VERSION ""

NS_ :

BS_:

BU_: FUSION ZONE_FR ZONE_DR D21_DKC ZONE_FR_24

BO_ 796 ZONE_FR1: 64 ZONE_FR
 SG_ BMSReqRlngCtrHSC6 : 7|4@0+ (1,0) [0|15] ""  FUSION
 SG_ BMSReqTapPosHSC6 : 3|4@0+ (1,0) [0|15] ""  FUSION
 SG_ BMSReqPwrHSC6 : 15|16@0+ (1,0) [0|65535] ""  FUSION
 SG_ BMSReqPWMHSC6 : 31|7@0+ (1,0) [0|100] ""  FUSION
 SG_ BMSInptClntTemHSC6 : 24|9@0+ (0.5,-40) [-40|200] ""  FUSION
 SG_ BMSChksmHSC6 : 47|8@0+ (1,0) [0|255] ""  FUSION
 SG_ BMSReqMdHSC6 : 71|2@0+ (1,0) [0|3] ""  FUSION
 SG_ BMSEnbPTCHSC6 : 69|1@0+ (1,0) [0|1] ""  FUSION
 SG_ FRTurnLampC : 151|8@0+ (10,0) [0|2550] "mA"  FUSION
 SG_ FLTurnLampC : 159|8@0+ (10,0) [0|2550] "mA"  FUSION
 SG_ ChargeInletLockSta : 55|1@0+ (1,0) [0|1] ""  FUSION
 SG_ FWiperAS : 175|1@0+ (1,0) [0|1] ""  FUSION
 SG_ FWiperProtection : 174|1@0+ (1,0) [0|1] ""  FUSION
 SG_ BDC_1_ReqMovePos : 143|8@0+ (0.392,0) [0|99.96] ""  FUSION
 SG_ BDC_1_MoveEnable : 173|1@0+ (1,0) [0|1] ""  FUSION
 SG_ CCV4_MoveEnable : 168|1@0+ (1,0) [0|1] ""  FUSION
 SG_ CCV4_ReqMovePos : 169|1@0+ (1,0) [0|1] ""  FUSION
 SG_ CCM_SpdCmd : 54|15@0+ (0.5,0) [0|8300] "RPM"  FUSION
 SG_ BMSPackVol_h6HSC6 : 67|12@0+ (0.25,0) [0|1023.75] "V"  FUSION
 SG_ CompProEN : 68|1@0+ (1,0) [0|1] ""  FUSION
 SG_ EXV_Cmd_Set_Rq : 87|16@0+ (1,0) [0|65535] ""  FUSION
 SG_ EXV2_Cmd_Set_Rq : 103|16@0+ (1,0) [0|65535] ""  FUSION
 SG_ EWP3_RPM_Target_EWP_Rq : 135|8@0+ (1,0) [0|254] ""  FUSION
 SG_ EWP2_RPM_Target_EWP_Rq : 127|8@0+ (1,0) [0|254] ""  FUSION
 SG_ EWP1_RPM_Target_EWP_Rq : 119|8@0+ (1,0) [0|254] ""  FUSION
 SG_ EXV2_Cmd_Init_Rq : 162|3@0+ (1,0) [0|7] ""  FUSION
 SG_ EXV_Cmd_Init_Rq : 165|3@0+ (1,0) [0|7] ""  FUSION
 SG_ EWP1_Default_Operation_EWP_Rq : 170|1@0+ (1,0) [0|1] ""  FUSION
 SG_ EWP2_Default_Operation_EWP_Rq : 171|1@0+ (1,0) [0|1] ""  FUSION
 SG_ EWP3_Default_Operation_EWP_Rq : 172|1@0+ (1,0) [0|1] ""  FUSION
 SG_ EXV2_Cmd_Move_Enbl : 167|1@0+ (1,0) [0|1] ""  FUSION
 SG_ EXV_Cmd_Move_Enbl : 166|1@0+ (1,0) [0|1] ""  FUSION
 SG_ TrailerModeSta : 189|2@0+ (1,0) [0|3] ""  FUSION
 SG_ TrailerCheck : 190|1@0+ (1,0) [0|1] ""  FUSION
 SG_ ZFR_BCM_ChargerDoorSW_Sta : 187|1@0+ (1,0) [0|1] ""  FUSION
 SG_ FLTurnLPErr : 198|1@0+ (1,0) [0|1] ""  FUSION
 SG_ FLTurn_Light_Warning : 203|1@0+ (1,0) [0|1] ""  FUSION
 SG_ FRPosLPErr : 213|1@0+ (1,0) [0|1] ""  FUSION
 SG_ FRTurnLPErr : 214|1@0+ (1,0) [0|1] ""  FUSION
 SG_ FRTurn_Light_Warning : 219|1@0+ (1,0) [0|1] ""  FUSION
 SG_ LADBErr : 194|1@0+ (1,0) [0|1] ""  FUSION
 SG_ LADB_Hibeam_Indication : 192|1@0+ (1,0) [0|1] ""  FUSION
 SG_ LADB_Operation_Status : 207|1@0+ (1,0) [0|1] ""  FUSION
 SG_ LADB_Warning : 206|1@0+ (1,0) [0|1] ""  FUSION
 SG_ LAHB_Warning : 204|1@0+ (1,0) [0|1] ""  FUSION
 SG_ LDRLErr : 193|1@0+ (1,0) [0|1] ""  FUSION
 SG_ LDRL_Warning : 202|1@0+ (1,0) [0|1] ""  FUSION
 SG_ LH_BeamErr : 195|1@0+ (1,0) [0|1] ""  FUSION
 SG_ LLB_Warning : 205|1@0+ (1,0) [0|1] ""  FUSION
 SG_ LL_BeamErr : 196|1@0+ (1,0) [0|1] ""  FUSION
 SG_ Lposition_Lamp_Warning : 199|1@0+ (1,0) [0|1] ""  FUSION
 SG_ RADBErr : 210|1@0+ (1,0) [0|1] ""  FUSION
 SG_ RADB_Hibeam_Indication : 208|1@0+ (1,0) [0|1] ""  FUSION
 SG_ RADB_Operation_Status : 223|1@0+ (1,0) [0|1] ""  FUSION
 SG_ RADB_Warning : 222|1@0+ (1,0) [0|1] ""  FUSION
 SG_ RAHB_Warning : 220|1@0+ (1,0) [0|1] ""  FUSION
 SG_ RDRLErr : 209|1@0+ (1,0) [0|1] ""  FUSION
 SG_ RDRL_Warning : 218|1@0+ (1,0) [0|1] ""  FUSION
 SG_ RH_BeamErr : 211|1@0+ (1,0) [0|1] ""  FUSION
 SG_ RLB_Warning : 221|1@0+ (1,0) [0|1] ""  FUSION
 SG_ RL_BeamErr : 212|1@0+ (1,0) [0|1] ""  FUSION
 SG_ Rposition_Lamp_Warning : 215|1@0+ (1,0) [0|1] ""  FUSION
 SG_ FLPosLPErr : 197|1@0+ (1,0) [0|1] ""  FUSION
 SG_ ZFR_THCM_CLEVentActZ_Sta : 270|7@0+ (1,0) [0|127] "%"  FUSION
 SG_ ZFR_THCM_CREVentActY_Sta : 278|7@0+ (1,0) [0|127] "%"  FUSION
 SG_ ZFR_THCM_CREVentActZ_Sta : 286|7@0+ (1,0) [0|127] "%"  FUSION
 SG_ ZFR_THCM_DrEVentActY_Sta : 230|7@0+ (1,0) [0|127] "%"  FUSION
 SG_ ZFR_THCM_DrEVentActZ_Sta : 238|7@0+ (1,0) [0|127] "%"  FUSION
 SG_ ZFR_THCM_PsEVentActY_Sta : 246|7@0+ (1,0) [0|127] "%"  FUSION
 SG_ ZFR_THCM_PsEVentActZ_Sta : 254|7@0+ (1,0) [0|127] "%"  FUSION
 SG_ ZFR_THCM_CLEVentActY_Sta : 262|7@0+ (1,0) [0|127] "%"  FUSION
 SG_ ZFR_EChrg_Active_Sta : 186|3@0+ (1,0) [0|7] ""  FUSION
 SG_ ZFR_EChrg_Sys_Sta : 201|2@0+ (1,0) [0|3] ""  FUSION

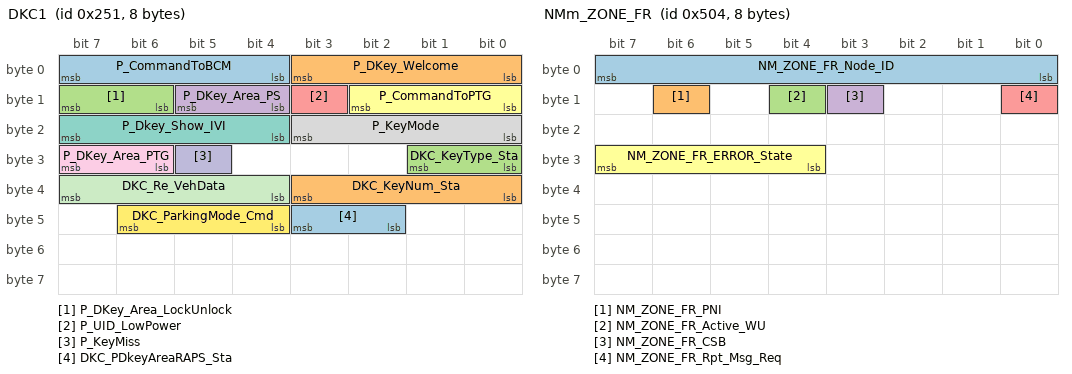
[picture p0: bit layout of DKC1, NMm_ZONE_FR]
BO_ 593 DKC1: 8 D21_DKC
 SG_ P_CommandToBCM : 7|4@0+ (1,0) [0|15] ""  FUSION
 SG_ P_DKey_Welcome : 3|4@0+ (1,0) [0|15] ""  FUSION
 SG_ P_DKey_Area_LockUnlock : 15|2@0+ (1,0) [0|3] ""  FUSION
 SG_ P_DKey_Area_PS : 13|2@0+ (1,0) [0|3] ""  FUSION
 SG_ P_UID_LowPower : 11|1@0+ (1,0) [0|1] ""  FUSION
 SG_ P_CommandToPTG : 10|3@0+ (1,0) [0|5] ""  FUSION
 SG_ P_Dkey_Show_IVI : 23|4@0+ (1,0) [0|15] ""  FUSION
 SG_ P_KeyMode : 19|4@0+ (1,0) [0|15] ""  FUSION
 SG_ P_DKey_Area_PTG : 31|2@0+ (1,0) [0|3] ""  FUSION
 SG_ P_KeyMiss : 29|1@0+ (1,0) [0|1] ""  FUSION
 SG_ DKC_Re_VehData : 39|4@0+ (1,0) [0|15] ""  FUSION
 SG_ DKC_ParkingMode_Cmd : 46|3@0+ (1,0) [0|4] ""  FUSION
 SG_ DKC_PDkeyAreaRAPS_Sta : 43|2@0+ (1,0) [0|3] ""  FUSION
 SG_ DKC_KeyNum_Sta : 35|4@0+ (1,0) [0|15] ""  FUSION
 SG_ DKC_KeyType_Sta : 25|2@0+ (1,0) [0|3] ""  FUSION

BO_ 594 DKC2: 24 D21_DKC
 SG_ Random_Number_X : 7|64@0+ (1,0) [0|1.84467440737096E+019] ""  FUSION
 SG_ EncryptionDATA_64_127 : 71|64@0+ (1,0) [0|1.84467440737096E+019] ""  FUSION
 SG_ EncryptionDATA_0_63 : 135|64@0+ (1,0) [0|1.84467440737096E+019] ""  FUSION

BO_ 596 zGW_LINFr2: 32 ZONE_FR
 SG_ EXV_Rsp_Pos : 7|16@0+ (1,0) [0|576] ""  FUSION
 SG_ EXV_Rsp_Fault_Stat : 23|4@0+ (1,0) [0|1] ""  FUSION
 SG_ EXV_Rsp_CurInit_Stat : 19|2@0+ (1,0) [0|1] ""  FUSION
 SG_ EXV_Rsp_OvrTemp_Warn : 17|2@0+ (1,0) [0|1] ""  FUSION
 SG_ EXV_Rsp_Volt_Stat : 31|2@0+ (1,0) [0|1] ""  FUSION
 SG_ EXV_RsErr_EXV : 29|1@0+ (1,0) [0|1] ""  FUSION
 SG_ EXV_Rsp_Run_Stat : 28|1@0+ (1,0) [0|1] ""  FUSION
 SG_ EWP1_RsErr_EWP : 26|1@0+ (1,0) [0|1] ""  FUSION
 SG_ EWP1_SupVolt_Error : 25|2@0+ (1,0) [0|2] ""  FUSION
 SG_ EWP1_RPM_Target_Stat : 39|8@0+ (1,0) [0|255] ""  FUSION
 SG_ EWP1_RPM_ActlVal_Stat : 47|8@0+ (1,0) [0|255] ""  FUSION
 SG_ EWP1_Curr_Stat : 55|8@0+ (0.1,0) [0|25.5] "A"  FUSION
 SG_ EWP1_Block_Error : 63|2@0+ (1,0) [0|3] ""  FUSION
 SG_ EWP1_DryRun_Error : 61|2@0+ (1,0) [0|3] ""  FUSION
 SG_ EWP1_OverCurr_Error : 59|2@0+ (1,0) [0|3] ""  FUSION
 SG_ EWP1_OverTemp_Error : 57|2@0+ (1,0) [0|2] ""  FUSION
 SG_ EWP1_Temp_Stat : 71|8@0+ (1,-50) [-50|205] "Deg"  FUSION
 SG_ EWP1_Volt_Stat : 79|8@0+ (0.1,0) [0|25.5] "V"  FUSION
 SG_ EWP2_Volt_Stat : 87|8@0+ (0.1,0) [0|25.5] "V"  FUSION
 SG_ EWP2_Temp_Stat : 95|8@0+ (1,-50) [-50|205] "Deg"  FUSION
 SG_ EWP2_RPM_Target_Stat : 103|8@0+ (1,0) [0|255] ""  FUSION
 SG_ EWP2_RPM_ActlVal_Stat : 111|8@0+ (1,0) [0|255] ""  FUSION
 SG_ EWP2_Curr_Stat : 119|8@0+ (0.1,0) [0|25.5] "A"  FUSION
 SG_ EWP2_Block_Error : 127|2@0+ (1,0) [0|3] ""  FUSION
 SG_ EWP2_DryRun_Error : 125|2@0+ (1,0) [0|3] ""  FUSION
 SG_ EWP2_OverCurr_Error : 123|2@0+ (1,0) [0|3] ""  FUSION
 SG_ EWP2_OverTemp_Error : 121|2@0+ (1,0) [0|2] ""  FUSION
 SG_ EWP2_SupVolt_Error : 135|2@0+ (1,0) [0|2] ""  FUSION
 SG_ EWP2_RsErr_EWP : 133|1@0+ (1,0) [0|1] ""  FUSION
 SG_ EWP3_Block_Error : 131|2@0+ (1,0) [0|3] ""  FUSION
 SG_ EWP3_DryRun_Error : 129|2@0+ (1,0) [0|3] ""  FUSION
 SG_ EWP3_RPM_Target_Stat : 143|8@0+ (1,0) [0|255] ""  FUSION
 SG_ EWP3_RPM_ActlVal_Stat : 151|8@0+ (1,0) [0|255] ""  FUSION
 SG_ EWP3_Curr_Stat : 159|8@0+ (0.1,0) [0|25.5] "A"  FUSION
 SG_ EWP3_OverCurr_Error : 167|2@0+ (1,0) [0|3] ""  FUSION
 SG_ EWP3_OverTemp_Error : 165|2@0+ (1,0) [0|2] ""  FUSION
 SG_ EWP3_SupVolt_Error : 163|2@0+ (1,0) [0|2] ""  FUSION
 SG_ EWP3_RsErr_EWP : 161|1@0+ (1,0) [0|1] ""  FUSION
 SG_ EWP3_Temp_Stat : 175|8@0+ (1,-50) [-50|205] "Deg"  FUSION
 SG_ EWP3_Volt_Stat : 183|8@0+ (0.1,0) [0|25.5] "V"  FUSION
 SG_ EXV2_Rsp_Pos : 191|16@0+ (1,0) [0|576] ""  FUSION
 SG_ EXV2_Rsp_Fault_Stat : 207|4@0+ (1,0) [0|1] ""  FUSION
 SG_ EXV2_Rsp_CurInit_Stat : 203|2@0+ (1,0) [0|1] ""  FUSION
 SG_ EXV2_Rsp_OvrTemp_Warn : 201|2@0+ (1,0) [0|1] ""  FUSION
 SG_ EXV2_Rsp_Volt_Stat : 215|2@0+ (1,0) [0|1] ""  FUSION
 SG_ EXV2_RsErr_EXV : 213|1@0+ (1,0) [0|1] ""  FUSION
 SG_ EXV2_Rsp_Run_Stat : 212|1@0+ (1,0) [0|1] ""  FUSION
 SG_ CCV4_Fault_Signal : 211|4@0+ (1,0) [0|1] ""  FUSION
 SG_ BDC_1_Rsp_Comm_Err : 223|1@0+ (1,0) [0|1] ""  FUSION
 SG_ CCV4_TempWarn : 222|1@0+ (1,0) [0|1] ""  FUSION
 SG_ CCV4_Rsp_Comm_Err : 221|1@0+ (1,0) [0|1] ""  FUSION
 SG_ CCV4_MotorStatus : 220|1@0+ (1,0) [0|1] ""  FUSION
 SG_ CCV4_RespPos : 219|2@0+ (1,0) [0|1] ""  FUSION
 SG_ CCV4_voltageErr : 217|2@0+ (1,0) [0|1] ""  FUSION
 SG_ BDC_1_Fault_Signal : 231|4@0+ (1,0) [0|1] ""  FUSION
 SG_ BDC_1_voltageErr : 227|2@0+ (1,0) [0|1] ""  FUSION
 SG_ BDC_1_TempWarn : 225|1@0+ (1,0) [0|1] ""  FUSION
 SG_ BDC_1_MotorStatus : 224|1@0+ (1,0) [0|1] ""  FUSION
 SG_ BDC_1_RespPos : 239|8@0+ (0.392,0) [0|99.96] ""  FUSION

BO_ 778 zGW_CANFr1: 32 ZONE_FR
 SG_ PTCActuPWMDutyHSC6 : 7|8@0+ (0.5,0) [0|100] ""  FUSION
 SG_ PTCIGBTTemHSC6 : 15|9@0+ (0.5,-40) [-40|200] ""  FUSION
 SG_ EAC_Temp : 39|8@0+ (1,-40) [0|210] "Deg^C"  FUSION
 SG_ PTCNTCStsHSC6 : 164|3@0+ (1,0) [0|7] ""  FUSION
 SG_ EAC_DrvVoltFalt : 63|1@0+ (1,0) [0|1] ""  FUSION
 SG_ EAC_MotorLackFalt : 62|1@0+ (1,0) [0|1] ""  FUSION
 SG_ EAC_OvLoadFalt : 61|1@0+ (1,0) [0|1] ""  FUSION
 SG_ EAC_TempSnsrFalt : 60|1@0+ (1,0) [0|1] ""  FUSION
 SG_ COMP_ComLost : 58|1@0+ (1,0) [0|1] ""  FUSION
 SG_ COMP_IPM_HWFLt : 57|1@0+ (1,0) [0|1] ""  FUSION
 SG_ COMP_IPM_TempOverFlt : 56|1@0+ (1,0) [0|1] ""  FUSION
 SG_ COMP_CurOverProtect : 71|1@0+ (1,0) [0|1] ""  FUSION
 SG_ COMP_VoltOverErr : 70|1@0+ (1,0) [0|1] ""  FUSION
 SG_ COMP_VoltLessErr : 69|1@0+ (1,0) [0|1] ""  FUSION
 SG_ COMP_CtrlCircFlt : 68|1@0+ (1,0) [0|1] ""  FUSION
 SG_ COMP_Sta : 67|2@0+ (1,0) [0|3] ""  FUSION
 SG_ COMP_Init : 65|1@0+ (1,0) [0|1] ""  FUSION
 SG_ COMP_SpdVaild : 64|1@0+ (1,0) [0|1] ""  FUSION
 SG_ EAC_MotCrt : 79|8@0+ (0.2,0) [0|51] "A"  FUSION
 SG_ COMP_CurVaild : 87|1@0+ (1,0) [0|1] ""  FUSION
 SG_ COMP_VoltVaild : 86|1@0+ (1,0) [0|1] ""  FUSION
 SG_ COMP_StatorSpd : 85|14@0+ (1,0) [0|8500] "RPM"  FUSION
 SG_ COMP_ConCur : 103|16@0+ (0.02,0) [0|1310.7] "A"  FUSION
 SG_ COMP_ConVolt : 119|16@0+ (0.02,0) [0|1310.7] "V"  FUSION
 SG_ PTCSecRlngCtrHSC6 : 135|4@0+ (1,0) [0|15] ""  FUSION
 SG_ PTCOverVolHSC6 : 131|1@0+ (1,0) [0|1] ""  FUSION
 SG_ PTCOverCrntHSC6 : 130|1@0+ (1,0) [0|1] ""  FUSION
 SG_ PTCOverHeatHSC6 : 129|1@0+ (1,0) [0|1] ""  FUSION
 SG_ PTCOtptTemHSC6 : 128|9@0+ (0.5,-40) [-40|200] ""  FUSION
 SG_ PTCRlngCtrHSC6 : 151|4@0+ (1,0) [0|15] ""  FUSION
 SG_ PTCIGBTStsHSC6 : 147|1@0+ (1,0) [0|1] ""  FUSION
 SG_ PTCHVLckStsHSC6 : 146|1@0+ (1,0) [0|1] ""  FUSION
 SG_ PTCIGBTOverHeatHSC6 : 145|1@0+ (1,0) [0|1] ""  FUSION
 SG_ PTCPCBTemHSC6 : 144|9@0+ (0.5,-40) [-40|200] ""  FUSION
 SG_ PTCUnderVolHSC6 : 167|1@0+ (1,0) [0|1] ""  FUSION
 SG_ PTCStsHSC6 : 166|2@0+ (1,0) [0|3] ""  FUSION
 SG_ PTCActuCrntHSC6 : 161|10@0+ (0.1,-20) [-20|82] ""  FUSION
 SG_ PTCChksmHSC6 : 183|8@0+ (1,0) [0|255] ""  FUSION
 SG_ PTCSecChksmHSC6 : 191|8@0+ (1,0) [0|255] ""  FUSION
 SG_ PTCFltLvlHSC6 : 199|4@0+ (1,0) [0|15] ""  FUSION
 SG_ PTCActuVolHSC6 : 193|10@0+ (0.5,100) [100|500] ""  FUSION
 SG_ PTCActuPwrHSC6 : 47|16@0+ (1,0) [0|65535] ""  FUSION
 SG_ COMP_ActualPwr : 228|13@0+ (1,0) [0|6000] "W"  FUSION
 SG_ PTC1_PowerConsumption : 31|8@0+ (0.1,0) [0|25.3] "KW"  FUSION

BO_ 804 zGW_LINDr2: 48 ZONE_DR
 SG_ ACT5_Stop_mode_status : 71|2@0+ (1,0) [0|3] ""  FUSION
 SG_ ACT5_Rotation_direction_status : 69|2@0+ (1,0) [0|3] ""  FUSION
 SG_ ACT5_Emergency_run_position_stat : 67|2@0+ (1,0) [0|3] ""  FUSION
 SG_ ACT5_Emergency_run_release_statu : 65|2@0+ (1,0) [0|3] ""  FUSION
 SG_ ACT5_Actuator_address_status : 79|8@0+ (1,0) [0|255] ""  FUSION
 SG_ ACT5_Special_functions : 85|2@0+ (1,0) [0|3] ""  FUSION
 SG_ ACT5_Self_holding_torque : 83|2@0+ (1,0) [0|3] ""  FUSION
 SG_ ACT5_Movement_direction : 81|2@0+ (1,0) [0|3] ""  FUSION
 SG_ ACT5_Actual_position_of_actuator : 95|16@0+ (1,0) [0|65535] ""  FUSION
 SG_ ACT5_Speed_status : 111|4@0+ (1,0) [0|15] ""  FUSION
 SG_ ACT5_Position_specification_stat : 107|2@0+ (1,0) [0|3] ""  FUSION
 SG_ ACT5_Applied_holding_current_sta : 105|2@0+ (1,0) [0|3] ""  FUSION
 SG_ ACT5_Reset : 119|2@0+ (1,0) [0|3] ""  FUSION
 SG_ ACT5_Stall_occurred : 117|2@0+ (1,0) [0|3] ""  FUSION
 SG_ ACT5_Stall_detection_release_sta : 115|2@0+ (1,0) [0|3] ""  FUSION
 SG_ ACT5_Emergency_run_occurred : 113|2@0+ (1,0) [0|3] ""  FUSION
 SG_ ACT5_Supply_voltage : 127|2@0+ (1,0) [0|3] ""  FUSION
 SG_ ACT5_Electrical_defect : 125|2@0+ (1,0) [0|3] ""  FUSION
 SG_ ACT5_Over_temperature : 123|2@0+ (1,0) [0|3] ""  FUSION
 SG_ ACT5_Response_Error : 120|1@0+ (1,0) [0|1] ""  FUSION
 SG_ ACT4_Stop_mode_status : 135|2@0+ (1,0) [0|3] ""  FUSION
 SG_ ACT4_Rotation_direction_status : 133|2@0+ (1,0) [0|3] ""  FUSION
 SG_ ACT4_Emergency_run_position_stat : 131|2@0+ (1,0) [0|3] ""  FUSION
 SG_ ACT4_Emergency_run_release_statu : 129|2@0+ (1,0) [0|3] ""  FUSION
 SG_ ACT4_Actuator_address_status : 143|8@0+ (1,0) [0|255] ""  FUSION
 SG_ ACT4_Special_functions : 149|2@0+ (1,0) [0|3] ""  FUSION
 SG_ ACT4_Self_holding_torque : 147|2@0+ (1,0) [0|3] ""  FUSION
 SG_ ACT4_Movement_direction : 145|2@0+ (1,0) [0|3] ""  FUSION
 SG_ ACT4_Actual_position_of_actuator : 159|16@0+ (1,0) [0|65535] ""  FUSION
 SG_ ACT4_Speed_status : 175|4@0+ (1,0) [0|15] ""  FUSION
 SG_ ACT4_Position_specification_stat : 171|2@0+ (1,0) [0|3] ""  FUSION
 SG_ ACT4_Applied_holding_current_sta : 169|2@0+ (1,0) [0|3] ""  FUSION
 SG_ ACT4_Reset : 183|2@0+ (1,0) [0|3] ""  FUSION
 SG_ ACT4_Stall_occurred : 181|2@0+ (1,0) [0|3] ""  FUSION
 SG_ ACT4_Stall_detection_release_sta : 179|2@0+ (1,0) [0|3] ""  FUSION
 SG_ ACT4_Emergency_run_occurred : 177|2@0+ (1,0) [0|3] ""  FUSION
 SG_ ACT4_Supply_voltage : 191|2@0+ (1,0) [0|3] ""  FUSION
 SG_ ACT4_Electrical_defect : 189|2@0+ (1,0) [0|3] ""  FUSION
 SG_ ACT4_Over_temperature : 187|2@0+ (1,0) [0|3] ""  FUSION
 SG_ ACT4_Response_Error : 184|1@0+ (1,0) [0|1] ""  FUSION
 SG_ ACT3_Stop_mode_status : 199|2@0+ (1,0) [0|3] ""  FUSION
 SG_ ACT3_Rotation_direction_status : 197|2@0+ (1,0) [0|3] ""  FUSION
 SG_ ACT3_Emergency_run_position_stat : 195|2@0+ (1,0) [0|3] ""  FUSION
 SG_ ACT3_Emergency_run_release_statu : 193|2@0+ (1,0) [0|3] ""  FUSION
 SG_ ACT3_Actuator_address_status : 207|8@0+ (1,0) [0|255] ""  FUSION
 SG_ ACT3_Special_functions : 213|2@0+ (1,0) [0|3] ""  FUSION
 SG_ ACT3_Self_holding_torque : 211|2@0+ (1,0) [0|3] ""  FUSION
 SG_ ACT3_Movement_direction : 209|2@0+ (1,0) [0|3] ""  FUSION
 SG_ ACT3_Actual_position_of_actuator : 223|16@0+ (1,0) [0|65535] ""  FUSION
 SG_ ACT3_Speed_status : 239|4@0+ (1,0) [0|15] ""  FUSION
 SG_ ACT3_Position_specification_stat : 235|2@0+ (1,0) [0|3] ""  FUSION
 SG_ ACT3_Applied_holding_current_sta : 233|2@0+ (1,0) [0|3] ""  FUSION
 SG_ ACT3_Reset : 247|2@0+ (1,0) [0|3] ""  FUSION
 SG_ ACT3_Stall_occurred : 245|2@0+ (1,0) [0|3] ""  FUSION
 SG_ ACT3_Stall_detection_release_sta : 243|2@0+ (1,0) [0|3] ""  FUSION
 SG_ ACT3_Emergency_run_occurred : 241|2@0+ (1,0) [0|3] ""  FUSION
 SG_ ACT3_Supply_voltage : 255|2@0+ (1,0) [0|3] ""  FUSION
 SG_ ACT3_Electrical_defect : 253|2@0+ (1,0) [0|3] ""  FUSION
 SG_ ACT3_Over_temperature : 251|2@0+ (1,0) [0|3] ""  FUSION
 SG_ ACT3_Response_Error : 248|1@0+ (1,0) [0|1] ""  FUSION
 SG_ ACT2_Stop_mode_status : 263|2@0+ (1,0) [0|3] ""  FUSION
 SG_ ACT2_Rotation_direction_status : 261|2@0+ (1,0) [0|3] ""  FUSION
 SG_ ACT2_Emergency_run_position_stat : 259|2@0+ (1,0) [0|3] ""  FUSION
 SG_ ACT2_Emergency_run_release_statu : 257|2@0+ (1,0) [0|3] ""  FUSION
 SG_ ACT2_Actuator_address_status : 271|8@0+ (1,0) [0|255] ""  FUSION
 SG_ ACT2_Special_functions : 277|2@0+ (1,0) [0|3] ""  FUSION
 SG_ ACT2_Self_holding_torque : 275|2@0+ (1,0) [0|3] ""  FUSION
 SG_ ACT2_Movement_direction : 273|2@0+ (1,0) [0|3] ""  FUSION
 SG_ ACT2_Actual_position_of_actuator : 287|16@0+ (1,0) [0|65535] ""  FUSION
 SG_ ACT2_Speed_status : 303|4@0+ (1,0) [0|15] ""  FUSION
 SG_ ACT2_Position_specification_stat : 299|2@0+ (1,0) [0|3] ""  FUSION
 SG_ ACT2_Applied_holding_current_sta : 297|2@0+ (1,0) [0|3] ""  FUSION
 SG_ ACT2_Reset : 311|2@0+ (1,0) [0|3] ""  FUSION
 SG_ ACT2_Stall_occurred : 309|2@0+ (1,0) [0|3] ""  FUSION
 SG_ ACT2_Stall_detection_release_sta : 307|2@0+ (1,0) [0|3] ""  FUSION
 SG_ ACT2_Emergency_run_occurred : 305|2@0+ (1,0) [0|3] ""  FUSION
 SG_ ACT2_Supply_voltage : 319|2@0+ (1,0) [0|3] ""  FUSION
 SG_ ACT2_Electrical_defect : 317|2@0+ (1,0) [0|3] ""  FUSION
 SG_ ACT2_Over_temperature : 315|2@0+ (1,0) [0|3] ""  FUSION
 SG_ ACT2_Response_Error : 312|1@0+ (1,0) [0|1] ""  FUSION
 SG_ ACT1_Stop_mode_status : 327|2@0+ (1,0) [0|3] ""  FUSION
 SG_ ACT1_Emergency_run_position_stat : 323|2@0+ (1,0) [0|3] ""  FUSION
 SG_ ACT1_Emergency_run_release_statu : 321|2@0+ (1,0) [0|3] ""  FUSION
 SG_ ACT1_Speed_status : 367|4@0+ (1,0) [0|15] ""  FUSION
 SG_ ACT1_Position_specification_stat : 363|2@0+ (1,0) [0|3] ""  FUSION
 SG_ ACT1_Applied_holding_current_sta : 361|2@0+ (1,0) [0|3] ""  FUSION
 SG_ ACT1_Stall_occurred : 373|2@0+ (1,0) [0|3] ""  FUSION
 SG_ ACT1_Stall_detection_release_sta : 371|2@0+ (1,0) [0|3] ""  FUSION
 SG_ ACT1_Supply_voltage : 383|2@0+ (1,0) [0|3] ""  FUSION
 SG_ ACT1_Actual_position_of_actuator : 351|16@0+ (1,0) [0|65535] ""  FUSION
 SG_ ACT1_Actuator_address_status : 335|8@0+ (1,0) [0|255] ""  FUSION
 SG_ ACT1_Electrical_defect : 381|2@0+ (1,0) [0|3] ""  FUSION
 SG_ ACT1_Emergency_run_occurred : 369|2@0+ (1,0) [0|3] ""  FUSION
 SG_ ACT1_Movement_direction : 337|2@0+ (1,0) [0|3] ""  FUSION
 SG_ ACT1_Over_temperature : 379|2@0+ (1,0) [0|3] ""  FUSION
 SG_ ACT1_Reset : 375|2@0+ (1,0) [0|3] ""  FUSION
 SG_ ACT1_Response_Error : 376|1@0+ (1,0) [0|1] ""  FUSION
 SG_ ACT1_Rotation_direction_status : 325|2@0+ (1,0) [0|3] ""  FUSION
 SG_ ACT1_Self_holding_torque : 339|2@0+ (1,0) [0|3] ""  FUSION
 SG_ ACT1_Special_functions : 341|2@0+ (1,0) [0|3] ""  FUSION

BO_ 965 ZONE_DR_Version: 48 ZONE_DR
 SG_ ZONE_DR_SW_Var1 : 135|8@0+ (1,0) [0|255] ""  FUSION
 SG_ ZONE_DR_SW_Country2 : 127|8@0+ (1,0) [0|255] ""  FUSION
 SG_ ZONE_DR_SW_Country1 : 119|8@0+ (1,0) [0|255] ""  FUSION
 SG_ ZONE_DR_SW_Patch2 : 111|8@0+ (1,0) [0|255] ""  FUSION
 SG_ ZONE_DR_SW_Patch1 : 103|8@0+ (1,0) [0|255] ""  FUSION
 SG_ ZONE_DR_SW_Minor2 : 95|8@0+ (1,0) [0|255] ""  FUSION
 SG_ ZONE_DR_SW_Minor1 : 87|8@0+ (1,0) [0|255] ""  FUSION
 SG_ ZONE_DR_SW_Major2 : 79|8@0+ (1,0) [0|255] ""  FUSION
 SG_ ZONE_DR_SW_Major1 : 71|8@0+ (1,0) [0|255] ""  FUSION
 SG_ ZONE_DR_SW_Controller2 : 63|8@0+ (1,0) [0|255] ""  FUSION
 SG_ ZONE_DR_SW_Controller1 : 55|8@0+ (1,0) [0|255] ""  FUSION
 SG_ ZONE_DR_SW_CarModel3 : 47|8@0+ (1,0) [0|255] ""  FUSION
 SG_ ZONE_DR_SW_CarModel2 : 39|8@0+ (1,0) [0|255] ""  FUSION
 SG_ ZONE_DR_SW_CarModel1 : 31|8@0+ (1,0) [0|255] ""  FUSION
 SG_ ZONE_DR_HW_Ver3 : 23|8@0+ (1,0) [0|255] ""  FUSION
 SG_ ZONE_DR_HW_Ver2 : 15|8@0+ (1,0) [0|255] ""  FUSION
 SG_ ZONE_DR_HW_Ver1 : 7|8@0+ (1,0) [0|255] ""  FUSION
 SG_ ZONE_DR_SW_dash1 : 191|8@0+ (1,0) [0|255] ""  FUSION
 SG_ ZONE_DR_SW_change1 : 199|8@0+ (1,0) [0|255] ""  FUSION
 SG_ ZONE_DR_SW_change2 : 207|8@0+ (1,0) [0|255] ""  FUSION
 SG_ ZONE_DR_SW_dash2 : 215|8@0+ (1,0) [0|255] ""  FUSION
 SG_ ZONE_DR_SW_SHA1 : 223|8@0+ (1,0) [0|255] ""  FUSION
 SG_ ZONE_DR_SW_SHA2 : 231|8@0+ (1,0) [0|255] ""  FUSION
 SG_ ZONE_DR_SW_SHA3 : 239|8@0+ (1,0) [0|255] ""  FUSION
 SG_ ZONE_DR_SW_SHA4 : 247|8@0+ (1,0) [0|255] ""  FUSION
 SG_ ZONE_DR_SW_SHA5 : 255|8@0+ (1,0) [0|255] ""  FUSION
 SG_ ZONE_DR_SW_SHA6 : 263|8@0+ (1,0) [0|255] ""  FUSION
 SG_ ZONE_DR_SW_SHA7 : 271|8@0+ (1,0) [0|255] ""  FUSION
 SG_ ZONE_DR_SW_SHA8 : 279|8@0+ (1,0) [0|255] ""  FUSION
 SG_ ZONE_DR_SW_Var5 : 183|8@0+ (1,0) [0|255] ""  FUSION
 SG_ ZONE_DR_SW_Var4 : 175|8@0+ (1,0) [0|255] ""  FUSION
 SG_ ZONE_DR_SW_Var3 : 167|8@0+ (1,0) [0|255] ""  FUSION
 SG_ ZONE_DR_SW_Var2 : 159|8@0+ (1,0) [0|255] ""  FUSION
 SG_ ZONE_DR_SW_ECUGen2 : 151|8@0+ (1,0) [0|255] ""  FUSION
 SG_ ZONE_DR_SW_ECUGen1 : 143|8@0+ (1,0) [0|255] ""  FUSION

BO_ 969 ZONE_FR_Version: 48 ZONE_FR
 SG_ ZONE_FR_SW_Var1 : 135|8@0+ (1,0) [0|255] ""  FUSION
 SG_ ZONE_FR_SW_Country2 : 127|8@0+ (1,0) [0|255] ""  FUSION
 SG_ ZONE_FR_SW_Country1 : 119|8@0+ (1,0) [0|255] ""  FUSION
 SG_ ZONE_FR_SW_Patch2 : 111|8@0+ (1,0) [0|255] ""  FUSION
 SG_ ZONE_FR_SW_Patch1 : 103|8@0+ (1,0) [0|255] ""  FUSION
 SG_ ZONE_FR_SW_Minor2 : 95|8@0+ (1,0) [0|255] ""  FUSION
 SG_ ZONE_FR_SW_Minor1 : 87|8@0+ (1,0) [0|255] ""  FUSION
 SG_ ZONE_FR_SW_Major2 : 79|8@0+ (1,0) [0|255] ""  FUSION
 SG_ ZONE_FR_SW_Major1 : 71|8@0+ (1,0) [0|255] ""  FUSION
 SG_ ZONE_FR_SW_Controller2 : 63|8@0+ (1,0) [0|255] ""  FUSION
 SG_ ZONE_FR_SW_Controller1 : 55|8@0+ (1,0) [0|255] ""  FUSION
 SG_ ZONE_FR_SW_CarModel3 : 47|8@0+ (1,0) [0|255] ""  FUSION
 SG_ ZONE_FR_SW_CarModel2 : 39|8@0+ (1,0) [0|255] ""  FUSION
 SG_ ZONE_FR_SW_CarModel1 : 31|8@0+ (1,0) [0|255] ""  FUSION
 SG_ ZONE_FR_HW_Ver3 : 23|8@0+ (1,0) [0|255] ""  FUSION
 SG_ ZONE_FR_HW_Ver2 : 15|8@0+ (1,0) [0|255] ""  FUSION
 SG_ ZONE_FR_HW_Ver1 : 7|8@0+ (1,0) [0|255] ""  FUSION
 SG_ ZONE_FR_SW_dash1 : 191|8@0+ (1,0) [0|255] ""  FUSION
 SG_ ZONE_FR_SW_change1 : 199|8@0+ (1,0) [0|255] ""  FUSION
 SG_ ZONE_FR_SW_change2 : 207|8@0+ (1,0) [0|255] ""  FUSION
 SG_ ZONE_FR_SW_dash2 : 215|8@0+ (1,0) [0|255] ""  FUSION
 SG_ ZONE_FR_SW_SHA1 : 223|8@0+ (1,0) [0|255] ""  FUSION
 SG_ ZONE_FR_SW_SHA2 : 231|8@0+ (1,0) [0|255] ""  FUSION
 SG_ ZONE_FR_SW_SHA3 : 239|8@0+ (1,0) [0|255] ""  FUSION
 SG_ ZONE_FR_SW_SHA4 : 247|8@0+ (1,0) [0|255] ""  FUSION
 SG_ ZONE_FR_SW_SHA5 : 255|8@0+ (1,0) [0|255] ""  FUSION
 SG_ ZONE_FR_SW_SHA6 : 263|8@0+ (1,0) [0|255] ""  FUSION
 SG_ ZONE_FR_SW_SHA7 : 271|8@0+ (1,0) [0|255] ""  FUSION
 SG_ ZONE_FR_SW_SHA8 : 279|8@0+ (1,0) [0|255] ""  FUSION
 SG_ ZONE_FR_SW_ECUGen2 : 151|8@0+ (1,0) [0|255] ""  FUSION
 SG_ ZONE_FR_SW_ECUGen1 : 143|8@0+ (1,0) [0|255] ""  FUSION
 SG_ ZONE_FR_SW_Var5 : 183|8@0+ (1,0) [0|255] ""  FUSION
 SG_ ZONE_FR_SW_Var4 : 175|8@0+ (1,0) [0|255] ""  FUSION
 SG_ ZONE_FR_SW_Var3 : 167|8@0+ (1,0) [0|255] ""  FUSION
 SG_ ZONE_FR_SW_Var2 : 159|8@0+ (1,0) [0|255] ""  FUSION

BO_ 1284 NMm_ZONE_FR: 8 ZONE_FR
 SG_ NM_ZONE_FR_Node_ID : 7|8@0+ (1,0) [0|127] ""  FUSION
 SG_ NM_ZONE_FR_PNI : 14|1@0+ (1,0) [0|1] ""  FUSION
 SG_ NM_ZONE_FR_Active_WU : 12|1@0+ (1,0) [0|1] ""  FUSION
 SG_ NM_ZONE_FR_CSB : 11|1@0+ (1,0) [0|1] ""  FUSION
 SG_ NM_ZONE_FR_Rpt_Msg_Req : 8|1@0+ (1,0) [0|1] ""  FUSION
 SG_ NM_ZONE_FR_ERROR_State : 31|4@0+ (1,0) [0|8] ""  FUSION

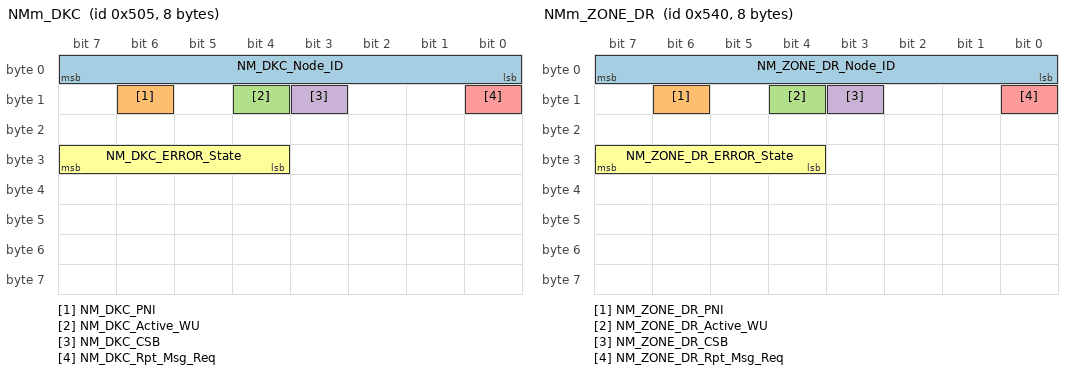
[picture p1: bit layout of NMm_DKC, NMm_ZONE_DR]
BO_ 1285 NMm_DKC: 8 D21_DKC
 SG_ NM_DKC_Node_ID : 7|8@0+ (1,0) [0|127] ""  FUSION
 SG_ NM_DKC_PNI : 14|1@0+ (1,0) [0|1] ""  FUSION
 SG_ NM_DKC_Active_WU : 12|1@0+ (1,0) [0|1] ""  FUSION
 SG_ NM_DKC_CSB : 11|1@0+ (1,0) [0|1] ""  FUSION
 SG_ NM_DKC_Rpt_Msg_Req : 8|1@0+ (1,0) [0|1] ""  FUSION
 SG_ NM_DKC_ERROR_State : 31|4@0+ (1,0) [0|8] ""  FUSION

BO_ 1344 NMm_ZONE_DR: 8 ZONE_DR
 SG_ NM_ZONE_DR_Node_ID : 7|8@0+ (1,0) [0|127] ""  FUSION
 SG_ NM_ZONE_DR_PNI : 14|1@0+ (1,0) [0|1] ""  FUSION
 SG_ NM_ZONE_DR_Active_WU : 12|1@0+ (1,0) [0|1] ""  FUSION
 SG_ NM_ZONE_DR_CSB : 11|1@0+ (1,0) [0|1] ""  FUSION
 SG_ NM_ZONE_DR_Rpt_Msg_Req : 8|1@0+ (1,0) [0|1] ""  FUSION
 SG_ NM_ZONE_DR_ERROR_State : 31|4@0+ (1,0) [0|8] ""  FUSION

BO_ 1540 DiagRespFromZONE_FR: 64 ZONE_FR
 SG_ DiagRespFromZONE_FR : 455|64@0+ (1,0) [0|0] ""  FUSION

BO_ 1541 DiagRespFromDKC: 32 D21_DKC
 SG_ DiagRespFromDKC : 7|64@0+ (1,0) [0|0] ""  FUSION

BO_ 1573 DiagRespFromAirPTC: 8 ZONE_DR
 SG_ DiagRespFromAirPTC : 7|64@0+ (1,0) [0|0] ""  FUSION

BO_ 1589 DiagRespFromWPTC: 8 ZONE_FR
 SG_ DiagRespFromWPTC : 7|64@0+ (1,0) [0|0] ""  FUSION

BO_ 1600 DiagRespFromZONE_DR: 64 ZONE_DR
 SG_ DiagRespFromZONE_DR : 455|64@0+ (1,0) [0|0] ""  FUSION

BO_ 1605 DiagRespFromCompressor: 8 ZONE_FR
 SG_ DiagRespFromCompress : 7|64@0+ (1,0) [0|0] ""  FUSION

BO_ 630 BMS5: 12 FUSION
 SG_ DCPortNeg_Temp : 7|8@0+ (1,-50) [-50|150] "Deg^C" Vector__XXX
 SG_ DCPortPos_Temp : 15|8@0+ (1,-50) [-50|150] "Deg^C" Vector__XXX
 SG_ OBCACCSLimit : 23|8@0+ (1,0) [0|80] "A" Vector__XXX
 SG_ HVInVolt : 28|13@0+ (0.1,0) [0|819] "V"  ZONE_DR
 SG_ OBCDCVoltLm : 44|13@0+ (0.1,0) [0|819] "V"  ZONE_DR
 SG_ OBCDCCurLm : 57|10@0+ (0.1,-25.5) [-25.5|76.7] "A"  ZONE_DR
 SG_ ReChargerStaFromEvcc : 59|2@0+ (1,0) [0|3] ""  ZONE_DR
 SG_ OBCEna : 60|1@0+ (1,0) [0|1] "" Vector__XXX
 SG_ LVBattDet12V : 79|8@0+ (0.1,0) [0|25.4] "V"  ZONE_DR,D21_DKC

BO_ 928 FD4_CE100_2: 32 FUSION
 SG_ FDC_VCU_ReqHWReset_Cmd : 20|5@0+ (1,0) [0|31] ""  ZONE_FR,ZONE_DR
 SG_ FD4_CE100_2_CS : 7|8@0+ (1,0) [0|255] ""  ZONE_FR,ZONE_DR
 SG_ FD4_CE100_2_RC : 11|4@0+ (1,0) [0|14] ""  ZONE_FR,ZONE_DR

BO_ 597 GW4_CE200_0: 32 FUSION
 SG_ IVI_MLSEATvent_Cmd : 10|3@0+ (1,0) [0|7] "" Vector__XXX
 SG_ IVI_MRSEATvent_Cmd : 26|3@0+ (1,0) [0|7] "" Vector__XXX
 SG_ IVI_MLFootLift_Cmd : 1|2@0+ (1,0) [0|3] "" Vector__XXX
 SG_ IVI_MLRecliner_Cmd : 7|2@0+ (1,0) [0|3] "" Vector__XXX
 SG_ IVI_MLSeatLift_Cmd : 5|2@0+ (1,0) [0|3] "" Vector__XXX
 SG_ IVI_MLSlider_Cmd : 3|2@0+ (1,0) [0|3] "" Vector__XXX
 SG_ IVI_MRFootLift_Cmd : 17|2@0+ (1,0) [0|3] "" Vector__XXX
 SG_ IVI_MRRecliner_Cmd : 23|2@0+ (1,0) [0|3] "" Vector__XXX
 SG_ IVI_MRSeatLift_Cmd : 21|2@0+ (1,0) [0|3] "" Vector__XXX
 SG_ IVI_MRSlider_Cmd : 19|2@0+ (1,0) [0|3] "" Vector__XXX
 SG_ IVI_MLFMost_Cmd : 13|1@0+ (1,0) [0|1] "" Vector__XXX
 SG_ IVI_MLNapMode_Cmd : 11|1@0+ (1,0) [0|1] "" Vector__XXX
 SG_ IVI_MLRestore_Cmd : 12|1@0+ (1,0) [0|1] "" Vector__XXX
 SG_ IVI_MLSldRestore_Cmd : 14|1@0+ (1,0) [0|1] "" Vector__XXX
 SG_ IVI_MLZeroGravity_Cmd : 15|1@0+ (1,0) [0|1] "" Vector__XXX
 SG_ IVI_MRFMost_Cmd : 29|1@0+ (1,0) [0|1] "" Vector__XXX
 SG_ IVI_MRNapMode_Cmd : 27|1@0+ (1,0) [0|1] "" Vector__XXX
 SG_ IVI_MRRestore_Cmd : 28|1@0+ (1,0) [0|1] "" Vector__XXX
 SG_ IVI_MRSldRestore_Cmd : 30|1@0+ (1,0) [0|1] "" Vector__XXX
 SG_ IVI_MRZeroGravity_Cmd : 31|1@0+ (1,0) [0|1] "" Vector__XXX
 SG_ IVI_LSEATvent_Cmd : 37|3@0+ (1,0) [0|7] "" Vector__XXX
 SG_ IVI_RSEATvent_Cmd : 34|3@0+ (1,0) [0|7] "" Vector__XXX

BO_ 513 FD4_CE100_3: 32 FUSION
 SG_ FDC_BCM_TurnLpLActive_Cmd : 11|1@0+ (1,0) [0|1] ""  ZONE_FR_24
 SG_ FDC_BCM_TurnLpRActive_Cmd : 10|1@0+ (1,0) [0|1] ""  ZONE_FR_24
 SG_ FDC_BCM_STurnLpLeft_Cmd : 13|1@0+ (1,0) [0|1] ""  ZONE_FR_24
 SG_ FDC_BCM_STurnLpRight_Cmd : 12|1@0+ (1,0) [0|1] ""  ZONE_FR_24
 SG_ FDC_BCM_LSMLP_Cmd : 2|1@0+ (1,0) [0|1] ""  ZONE_FR_24
 SG_ FDC_BCM_RSMLP_Cmd : 1|1@0+ (1,0) [0|1] ""  ZONE_FR_24
 SG_ FDC_BCM_BBuzzer_Cmd : 7|1@0+ (1,0) [0|1] ""  ZONE_FR_24
 SG_ FDC_BCM_BBuzzerout_Cmd : 6|1@0+ (1,0) [0|1] ""  ZONE_FR_24
 SG_ FDC_BCM_RevBuzzerout_Cmd : 0|1@0+ (1,0) [0|1] ""  ZONE_FR_24
 SG_ FDC_BCM_innerBuzzer_Cmd : 9|1@0+ (1,0) [0|1] ""  ZONE_FR_24
 SG_ FDC_BCM_EmExitLight_Cmd : 5|1@0+ (1,0) [0|1] ""  ZONE_FR_24
 SG_ FDC_BCM_FrRoomlamp_Cmd : 3|1@0+ (1,0) [0|1] ""  ZONE_FR_24
 SG_ FDC_BCM_RrRoomlamp_Cmd : 14|1@0+ (1,0) [0|1] ""  ZONE_FR_24
 SG_ FDC_BCM_FrAtmoLamp_Cmd : 4|1@0+ (1,0) [0|1] ""  ZONE_FR_24
 SG_ FDC_BCM_RrAtmoLamp_Cmd : 15|1@0+ (1,0) [0|1] ""  ZONE_FR_24
 SG_ FDC_BCM_FrRmLampBright_Cmd : 31|4@0+ (1,0) [0|15] ""  ZONE_FR_24
 SG_ FDC_BCM_RrRmLampBright_Cmd : 19|4@0+ (1,0) [0|15] ""  ZONE_FR_24
 SG_ FDC_BCM_IBuzzerReq_Sta : 23|4@0+ (1,0) [0|15] ""  ZONE_FR_24
 SG_ FDC_BCM_TgateHDSWR_Sta : 24|1@0+ (1,0) [0|1] ""  ZONE_FR,ZONE_DR,ZONE_FR_24
 SG_ FDC_BCM_TgateHDSWL_Sta : 25|1@0+ (1,0) [0|1] ""  ZONE_FR,ZONE_DR,ZONE_FR_24
 SG_ FDC_BCM_TgateSWL_Sta : 27|1@0+ (1,0) [0|1] ""  ZONE_FR,ZONE_DR,ZONE_FR_24
 SG_ FDC_BCM_TgateSWR_Sta : 26|1@0+ (1,0) [0|1] ""  ZONE_FR,ZONE_DR,ZONE_FR_24
 SG_ FDC_BCM_RTgateRel_Cmd : 8|1@0+ (1,0) [0|1] ""  ZONE_DR
 SG_ FDC_BCM_LTgateRel_Cmd : 39|1@0+ (1,0) [0|1] ""  ZONE_DR

BO_ 515 Z24_CE100_0: 32 ZONE_FR_24
 SG_ Z24_BCM_FLTurnLampC_Sta : 7|8@0+ (10,0) [0|2550] "mA"  FUSION
 SG_ Z24_BCM_FRTurnLampC_Sta : 15|8@0+ (10,0) [0|2550] "mA"  FUSION
 SG_ Z24_BCM_RLTurnLampC_Sta : 23|8@0+ (10,0) [0|2550] "mA"  FUSION
 SG_ Z24_BCM_RRTurnLampC_Sta : 31|8@0+ (10,0) [0|2550] "mA"  FUSION
 SG_ Z24_BCM_FWiperProtection_Sta : 39|1@0+ (1,0) [0|1] ""  FUSION
 SG_ Z24_BCM_FWiperAS_Sta : 38|1@0+ (1,0) [0|1] ""  FUSION
 SG_ Z24_BCM_EmExitOP_Sta : 37|1@0+ (1,0) [0|1] ""  FUSION
 SG_ Z24_BCM_innerBuzzer_Sta : 36|1@0+ (1,0) [0|1] ""  FUSION
 SG_ Z24_BCM_SeatBeltSW_Sta : 35|1@0+ (1,0) [0|1] ""  FUSION

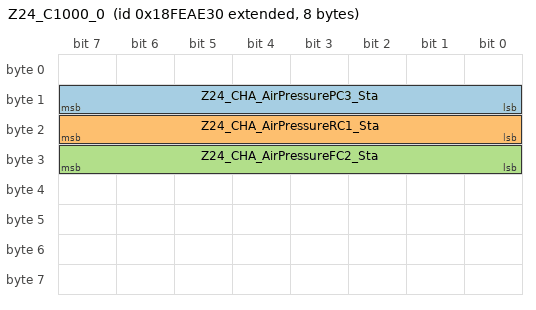
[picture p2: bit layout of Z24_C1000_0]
BO_ 2566827568 Z24_C1000_0: 8 ZONE_FR_24
 SG_ Z24_CHA_AirPressurePC3_Sta : 8|8@1+ (8,0) [0|1400] "KPa"  FUSION
 SG_ Z24_CHA_AirPressureRC1_Sta : 16|8@1+ (8,0) [0|1400] "KPa"  FUSION
 SG_ Z24_CHA_AirPressureFC2_Sta : 24|8@1+ (8,0) [0|1400] "KPa"  FUSION

BO_ 514 FD4_C100_0: 32 FUSION
 SG_ FDC_CHA_EACEnDemand_Cmd : 8|8@1+ (1,0) [0|255] ""  ZONE_FR_24

BO_ 1687 DiagPhysReqToZONE_FR_24: 64 FUSION
 SG_ DiagPhysReqToZONE_FR_24 : 455|64@0+ (1,0) [0|0] ""  ZONE_FR_24

BO_ 1559 DiagRespFromZONE_FR_24: 64 ZONE_FR_24
 SG_ DiagRespFromZONE_FR_24 : 455|64@0+ (1,0) [0|0] ""  FUSION

CM_ SG_ 796 FRTurnLampC "Front Right TurnLamp Current";
CM_ SG_ 796 FLTurnLampC "Front Left TurnLamp Current";
CM_ SG_ 796 ChargeInletLockSta "Charge Inlet lock signal status";
CM_ SG_ 796 FWiperAS "Front Wiper Auto Stop";
CM_ SG_ 796 FWiperProtection "Front Wiper Protection";
CM_ SG_ 796 CCM_SpdCmd "Target Speed of Compressor";
CM_ SG_ 796 CompProEN "Compressor protect enable";
CM_ SG_ 796 TrailerModeSta "Trailer Mode Status";
CM_ SG_ 796 TrailerCheck "Trailer Mode Check";
CM_ SG_ 796 ZFR_BCM_ChargerDoorSW_Sta "Charger Door Switch Status";
CM_ SG_ 796 FLTurnLPErr "Front Left Turn Lamp Error";
CM_ SG_ 796 FLTurn_Light_Warning "FLTurn Light_Warning";
CM_ SG_ 796 FRPosLPErr "Front Right PositionLamp Error";
CM_ SG_ 796 FRTurnLPErr "Front Right Turn Lamp Error";
CM_ SG_ 796 FRTurn_Light_Warning "FRTurn Light_Warning";
CM_ SG_ 796 LADBErr "Left ADB Error";
CM_ SG_ 796 LADB_Hibeam_Indication "LADB_Hibeam_Indication";
CM_ SG_ 796 LADB_Operation_Status "LADB_Operation_Status";
CM_ SG_ 796 LADB_Warning "LADB_Warning";
CM_ SG_ 796 LAHB_Warning "LAHB_Warning";
CM_ SG_ 796 LDRLErr "Left DRL Error";
CM_ SG_ 796 LDRL_Warning "LDRL_Warning";
CM_ SG_ 796 LH_BeamErr "Left High Beam Error";
CM_ SG_ 796 LLB_Warning "LLB_Warning";
CM_ SG_ 796 LL_BeamErr "Left Low Beam Error";
CM_ SG_ 796 Lposition_Lamp_Warning "LPosition Lamp_Warning";
CM_ SG_ 796 RADBErr "Right ADB Error";
CM_ SG_ 796 RADB_Hibeam_Indication "RADB_Hibeam_Indication";
CM_ SG_ 796 RADB_Operation_Status "RADB_Operation_Status";
CM_ SG_ 796 RADB_Warning "RADB_Warning";
CM_ SG_ 796 RAHB_Warning "RAHB_Warning";
CM_ SG_ 796 RDRLErr "Right DRL Error";
CM_ SG_ 796 RDRL_Warning "RDRL_Warning";
CM_ SG_ 796 RH_BeamErr "Right High Beam Error";
CM_ SG_ 796 RLB_Warning "RLB_Warning";
CM_ SG_ 796 RL_BeamErr "Right Low Beam Error";
CM_ SG_ 796 Rposition_Lamp_Warning "RPosition Lamp_Warning";
CM_ SG_ 796 FLPosLPErr "Front Left PositionLamp Error";
CM_ SG_ 796 ZFR_THCM_CLEVentActZ_Sta "Act Z Status of Electric Vent on CTR-LH";
CM_ SG_ 796 ZFR_THCM_CREVentActY_Sta "Act Y Status of Electric Vent on CTR-RH";
CM_ SG_ 796 ZFR_THCM_CREVentActZ_Sta "Act Z Status of Electric Vent on CTR-RH";
CM_ SG_ 796 ZFR_THCM_DrEVentActY_Sta "Act Y Status of Electric Vent on LH";
CM_ SG_ 796 ZFR_THCM_DrEVentActZ_Sta "Act Z Status of Electric Vent on LH";
CM_ SG_ 796 ZFR_THCM_PsEVentActY_Sta "Act Y Status of Electric Vent on RH";
CM_ SG_ 796 ZFR_THCM_PsEVentActZ_Sta "Act Z Status of Electric Vent on RH";
CM_ SG_ 796 ZFR_THCM_CLEVentActY_Sta "Act Y Status of Electric Vent on CTR-LH";
CM_ SG_ 796 ZFR_EChrg_Active_Sta "EChrgPort active State";
CM_ SG_ 796 ZFR_EChrg_Sys_Sta "EChrgPort system State";
CM_ SG_ 593 P_CommandToBCM "DKC command to BCM";
CM_ SG_ 593 P_DKey_Welcome "Digital key Welcome Area";
CM_ SG_ 593 P_DKey_Area_LockUnlock "Digital key  Lock and Unlock Area";
CM_ SG_ 593 P_DKey_Area_PS "Digital key PS Area";
CM_ SG_ 593 P_UID_LowPower "DKC UID low battery display";
CM_ SG_ 593 P_CommandToPTG "DKC command to PTG";
CM_ SG_ 593 P_Dkey_Show_IVI "Digital key IVI Show";
CM_ SG_ 593 P_KeyMode "DKC Key control Mode";
CM_ SG_ 593 P_DKey_Area_PTG "Digital key PTG Area";
CM_ SG_ 593 P_KeyMiss "DKC Key Miss";
CM_ SG_ 593 DKC_Re_VehData "Request for Remote VehData by DKC";
CM_ SG_ 593 DKC_ParkingMode_Cmd "DKC Parking Mode";
CM_ SG_ 593 DKC_PDkeyAreaRAPS_Sta "DKC RAPS Area";
CM_ SG_ 593 DKC_KeyNum_Sta "DKC current key number";
CM_ SG_ 593 DKC_KeyType_Sta "DKC current key type";
CM_ SG_ 594 Random_Number_X "DKC Random Number X";
CM_ SG_ 594 EncryptionDATA_64_127 "DKC Encryption DATA 64_127";
CM_ SG_ 594 EncryptionDATA_0_63 "DKC Encryption DATA 0-63";
CM_ BO_ 596 "Routing from LIN_FR2";
CM_ SG_ 778 EAC_Temp "Compressor Controller Temperature";
CM_ SG_ 778 EAC_DrvVoltFalt "15V Drive Voltage Failure";
CM_ SG_ 778 EAC_MotorLackFalt "Compressor Phase Loss Fault";
CM_ SG_ 778 EAC_OvLoadFalt "Compressor Overload Fault";
CM_ SG_ 778 EAC_TempSnsrFalt "Controller Temperature Sensor Failure";
CM_ SG_ 778 COMP_ComLost "Lost Communication on Compressor";
CM_ SG_ 778 COMP_IPM_HWFLt "Fault Detection on Compressor of IPM Hardware";
CM_ SG_ 778 COMP_IPM_TempOverFlt "Fault Detection on Compressor of IPM Temperature Too High";
CM_ SG_ 778 COMP_CurOverProtect "Fault Detection on Compressor OverCurrent Protection";
CM_ SG_ 778 COMP_VoltOverErr "OverVoltage Fault Detection on  High-Voltage DC bus";
CM_ SG_ 778 COMP_VoltLessErr "LessVoltage Fault Detection on  High-Voltage DC bus";
CM_ SG_ 778 COMP_CtrlCircFlt "Compressor Controller Fault Detection status";
CM_ SG_ 778 COMP_Sta "Current State of Compressor";
CM_ SG_ 778 COMP_Init "Compressor Initialization Status";
CM_ SG_ 778 COMP_SpdVaild "Validity of Reported Speed of Compressor";
CM_ SG_ 778 EAC_MotCrt "Phase Current Value";
CM_ SG_ 778 COMP_CurVaild "Validity of Compressor Reporting HVDC Bus Current";
CM_ SG_ 778 COMP_VoltVaild "Validity of Compressor Reporting HVDC Bus Voltage";
CM_ SG_ 778 COMP_StatorSpd "Compressor Report Speed";
CM_ SG_ 778 COMP_ConCur "Compressor Reports HVDC Bus Current";
CM_ SG_ 778 COMP_ConVolt "Compressor Reports HVDC Bus Voltage";
CM_ SG_ 778 PTCStsHSC6 "Positive Temperature Coefficient Status";
CM_ SG_ 778 PTCFltLvlHSC6 "Positive Temperature Coefficient Fault level";
CM_ SG_ 778 COMP_ActualPwr "COMP actual power";
CM_ SG_ 778 PTC1_PowerConsumption "WPTC_PowerConsumption";
CM_ BO_ 804 "Routing from LIN_DR4";
CM_ SG_ 965 ZONE_DR_SW_Var1 "software version car model variation 1";
CM_ SG_ 965 ZONE_DR_SW_Country2 "software version country of target market character 2";
CM_ SG_ 965 ZONE_DR_SW_Country1 "software version country of target market character 1";
CM_ SG_ 965 ZONE_DR_SW_Patch2 "software version patch character 2";
CM_ SG_ 965 ZONE_DR_SW_Patch1 "software version patch character 1";
CM_ SG_ 965 ZONE_DR_SW_Minor2 "software version minor character 2";
CM_ SG_ 965 ZONE_DR_SW_Minor1 "software version minor character 1";
CM_ SG_ 965 ZONE_DR_SW_Major2 "software version major character 2";
CM_ SG_ 965 ZONE_DR_SW_Major1 "software version major character 1";
CM_ SG_ 965 ZONE_DR_SW_Controller2 "software version controller character 2";
CM_ SG_ 965 ZONE_DR_SW_Controller1 "software version controller character 1";
CM_ SG_ 965 ZONE_DR_SW_CarModel3 "software version car model character 3";
CM_ SG_ 965 ZONE_DR_SW_CarModel2 "software version car model character 2";
CM_ SG_ 965 ZONE_DR_SW_CarModel1 "software version car model character 1";
CM_ SG_ 965 ZONE_DR_HW_Ver3 "ZONE_DR hardware version character 3";
CM_ SG_ 965 ZONE_DR_HW_Ver2 "ZONE_DR hardware version character 2";
CM_ SG_ 965 ZONE_DR_HW_Ver1 "ZONE_DR hardware version character 1";
CM_ SG_ 965 ZONE_DR_SW_dash1 "software version dash character 1";
CM_ SG_ 965 ZONE_DR_SW_change1 "software version number of change 1";
CM_ SG_ 965 ZONE_DR_SW_change2 "software version number of change 2";
CM_ SG_ 965 ZONE_DR_SW_dash2 "software version dash character 2";
CM_ SG_ 965 ZONE_DR_SW_SHA1 "software version SHA character 1";
CM_ SG_ 965 ZONE_DR_SW_SHA2 "software version SHA character 2";
CM_ SG_ 965 ZONE_DR_SW_SHA3 "software version SHA character 3";
CM_ SG_ 965 ZONE_DR_SW_SHA4 "software version SHA character 4";
CM_ SG_ 965 ZONE_DR_SW_SHA5 "software version SHA character 5";
CM_ SG_ 965 ZONE_DR_SW_SHA6 "software version SHA character 6";
CM_ SG_ 965 ZONE_DR_SW_SHA7 "software version SHA character 7";
CM_ SG_ 965 ZONE_DR_SW_SHA8 "software version SHA character 8";
CM_ SG_ 965 ZONE_DR_SW_Var5 "software version car model variation 5";
CM_ SG_ 965 ZONE_DR_SW_Var4 "software version car model variation 4";
CM_ SG_ 965 ZONE_DR_SW_Var3 "software version car model variation 3";
CM_ SG_ 965 ZONE_DR_SW_Var2 "software version car model variation 2";
CM_ SG_ 965 ZONE_DR_SW_ECUGen2 "ECU generation 2";
CM_ SG_ 965 ZONE_DR_SW_ECUGen1 "ECU generation 1";
CM_ SG_ 969 ZONE_FR_SW_Var1 "software version car model variation 1";
CM_ SG_ 969 ZONE_FR_SW_Country2 "software version country of target market character 2";
CM_ SG_ 969 ZONE_FR_SW_Country1 "software version country of target market character 1";
CM_ SG_ 969 ZONE_FR_SW_Patch2 "software version patch character 2";
CM_ SG_ 969 ZONE_FR_SW_Patch1 "software version patch character 1";
CM_ SG_ 969 ZONE_FR_SW_Minor2 "software version minor character 2";
CM_ SG_ 969 ZONE_FR_SW_Minor1 "software version minor character 1";
CM_ SG_ 969 ZONE_FR_SW_Major2 "software version major character 2";
CM_ SG_ 969 ZONE_FR_SW_Major1 "software version major character 1";
CM_ SG_ 969 ZONE_FR_SW_Controller2 "software version controller character 2";
CM_ SG_ 969 ZONE_FR_SW_Controller1 "software version controller character 1";
CM_ SG_ 969 ZONE_FR_SW_CarModel3 "software version car model character 3";
CM_ SG_ 969 ZONE_FR_SW_CarModel2 "software version car model character 2";
CM_ SG_ 969 ZONE_FR_SW_CarModel1 "software version car model character 1";
CM_ SG_ 969 ZONE_FR_HW_Ver3 "ZONE_FR hardware version character 3";
CM_ SG_ 969 ZONE_FR_HW_Ver2 "ZONE_FR hardware version character 2";
CM_ SG_ 969 ZONE_FR_HW_Ver1 "ZONE_FR hardware version character 1";
CM_ SG_ 969 ZONE_FR_SW_dash1 "software version dash character 1";
CM_ SG_ 969 ZONE_FR_SW_change1 "software version number of change 1";
CM_ SG_ 969 ZONE_FR_SW_change2 "software version number of change 2";
CM_ SG_ 969 ZONE_FR_SW_dash2 "software version dash character 2";
CM_ SG_ 969 ZONE_FR_SW_SHA1 "software version SHA character 1";
CM_ SG_ 969 ZONE_FR_SW_SHA2 "software version SHA character 2";
CM_ SG_ 969 ZONE_FR_SW_SHA3 "software version SHA character 3";
CM_ SG_ 969 ZONE_FR_SW_SHA4 "software version SHA character 4";
CM_ SG_ 969 ZONE_FR_SW_SHA5 "software version SHA character 5";
CM_ SG_ 969 ZONE_FR_SW_SHA6 "software version SHA character 6";
CM_ SG_ 969 ZONE_FR_SW_SHA7 "software version SHA character 7";
CM_ SG_ 969 ZONE_FR_SW_SHA8 "software version SHA character 8";
CM_ SG_ 969 ZONE_FR_SW_ECUGen2 "ECU generation 2";
CM_ SG_ 969 ZONE_FR_SW_ECUGen1 "ECU generation 1";
CM_ SG_ 969 ZONE_FR_SW_Var5 "software version car model variation 5";
CM_ SG_ 969 ZONE_FR_SW_Var4 "software version car model variation 4";
CM_ SG_ 969 ZONE_FR_SW_Var3 "software version car model variation 3";
CM_ SG_ 969 ZONE_FR_SW_Var2 "software version car model variation 2";
CM_ SG_ 1284 NM_ZONE_FR_Node_ID "Source Node Identifier";
CM_ SG_ 1284 NM_ZONE_FR_PNI "Partial Network Information Bit (PNI)";
CM_ SG_ 1284 NM_ZONE_FR_Active_WU "Active Wakeup Bit";
CM_ SG_ 1284 NM_ZONE_FR_CSB "NM Coordinator Sleep Bit";
CM_ SG_ 1284 NM_ZONE_FR_Rpt_Msg_Req "Repeat Message Request";
CM_ SG_ 1284 NM_ZONE_FR_ERROR_State "Defined Error states of the CAN Controller";
CM_ SG_ 1285 NM_DKC_Node_ID "Source Node Identifier";
CM_ SG_ 1285 NM_DKC_PNI "Partial Network Information Bit (PNI)";
CM_ SG_ 1285 NM_DKC_Active_WU "Active Wakeup Bit";
CM_ SG_ 1285 NM_DKC_CSB "NM Coordinator Sleep Bit";
CM_ SG_ 1285 NM_DKC_Rpt_Msg_Req "Repeat Message Request";
CM_ SG_ 1285 NM_DKC_ERROR_State "Defined Error states of the CAN Controller";
CM_ SG_ 1344 NM_ZONE_DR_Node_ID "Source Node Identifier";
CM_ SG_ 1344 NM_ZONE_DR_PNI "Partial Network Information Bit (PNI)";
CM_ SG_ 1344 NM_ZONE_DR_Active_WU "Active Wakeup Bit";
CM_ SG_ 1344 NM_ZONE_DR_CSB "NM Coordinator Sleep Bit";
CM_ SG_ 1344 NM_ZONE_DR_Rpt_Msg_Req "Repeat Message Request";
CM_ SG_ 1344 NM_ZONE_DR_ERROR_State "Defined Error states of the CAN Controller";
CM_ SG_ 1540 DiagRespFromZONE_FR "Diagnostic Response from ZONE_FR";
CM_ SG_ 1541 DiagRespFromDKC "Diagnostic Response from DKC";
CM_ SG_ 1573 DiagRespFromAirPTC "Diagnostic Response from AirPTC";
CM_ SG_ 1589 DiagRespFromWPTC "Diagnostic Response from WPTC
";
CM_ SG_ 1600 DiagRespFromZONE_DR "Diagnostic Response from ZONE_DR";
CM_ SG_ 1605 DiagRespFromCompress "Diagnostic Response from Compress";
CM_ SG_ 630 DCPortNeg_Temp "DC Port Negtive Pin Temperature";
CM_ SG_ 630 DCPortPos_Temp "DC Port Positive Pin Temperature";
CM_ SG_ 630 OBCACCSLimit "OBC AC Charger station Limit";
CM_ SG_ 630 HVInVolt "HV Input voltage";
CM_ SG_ 630 OBCDCVoltLm "OBC DC Voltage Limit";
CM_ SG_ 630 OBCDCCurLm "OBC DC Current Limit";
CM_ SG_ 630 ReChargerStaFromEvcc "ResarvationChargerStatusFromEVCC";
CM_ SG_ 630 OBCEna "OBC Enable Charging";
CM_ SG_ 630 LVBattDet12V "12V Battery Detect";
CM_ SG_ 928 FDC_VCU_ReqHWReset_Cmd "OTA request hardware reset";
CM_ SG_ 928 FD4_CE100_2_CS "Checksum of FD4_CE100_2 (AUTOSAR E2E profile 1)

Polynomial 0x1D (x^8+x^4+x^3+x^2+1) Both start value and XOR value are 0x00.";
CM_ SG_ 928 FD4_CE100_2_RC "4-bit rolling counter for FD4_CE100_2
It starts counting from 0, ends at 14 and returns to zero (0~14).";
CM_ SG_ 597 IVI_MLSEATvent_Cmd "IVI ML SEAT Vent command";
CM_ SG_ 597 IVI_MRSEATvent_Cmd "IVI MR SEAT Vent command";
CM_ SG_ 597 IVI_MLFootLift_Cmd "IVI ML Foot Lift command";
CM_ SG_ 597 IVI_MLRecliner_Cmd "IVI ML SEAT Recliner command";
CM_ SG_ 597 IVI_MLSeatLift_Cmd "IVI ML SEAT Lift command";
CM_ SG_ 597 IVI_MLSlider_Cmd "IVI ML SEAT Slider command";
CM_ SG_ 597 IVI_MRFootLift_Cmd "IVI MR Foot Lift command";
CM_ SG_ 597 IVI_MRRecliner_Cmd "IVI MR SEAT Recliner command";
CM_ SG_ 597 IVI_MRSeatLift_Cmd "IVI MR SEAT Lift command";
CM_ SG_ 597 IVI_MRSlider_Cmd "IVI MR SEAT Slider command";
CM_ SG_ 597 IVI_MLFMost_Cmd "IVI ML SEAT Forward to Most command";
CM_ SG_ 597 IVI_MLNapMode_Cmd "IVI ML SEAT Nap Mode command";
CM_ SG_ 597 IVI_MLRestore_Cmd "IVI ML SEAT Restore command";
CM_ SG_ 597 IVI_MLSldRestore_Cmd "IVI ML SEAT Slider Restore command";
CM_ SG_ 597 IVI_MLZeroGravity_Cmd "IVI ML Zero Gravity command";
CM_ SG_ 597 IVI_MRFMost_Cmd "IVI MR SEAT Forward to Most command";
CM_ SG_ 597 IVI_MRNapMode_Cmd "IVI MR SEAT Nap Mode command";
CM_ SG_ 597 IVI_MRRestore_Cmd "IVI MR SEAT Restore command";
CM_ SG_ 597 IVI_MRSldRestore_Cmd "IVI MR SEAT Slider Restore command";
CM_ SG_ 597 IVI_MRZeroGravity_Cmd "IVI MR Zero Gravity command";
CM_ SG_ 597 IVI_LSEATvent_Cmd "IVI FL SEAT Vent command";
CM_ SG_ 597 IVI_RSEATvent_Cmd "IVI FR SEAT Vent command";
CM_ SG_ 513 FDC_BCM_TurnLpLActive_Cmd "TurnLpLActive to DVR";
CM_ SG_ 513 FDC_BCM_TurnLpRActive_Cmd "TurnLpRActive to DVR";
CM_ SG_ 513 FDC_BCM_STurnLpLeft_Cmd "support turn lamp Left";
CM_ SG_ 513 FDC_BCM_STurnLpRight_Cmd "support turn lamp Right";
CM_ SG_ 513 FDC_BCM_LSMLP_Cmd "left side mark Lamp";
CM_ SG_ 513 FDC_BCM_RSMLP_Cmd "Right side mark Lamp";
CM_ SG_ 513 FDC_BCM_BBuzzer_Cmd "Turn Buzzer Command";
CM_ SG_ 513 FDC_BCM_BBuzzerout_Cmd "Turn Buzzer output Command";
CM_ SG_ 513 FDC_BCM_RevBuzzerout_Cmd "Recerse Buzzer output Command";
CM_ SG_ 513 FDC_BCM_innerBuzzer_Cmd "inner Buzzer output Command";
CM_ SG_ 513 FDC_BCM_EmExitLight_Cmd "Emergency Exit Light Cmd";
CM_ SG_ 513 FDC_BCM_FrRoomlamp_Cmd "Front Room lamp Switch";
CM_ SG_ 513 FDC_BCM_RrRoomlamp_Cmd "Rear Room lamp Switch";
CM_ SG_ 513 FDC_BCM_FrAtmoLamp_Cmd "Front Atmosphere lamp Switch";
CM_ SG_ 513 FDC_BCM_RrAtmoLamp_Cmd "Rear Atmosphere lamp Switch";
CM_ SG_ 513 FDC_BCM_FrRmLampBright_Cmd "Front Room Lamp  Bright adjustment";
CM_ SG_ 513 FDC_BCM_RrRmLampBright_Cmd "Rear Room Lamp  Bright adjustment";
CM_ SG_ 513 FDC_BCM_IBuzzerReq_Sta "Inner Buzzer Request ";
CM_ SG_ 513 FDC_BCM_TgateHDSWR_Sta "Right Tailgate Handle Switch";
CM_ SG_ 513 FDC_BCM_TgateHDSWL_Sta "Left Tailgate Handle Switch";
CM_ SG_ 513 FDC_BCM_TgateSWL_Sta "Right Tailgate Switch Status";
CM_ SG_ 513 FDC_BCM_TgateSWR_Sta "Left Tailgate Switch Status";
CM_ SG_ 513 FDC_BCM_RTgateRel_Cmd "Right Tailgate Release Cmd";
CM_ SG_ 513 FDC_BCM_LTgateRel_Cmd "Left Tailgate Release Cmd";
CM_ SG_ 2566827568 Z24_CHA_AirPressurePC3_Sta "Parking Tank Pressure";
CM_ SG_ 2566827568 Z24_CHA_AirPressureRC1_Sta "Rear Tank Pressure";
CM_ SG_ 2566827568 Z24_CHA_AirPressureFC2_Sta "Front Tank Pressure";
CM_ SG_ 514 FDC_CHA_EACEnDemand_Cmd "EAC enables control";
CM_ SG_ 1687 DiagPhysReqToZONE_FR_24 "Diagnostic Physical Request to ZONE_FR_24";
CM_ SG_ 1559 DiagRespFromZONE_FR_24 "Diagnostic Response from ZONE_FR_24";
BA_DEF_ BO_  "GenMsgSendType" ENUM  "Cycle","NoMsgSendType","IfActive","Event","CA","CE";
BA_DEF_ BO_  "GenMsgNrOfRepetition" INT 0 0;
BA_DEF_ BO_  "GenMsgILSupport" ENUM  "No","Yes";
BA_DEF_ BO_  "GenMsgCycleTimeFast" INT 0 0;
BA_DEF_ BO_  "GenMsgCycleTime" INT 0 0;
BA_DEF_ BO_  "DiagResponse" ENUM  "No","Yes";
BA_DEF_ BO_  "DiagRequest" ENUM  "No","Yes";
BA_DEF_ BO_  "NmMessage" ENUM  "No","Yes";
BA_DEF_ BO_  "VFrameFormat" ENUM  "StandardCAN","ExtendedCAN","reserved","reserved","reserved","reserved","reserved","reserved","reserved","reserved","reserved","reserved","reserved","reserved","StandardCAN_FD","ExtendedCAN_FD";
BA_DEF_ BO_  "DataID" STRING ;
BA_DEF_ BO_  "DoIPLogicalAddress" STRING ;
BA_DEF_ BO_  "CANFD_BRS" ENUM  "0","1";
BA_DEF_ BO_  "GenMsgRequestable" INT 0 1;
BA_DEF_ SG_  "GenSigInvalidValue" HEX 0 0;
BA_DEF_ SG_  "GenSigStartValue" HEX 0 0;
BA_DEF_ SG_  "GenSigInactiveValue" HEX 0 0;
BA_DEF_ SG_  "GenSigRoutingTimeoutValue_String" STRING ;
BA_DEF_ SG_  "GenSigRoutingTimeoutValue" HEX 0 0;
BA_DEF_ SG_  "GenSigSendType" ENUM  "Cycle","OnWrite","OnWriteWithRepetition","OnChange","OnChangeWithRepetition","IfActive","IfActiveWithRepetition","NoSigSendType","vector_leerstring";
BA_DEF_ SG_  "SigType" ENUM  "Default","Range","RangeSigned","ASCII","Discrete","Control","ReferencePGN","DTC","StringDelimiter","StringLength","StringLengthControl","MessageCounter","MessageChecksum";
BA_DEF_ SG_  "GenSigILSupport" ENUM  "No","Yes";
BA_DEF_ SG_  "SystemSignalLongSymbol" STRING ;
BA_DEF_DEF_  "GenMsgSendType" "Cycle";
BA_DEF_DEF_  "GenMsgNrOfRepetition" 0;
BA_DEF_DEF_  "GenMsgILSupport" "Yes";
BA_DEF_DEF_  "GenMsgCycleTimeFast" 0;
BA_DEF_DEF_  "GenMsgCycleTime" 100;
BA_DEF_DEF_  "DiagResponse" "No";
BA_DEF_DEF_  "DiagRequest" "No";
BA_DEF_DEF_  "NmMessage" "No";
BA_DEF_DEF_  "VFrameFormat" "StandardCAN";
BA_DEF_DEF_  "DataID" "";
BA_DEF_DEF_  "DoIPLogicalAddress" "";
BA_DEF_DEF_  "CANFD_BRS" "1";
BA_DEF_DEF_  "GenMsgRequestable" 1;
BA_DEF_DEF_  "GenSigInvalidValue" 0;
BA_DEF_DEF_  "GenSigStartValue" 0;
BA_DEF_DEF_  "GenSigInactiveValue" 0;
BA_DEF_DEF_  "GenSigRoutingTimeoutValue_String" "";
BA_DEF_DEF_  "GenSigRoutingTimeoutValue" 0;
BA_DEF_DEF_  "GenSigSendType" "Cycle";
BA_DEF_DEF_  "SigType" "Default";
BA_DEF_DEF_  "GenSigILSupport" "Yes";
BA_DEF_DEF_  "SystemSignalLongSymbol" "";
BA_ "GenMsgSendType" BO_ 796 5;
BA_ "GenMsgNrOfRepetition" BO_ 796 1;
BA_ "VFrameFormat" BO_ 796 14;
BA_ "GenMsgSendType" BO_ 593 5;
BA_ "GenMsgCycleTimeFast" BO_ 593 10;
BA_ "GenMsgNrOfRepetition" BO_ 593 1;
BA_ "VFrameFormat" BO_ 593 14;
BA_ "GenMsgSendType" BO_ 594 5;
BA_ "GenMsgCycleTimeFast" BO_ 594 10;
BA_ "GenMsgNrOfRepetition" BO_ 594 1;
BA_ "VFrameFormat" BO_ 594 14;
BA_ "VFrameFormat" BO_ 596 14;
BA_ "VFrameFormat" BO_ 778 14;
BA_ "GenMsgCycleTimeFast" BO_ 804 50;
BA_ "GenMsgNrOfRepetition" BO_ 804 1;
BA_ "VFrameFormat" BO_ 804 14;
BA_ "GenMsgCycleTime" BO_ 965 5000;
BA_ "VFrameFormat" BO_ 965 14;
BA_ "GenMsgCycleTime" BO_ 969 5000;
BA_ "VFrameFormat" BO_ 969 14;
BA_ "GenMsgSendType" BO_ 1284 3;
BA_ "NmMessage" BO_ 1284 1;
BA_ "GenMsgCycleTime" BO_ 1284 0;
BA_ "GenMsgSendType" BO_ 1285 3;
BA_ "GenMsgCycleTime" BO_ 1285 0;
BA_ "GenMsgSendType" BO_ 1344 3;
BA_ "NmMessage" BO_ 1344 1;
BA_ "GenMsgCycleTime" BO_ 1344 0;
BA_ "DoIPLogicalAddress" BO_ 1540 "0x0684";
BA_ "GenMsgSendType" BO_ 1540 3;
BA_ "DiagResponse" BO_ 1540 1;
BA_ "GenMsgCycleTime" BO_ 1540 0;
BA_ "VFrameFormat" BO_ 1540 14;
BA_ "DoIPLogicalAddress" BO_ 1541 "0x0685";
BA_ "GenMsgSendType" BO_ 1541 3;
BA_ "DiagResponse" BO_ 1541 1;
BA_ "GenMsgCycleTime" BO_ 1541 0;
BA_ "VFrameFormat" BO_ 1541 14;
BA_ "DoIPLogicalAddress" BO_ 1573 "0x06A5";
BA_ "GenMsgSendType" BO_ 1573 3;
BA_ "DiagResponse" BO_ 1573 1;
BA_ "GenMsgCycleTime" BO_ 1573 0;
BA_ "VFrameFormat" BO_ 1573 14;
BA_ "DoIPLogicalAddress" BO_ 1589 "0x06B5";
BA_ "GenMsgSendType" BO_ 1589 3;
BA_ "DiagResponse" BO_ 1589 1;
BA_ "GenMsgCycleTime" BO_ 1589 0;
BA_ "VFrameFormat" BO_ 1589 14;
BA_ "DoIPLogicalAddress" BO_ 1600 "0x06C0";
BA_ "GenMsgSendType" BO_ 1600 3;
BA_ "DiagResponse" BO_ 1600 1;
BA_ "GenMsgCycleTime" BO_ 1600 0;
BA_ "VFrameFormat" BO_ 1600 14;
BA_ "DoIPLogicalAddress" BO_ 1605 "0x06C5";
BA_ "GenMsgSendType" BO_ 1605 3;
BA_ "DiagResponse" BO_ 1605 1;
BA_ "GenMsgCycleTime" BO_ 1605 0;
BA_ "VFrameFormat" BO_ 1605 14;
BA_ "GenMsgSendType" BO_ 630 5;
BA_ "GenMsgCycleTimeFast" BO_ 630 10;
BA_ "GenMsgNrOfRepetition" BO_ 630 1;
BA_ "VFrameFormat" BO_ 630 14;
BA_ "GenMsgSendType" BO_ 928 5;
BA_ "DataID" BO_ 928 "0x3A01";
BA_ "GenMsgNrOfRepetition" BO_ 928 1;
BA_ "VFrameFormat" BO_ 928 14;
BA_ "GenMsgSendType" BO_ 597 5;
BA_ "GenMsgCycleTime" BO_ 597 200;
BA_ "GenMsgNrOfRepetition" BO_ 597 1;
BA_ "VFrameFormat" BO_ 597 14;
BA_ "GenMsgSendType" BO_ 513 5;
BA_ "GenMsgNrOfRepetition" BO_ 513 10;
BA_ "VFrameFormat" BO_ 513 14;
BA_ "GenMsgSendType" BO_ 515 5;
BA_ "GenMsgCycleTimeFast" BO_ 515 10;
BA_ "GenMsgNrOfRepetition" BO_ 515 1;
BA_ "VFrameFormat" BO_ 515 14;
BA_ "VFrameFormat" BO_ 2566827568 1;
BA_ "GenMsgCycleTime" BO_ 2566827568 1000;
BA_ "VFrameFormat" BO_ 514 14;
BA_ "DoIPLogicalAddress" BO_ 1687 "0x0697";
BA_ "GenMsgSendType" BO_ 1687 3;
BA_ "DiagRequest" BO_ 1687 1;
BA_ "GenMsgCycleTime" BO_ 1687 0;
BA_ "VFrameFormat" BO_ 1687 14;
BA_ "DoIPLogicalAddress" BO_ 1559 "0x0697";
BA_ "GenMsgSendType" BO_ 1559 3;
BA_ "DiagResponse" BO_ 1559 1;
BA_ "GenMsgCycleTime" BO_ 1559 0;
BA_ "VFrameFormat" BO_ 1559 14;
BA_ "GenSigSendType" SG_ 796 FRTurnLampC 3;
BA_ "GenSigRoutingTimeoutValue" SG_ 796 FRTurnLampC 255;
BA_ "GenSigInactiveValue" SG_ 796 FRTurnLampC 255;
BA_ "GenSigRoutingTimeoutValue_String" SG_ 796 FRTurnLampC "0xFF";
BA_ "GenSigStartValue" SG_ 796 FRTurnLampC 255;
BA_ "GenSigInvalidValue" SG_ 796 FRTurnLampC 255;
BA_ "GenSigSendType" SG_ 796 FLTurnLampC 3;
BA_ "GenSigRoutingTimeoutValue" SG_ 796 FLTurnLampC 255;
BA_ "GenSigInactiveValue" SG_ 796 FLTurnLampC 255;
BA_ "GenSigRoutingTimeoutValue_String" SG_ 796 FLTurnLampC "0xFF";
BA_ "GenSigStartValue" SG_ 796 FLTurnLampC 255;
BA_ "GenSigInvalidValue" SG_ 796 FLTurnLampC 255;
BA_ "GenSigSendType" SG_ 796 ChargeInletLockSta 3;
BA_ "GenSigRoutingTimeoutValue_String" SG_ 796 ChargeInletLockSta "0x0";
BA_ "GenSigSendType" SG_ 796 FWiperAS 3;
BA_ "GenSigSendType" SG_ 796 FWiperProtection 3;
BA_ "GenSigRoutingTimeoutValue" SG_ 796 CCM_SpdCmd 32767;
BA_ "GenSigRoutingTimeoutValue_String" SG_ 796 CCM_SpdCmd "0x7FFF";
BA_ "GenSigInvalidValue" SG_ 796 CCM_SpdCmd 32767;
BA_ "GenSigStartValue" SG_ 796 BMSPackVol_h6HSC6 4095;
BA_ "GenSigRoutingTimeoutValue" SG_ 796 EXV_Cmd_Set_Rq 65535;
BA_ "GenSigInactiveValue" SG_ 796 EXV_Cmd_Set_Rq 65535;
BA_ "GenSigRoutingTimeoutValue_String" SG_ 796 EXV_Cmd_Set_Rq "0xFFFF";
BA_ "GenSigStartValue" SG_ 796 EXV_Cmd_Set_Rq 65535;
BA_ "GenSigInvalidValue" SG_ 796 EXV_Cmd_Set_Rq 65535;
BA_ "GenSigRoutingTimeoutValue" SG_ 796 EXV2_Cmd_Set_Rq 65535;
BA_ "GenSigInactiveValue" SG_ 796 EXV2_Cmd_Set_Rq 65535;
BA_ "GenSigRoutingTimeoutValue_String" SG_ 796 EXV2_Cmd_Set_Rq "0xFFFF";
BA_ "GenSigStartValue" SG_ 796 EXV2_Cmd_Set_Rq 65535;
BA_ "GenSigInvalidValue" SG_ 796 EXV2_Cmd_Set_Rq 65535;
BA_ "GenSigRoutingTimeoutValue" SG_ 796 EWP3_RPM_Target_EWP_Rq 255;
BA_ "GenSigRoutingTimeoutValue_String" SG_ 796 EWP3_RPM_Target_EWP_Rq "0xFF";
BA_ "GenSigInvalidValue" SG_ 796 EWP3_RPM_Target_EWP_Rq 255;
BA_ "GenSigRoutingTimeoutValue" SG_ 796 EWP2_RPM_Target_EWP_Rq 255;
BA_ "GenSigRoutingTimeoutValue_String" SG_ 796 EWP2_RPM_Target_EWP_Rq "0xFF";
BA_ "GenSigInvalidValue" SG_ 796 EWP2_RPM_Target_EWP_Rq 255;
BA_ "GenSigRoutingTimeoutValue" SG_ 796 EWP1_RPM_Target_EWP_Rq 255;
BA_ "GenSigRoutingTimeoutValue_String" SG_ 796 EWP1_RPM_Target_EWP_Rq "0xFF";
BA_ "GenSigInvalidValue" SG_ 796 EWP1_RPM_Target_EWP_Rq 255;
BA_ "GenSigRoutingTimeoutValue" SG_ 796 EXV2_Cmd_Init_Rq 7;
BA_ "GenSigInactiveValue" SG_ 796 EXV2_Cmd_Init_Rq 7;
BA_ "GenSigRoutingTimeoutValue_String" SG_ 796 EXV2_Cmd_Init_Rq "0x7";
BA_ "GenSigStartValue" SG_ 796 EXV2_Cmd_Init_Rq 7;
BA_ "GenSigInvalidValue" SG_ 796 EXV2_Cmd_Init_Rq 7;
BA_ "GenSigRoutingTimeoutValue" SG_ 796 EXV_Cmd_Init_Rq 7;
BA_ "GenSigInactiveValue" SG_ 796 EXV_Cmd_Init_Rq 7;
BA_ "GenSigRoutingTimeoutValue_String" SG_ 796 EXV_Cmd_Init_Rq "0x7";
BA_ "GenSigStartValue" SG_ 796 EXV_Cmd_Init_Rq 7;
BA_ "GenSigInvalidValue" SG_ 796 EXV_Cmd_Init_Rq 7;
BA_ "GenSigSendType" SG_ 796 TrailerModeSta 3;
BA_ "GenSigRoutingTimeoutValue_String" SG_ 796 TrailerModeSta "0x0";
BA_ "GenSigSendType" SG_ 796 TrailerCheck 3;
BA_ "GenSigRoutingTimeoutValue_String" SG_ 796 TrailerCheck "0x0";
BA_ "GenSigSendType" SG_ 796 ZFR_BCM_ChargerDoorSW_Sta 3;
BA_ "GenSigRoutingTimeoutValue_String" SG_ 796 ZFR_BCM_ChargerDoorSW_Sta "0x0";
BA_ "GenSigSendType" SG_ 796 FLTurnLPErr 3;
BA_ "GenSigRoutingTimeoutValue" SG_ 796 FLTurnLPErr 1;
BA_ "GenSigRoutingTimeoutValue_String" SG_ 796 FLTurnLPErr "0x1";
BA_ "GenSigRoutingTimeoutValue_String" SG_ 796 FLTurn_Light_Warning "0x0";
BA_ "GenSigSendType" SG_ 796 FRPosLPErr 3;
BA_ "GenSigRoutingTimeoutValue" SG_ 796 FRPosLPErr 1;
BA_ "GenSigRoutingTimeoutValue_String" SG_ 796 FRPosLPErr "0x1";
BA_ "GenSigSendType" SG_ 796 FRTurnLPErr 3;
BA_ "GenSigRoutingTimeoutValue" SG_ 796 FRTurnLPErr 1;
BA_ "GenSigRoutingTimeoutValue_String" SG_ 796 FRTurnLPErr "0x1";
BA_ "GenSigRoutingTimeoutValue_String" SG_ 796 FRTurn_Light_Warning "0x0";
BA_ "GenSigSendType" SG_ 796 LADBErr 3;
BA_ "GenSigRoutingTimeoutValue" SG_ 796 LADBErr 1;
BA_ "GenSigRoutingTimeoutValue_String" SG_ 796 LADBErr "0x1";
BA_ "GenSigRoutingTimeoutValue_String" SG_ 796 LADB_Hibeam_Indication "0x0";
BA_ "GenSigRoutingTimeoutValue_String" SG_ 796 LADB_Operation_Status "0x0";
BA_ "GenSigRoutingTimeoutValue_String" SG_ 796 LADB_Warning "0x0";
BA_ "GenSigRoutingTimeoutValue_String" SG_ 796 LAHB_Warning "0x0";
BA_ "GenSigSendType" SG_ 796 LDRLErr 3;
BA_ "GenSigRoutingTimeoutValue" SG_ 796 LDRLErr 1;
BA_ "GenSigRoutingTimeoutValue_String" SG_ 796 LDRLErr "0x1";
BA_ "GenSigRoutingTimeoutValue_String" SG_ 796 LDRL_Warning "0x0";
BA_ "GenSigSendType" SG_ 796 LH_BeamErr 3;
BA_ "GenSigRoutingTimeoutValue" SG_ 796 LH_BeamErr 1;
BA_ "GenSigRoutingTimeoutValue_String" SG_ 796 LH_BeamErr "0x1";
BA_ "GenSigRoutingTimeoutValue_String" SG_ 796 LLB_Warning "0x0";
BA_ "GenSigSendType" SG_ 796 LL_BeamErr 3;
BA_ "GenSigRoutingTimeoutValue" SG_ 796 LL_BeamErr 1;
BA_ "GenSigRoutingTimeoutValue_String" SG_ 796 LL_BeamErr "0x1";
BA_ "GenSigRoutingTimeoutValue_String" SG_ 796 Lposition_Lamp_Warning "0x0";
BA_ "GenSigSendType" SG_ 796 RADBErr 3;
BA_ "GenSigRoutingTimeoutValue" SG_ 796 RADBErr 1;
BA_ "GenSigRoutingTimeoutValue_String" SG_ 796 RADBErr "0x1";
BA_ "GenSigRoutingTimeoutValue_String" SG_ 796 RADB_Hibeam_Indication "0x0";
BA_ "GenSigRoutingTimeoutValue_String" SG_ 796 RADB_Operation_Status "0x0";
BA_ "GenSigRoutingTimeoutValue_String" SG_ 796 RADB_Warning "0x0";
BA_ "GenSigRoutingTimeoutValue_String" SG_ 796 RAHB_Warning "0x0";
BA_ "GenSigSendType" SG_ 796 RDRLErr 3;
BA_ "GenSigRoutingTimeoutValue" SG_ 796 RDRLErr 1;
BA_ "GenSigRoutingTimeoutValue_String" SG_ 796 RDRLErr "0x1";
BA_ "GenSigRoutingTimeoutValue_String" SG_ 796 RDRL_Warning "0x0";
BA_ "GenSigSendType" SG_ 796 RH_BeamErr 3;
BA_ "GenSigRoutingTimeoutValue" SG_ 796 RH_BeamErr 1;
BA_ "GenSigRoutingTimeoutValue_String" SG_ 796 RH_BeamErr "0x1";
BA_ "GenSigRoutingTimeoutValue_String" SG_ 796 RLB_Warning "0x0";
BA_ "GenSigSendType" SG_ 796 RL_BeamErr 3;
BA_ "GenSigRoutingTimeoutValue" SG_ 796 RL_BeamErr 1;
BA_ "GenSigRoutingTimeoutValue_String" SG_ 796 RL_BeamErr "0x1";
BA_ "GenSigRoutingTimeoutValue_String" SG_ 796 Rposition_Lamp_Warning "0x0";
BA_ "GenSigSendType" SG_ 796 FLPosLPErr 3;
BA_ "GenSigRoutingTimeoutValue" SG_ 796 FLPosLPErr 1;
BA_ "GenSigRoutingTimeoutValue_String" SG_ 796 FLPosLPErr "0x1";
BA_ "GenSigRoutingTimeoutValue" SG_ 796 ZFR_THCM_CLEVentActZ_Sta 127;
BA_ "GenSigRoutingTimeoutValue_String" SG_ 796 ZFR_THCM_CLEVentActZ_Sta "0x7F";
BA_ "GenSigInvalidValue" SG_ 796 ZFR_THCM_CLEVentActZ_Sta 127;
BA_ "GenSigRoutingTimeoutValue" SG_ 796 ZFR_THCM_CREVentActY_Sta 127;
BA_ "GenSigRoutingTimeoutValue_String" SG_ 796 ZFR_THCM_CREVentActY_Sta "0x7F";
BA_ "GenSigInvalidValue" SG_ 796 ZFR_THCM_CREVentActY_Sta 127;
BA_ "GenSigRoutingTimeoutValue" SG_ 796 ZFR_THCM_CREVentActZ_Sta 127;
BA_ "GenSigRoutingTimeoutValue_String" SG_ 796 ZFR_THCM_CREVentActZ_Sta "0x7F";
BA_ "GenSigInvalidValue" SG_ 796 ZFR_THCM_CREVentActZ_Sta 127;
BA_ "GenSigRoutingTimeoutValue" SG_ 796 ZFR_THCM_DrEVentActY_Sta 127;
BA_ "GenSigRoutingTimeoutValue_String" SG_ 796 ZFR_THCM_DrEVentActY_Sta "0x7F";
BA_ "GenSigInvalidValue" SG_ 796 ZFR_THCM_DrEVentActY_Sta 127;
BA_ "GenSigRoutingTimeoutValue" SG_ 796 ZFR_THCM_DrEVentActZ_Sta 127;
BA_ "GenSigRoutingTimeoutValue_String" SG_ 796 ZFR_THCM_DrEVentActZ_Sta "0x7F";
BA_ "GenSigInvalidValue" SG_ 796 ZFR_THCM_DrEVentActZ_Sta 127;
BA_ "GenSigRoutingTimeoutValue" SG_ 796 ZFR_THCM_PsEVentActY_Sta 127;
BA_ "GenSigRoutingTimeoutValue_String" SG_ 796 ZFR_THCM_PsEVentActY_Sta "0x7F";
BA_ "GenSigInvalidValue" SG_ 796 ZFR_THCM_PsEVentActY_Sta 127;
BA_ "GenSigRoutingTimeoutValue" SG_ 796 ZFR_THCM_PsEVentActZ_Sta 127;
BA_ "GenSigRoutingTimeoutValue_String" SG_ 796 ZFR_THCM_PsEVentActZ_Sta "0x7F";
BA_ "GenSigInvalidValue" SG_ 796 ZFR_THCM_PsEVentActZ_Sta 127;
BA_ "GenSigRoutingTimeoutValue" SG_ 796 ZFR_THCM_CLEVentActY_Sta 127;
BA_ "GenSigRoutingTimeoutValue_String" SG_ 796 ZFR_THCM_CLEVentActY_Sta "0x7F";
BA_ "GenSigInvalidValue" SG_ 796 ZFR_THCM_CLEVentActY_Sta 127;
BA_ "GenSigSendType" SG_ 796 ZFR_EChrg_Active_Sta 3;
BA_ "GenSigRoutingTimeoutValue_String" SG_ 796 ZFR_EChrg_Active_Sta "0x0";
BA_ "GenSigSendType" SG_ 796 ZFR_EChrg_Sys_Sta 3;
BA_ "GenSigRoutingTimeoutValue" SG_ 796 ZFR_EChrg_Sys_Sta 3;
BA_ "GenSigRoutingTimeoutValue_String" SG_ 796 ZFR_EChrg_Sys_Sta "0x3";
BA_ "GenSigInvalidValue" SG_ 796 ZFR_EChrg_Sys_Sta 3;
BA_ "GenSigSendType" SG_ 593 P_CommandToBCM 3;
BA_ "GenSigSendType" SG_ 593 P_UID_LowPower 3;
BA_ "GenSigRoutingTimeoutValue_String" SG_ 593 P_UID_LowPower "0x0";
BA_ "GenSigInvalidValue" SG_ 593 P_CommandToPTG 5;
BA_ "GenSigRoutingTimeoutValue_String" SG_ 593 P_Dkey_Show_IVI "0x0";
BA_ "GenSigSendType" SG_ 593 P_KeyMode 3;
BA_ "GenSigRoutingTimeoutValue_String" SG_ 593 P_KeyMiss "0x0";
BA_ "GenSigSendType" SG_ 593 DKC_Re_VehData 3;
BA_ "GenSigSendType" SG_ 593 DKC_ParkingMode_Cmd 3;
BA_ "GenSigSendType" SG_ 593 DKC_PDkeyAreaRAPS_Sta 3;
BA_ "GenSigRoutingTimeoutValue_String" SG_ 593 DKC_PDkeyAreaRAPS_Sta "0x0";
BA_ "GenSigSendType" SG_ 593 DKC_KeyNum_Sta 3;
BA_ "GenSigRoutingTimeoutValue_String" SG_ 593 DKC_KeyNum_Sta "0x0";
BA_ "GenSigSendType" SG_ 593 DKC_KeyType_Sta 3;
BA_ "GenSigRoutingTimeoutValue_String" SG_ 593 DKC_KeyType_Sta "0x0";
BA_ "GenSigSendType" SG_ 594 EncryptionDATA_64_127 3;
BA_ "GenSigSendType" SG_ 594 EncryptionDATA_0_63 3;
BA_ "GenSigRoutingTimeoutValue" SG_ 596 EWP1_RPM_Target_Stat 255;
BA_ "GenSigRoutingTimeoutValue_String" SG_ 596 EWP1_RPM_Target_Stat "0xFF";
BA_ "GenSigInvalidValue" SG_ 596 EWP1_RPM_Target_Stat 255;
BA_ "GenSigRoutingTimeoutValue" SG_ 596 EWP1_RPM_ActlVal_Stat 255;
BA_ "GenSigRoutingTimeoutValue_String" SG_ 596 EWP1_RPM_ActlVal_Stat "0xFF";
BA_ "GenSigInvalidValue" SG_ 596 EWP1_RPM_ActlVal_Stat 255;
BA_ "GenSigRoutingTimeoutValue" SG_ 596 EWP1_Curr_Stat 255;
BA_ "GenSigRoutingTimeoutValue_String" SG_ 596 EWP1_Curr_Stat "0xFF";
BA_ "GenSigInvalidValue" SG_ 596 EWP1_Curr_Stat 255;
BA_ "GenSigRoutingTimeoutValue" SG_ 596 EWP1_Block_Error 3;
BA_ "GenSigRoutingTimeoutValue_String" SG_ 596 EWP1_Block_Error "0x3";
BA_ "GenSigInvalidValue" SG_ 596 EWP1_Block_Error 3;
BA_ "GenSigRoutingTimeoutValue" SG_ 596 EWP1_DryRun_Error 3;
BA_ "GenSigRoutingTimeoutValue_String" SG_ 596 EWP1_DryRun_Error "0x3";
BA_ "GenSigInvalidValue" SG_ 596 EWP1_DryRun_Error 3;
BA_ "GenSigRoutingTimeoutValue" SG_ 596 EWP1_OverCurr_Error 3;
BA_ "GenSigRoutingTimeoutValue_String" SG_ 596 EWP1_OverCurr_Error "0x3";
BA_ "GenSigInvalidValue" SG_ 596 EWP1_OverCurr_Error 3;
BA_ "GenSigRoutingTimeoutValue" SG_ 596 EWP1_Temp_Stat 255;
BA_ "GenSigRoutingTimeoutValue_String" SG_ 596 EWP1_Temp_Stat "0xFF";
BA_ "GenSigInvalidValue" SG_ 596 EWP1_Temp_Stat 255;
BA_ "GenSigRoutingTimeoutValue" SG_ 596 EWP1_Volt_Stat 255;
BA_ "GenSigRoutingTimeoutValue_String" SG_ 596 EWP1_Volt_Stat "0xFF";
BA_ "GenSigInvalidValue" SG_ 596 EWP1_Volt_Stat 255;
BA_ "GenSigRoutingTimeoutValue" SG_ 596 EWP2_Volt_Stat 255;
BA_ "GenSigRoutingTimeoutValue_String" SG_ 596 EWP2_Volt_Stat "0xFF";
BA_ "GenSigInvalidValue" SG_ 596 EWP2_Volt_Stat 255;
BA_ "GenSigRoutingTimeoutValue" SG_ 596 EWP2_Temp_Stat 255;
BA_ "GenSigRoutingTimeoutValue_String" SG_ 596 EWP2_Temp_Stat "0xFF";
BA_ "GenSigInvalidValue" SG_ 596 EWP2_Temp_Stat 255;
BA_ "GenSigRoutingTimeoutValue" SG_ 596 EWP2_RPM_Target_Stat 255;
BA_ "GenSigRoutingTimeoutValue_String" SG_ 596 EWP2_RPM_Target_Stat "0xFF";
BA_ "GenSigInvalidValue" SG_ 596 EWP2_RPM_Target_Stat 255;
BA_ "GenSigRoutingTimeoutValue" SG_ 596 EWP2_RPM_ActlVal_Stat 255;
BA_ "GenSigRoutingTimeoutValue_String" SG_ 596 EWP2_RPM_ActlVal_Stat "0xFF";
BA_ "GenSigInvalidValue" SG_ 596 EWP2_RPM_ActlVal_Stat 255;
BA_ "GenSigRoutingTimeoutValue" SG_ 596 EWP2_Curr_Stat 255;
BA_ "GenSigRoutingTimeoutValue_String" SG_ 596 EWP2_Curr_Stat "0xFF";
BA_ "GenSigInvalidValue" SG_ 596 EWP2_Curr_Stat 255;
BA_ "GenSigRoutingTimeoutValue" SG_ 596 EWP2_Block_Error 3;
BA_ "GenSigRoutingTimeoutValue_String" SG_ 596 EWP2_Block_Error "0x3";
BA_ "GenSigInvalidValue" SG_ 596 EWP2_Block_Error 3;
BA_ "GenSigRoutingTimeoutValue" SG_ 596 EWP2_DryRun_Error 3;
BA_ "GenSigRoutingTimeoutValue_String" SG_ 596 EWP2_DryRun_Error "0x3";
BA_ "GenSigInvalidValue" SG_ 596 EWP2_DryRun_Error 3;
BA_ "GenSigRoutingTimeoutValue" SG_ 596 EWP2_OverCurr_Error 3;
BA_ "GenSigRoutingTimeoutValue_String" SG_ 596 EWP2_OverCurr_Error "0x3";
BA_ "GenSigInvalidValue" SG_ 596 EWP2_OverCurr_Error 3;
BA_ "GenSigRoutingTimeoutValue" SG_ 596 EWP3_Block_Error 3;
BA_ "GenSigRoutingTimeoutValue_String" SG_ 596 EWP3_Block_Error "0x3";
BA_ "GenSigInvalidValue" SG_ 596 EWP3_Block_Error 3;
BA_ "GenSigRoutingTimeoutValue" SG_ 596 EWP3_DryRun_Error 3;
BA_ "GenSigRoutingTimeoutValue_String" SG_ 596 EWP3_DryRun_Error "0x3";
BA_ "GenSigInvalidValue" SG_ 596 EWP3_DryRun_Error 3;
BA_ "GenSigRoutingTimeoutValue" SG_ 596 EWP3_RPM_Target_Stat 255;
BA_ "GenSigRoutingTimeoutValue_String" SG_ 596 EWP3_RPM_Target_Stat "0xFF";
BA_ "GenSigInvalidValue" SG_ 596 EWP3_RPM_Target_Stat 255;
BA_ "GenSigRoutingTimeoutValue" SG_ 596 EWP3_RPM_ActlVal_Stat 255;
BA_ "GenSigRoutingTimeoutValue_String" SG_ 596 EWP3_RPM_ActlVal_Stat "0xFF";
BA_ "GenSigInvalidValue" SG_ 596 EWP3_RPM_ActlVal_Stat 255;
BA_ "GenSigRoutingTimeoutValue" SG_ 596 EWP3_Curr_Stat 255;
BA_ "GenSigRoutingTimeoutValue_String" SG_ 596 EWP3_Curr_Stat "0xFF";
BA_ "GenSigInvalidValue" SG_ 596 EWP3_Curr_Stat 255;
BA_ "GenSigRoutingTimeoutValue" SG_ 596 EWP3_OverCurr_Error 3;
BA_ "GenSigRoutingTimeoutValue_String" SG_ 596 EWP3_OverCurr_Error "0x3";
BA_ "GenSigInvalidValue" SG_ 596 EWP3_OverCurr_Error 3;
BA_ "GenSigRoutingTimeoutValue" SG_ 596 EWP3_Temp_Stat 255;
BA_ "GenSigRoutingTimeoutValue_String" SG_ 596 EWP3_Temp_Stat "0xFF";
BA_ "GenSigInvalidValue" SG_ 596 EWP3_Temp_Stat 255;
BA_ "GenSigRoutingTimeoutValue" SG_ 596 EWP3_Volt_Stat 255;
BA_ "GenSigRoutingTimeoutValue_String" SG_ 596 EWP3_Volt_Stat "0xFF";
BA_ "GenSigInvalidValue" SG_ 596 EWP3_Volt_Stat 255;
BA_ "GenSigRoutingTimeoutValue" SG_ 778 EAC_Temp 255;
BA_ "GenSigInactiveValue" SG_ 778 EAC_Temp 255;
BA_ "GenSigRoutingTimeoutValue_String" SG_ 778 EAC_Temp "0xFF";
BA_ "GenSigStartValue" SG_ 778 EAC_Temp 101;
BA_ "GenSigInvalidValue" SG_ 778 EAC_Temp 255;
BA_ "GenSigRoutingTimeoutValue" SG_ 778 COMP_StatorSpd 16383;
BA_ "GenSigInactiveValue" SG_ 778 COMP_StatorSpd 16383;
BA_ "GenSigRoutingTimeoutValue_String" SG_ 778 COMP_StatorSpd "0x3FFF";
BA_ "GenSigStartValue" SG_ 778 COMP_StatorSpd 16383;
BA_ "GenSigInvalidValue" SG_ 778 COMP_StatorSpd 16383;
BA_ "GenSigRoutingTimeoutValue_String" SG_ 778 COMP_ConCur "0x0";
BA_ "GenSigRoutingTimeoutValue_String" SG_ 778 COMP_ConVolt "0x0";
BA_ "GenSigRoutingTimeoutValue_String" SG_ 778 PTCActuPwrHSC6 "0x0";
BA_ "GenSigRoutingTimeoutValue" SG_ 778 COMP_ActualPwr 8191;
BA_ "GenSigInactiveValue" SG_ 778 COMP_ActualPwr 8191;
BA_ "GenSigRoutingTimeoutValue_String" SG_ 778 COMP_ActualPwr "0x1FFF";
BA_ "GenSigStartValue" SG_ 778 COMP_ActualPwr 8191;
BA_ "GenSigInvalidValue" SG_ 778 COMP_ActualPwr 8191;
BA_ "GenSigRoutingTimeoutValue" SG_ 778 PTC1_PowerConsumption 255;
BA_ "GenSigRoutingTimeoutValue_String" SG_ 778 PTC1_PowerConsumption "0xFF";
BA_ "GenSigInvalidValue" SG_ 778 PTC1_PowerConsumption 255;
BA_ "SystemSignalLongSymbol" SG_ 804 ACT5_Emergency_run_position_stat "ACT5_Emergency_run_position_status";
BA_ "SystemSignalLongSymbol" SG_ 804 ACT5_Emergency_run_release_statu "ACT5_Emergency_run_release_status";
BA_ "SystemSignalLongSymbol" SG_ 804 ACT5_Position_specification_stat "ACT5_Position_specification_status";
BA_ "SystemSignalLongSymbol" SG_ 804 ACT5_Applied_holding_current_sta "ACT5_Applied_holding_current_status";
BA_ "SystemSignalLongSymbol" SG_ 804 ACT5_Stall_detection_release_sta "ACT5_Stall_detection_release_status";
BA_ "SystemSignalLongSymbol" SG_ 804 ACT4_Emergency_run_position_stat "ACT4_Emergency_run_position_status";
BA_ "SystemSignalLongSymbol" SG_ 804 ACT4_Emergency_run_release_statu "ACT4_Emergency_run_release_status";
BA_ "SystemSignalLongSymbol" SG_ 804 ACT4_Position_specification_stat "ACT4_Position_specification_status";
BA_ "SystemSignalLongSymbol" SG_ 804 ACT4_Applied_holding_current_sta "ACT4_Applied_holding_current_status";
BA_ "SystemSignalLongSymbol" SG_ 804 ACT4_Stall_detection_release_sta "ACT4_Stall_detection_release_status";
BA_ "SystemSignalLongSymbol" SG_ 804 ACT3_Emergency_run_position_stat "ACT3_Emergency_run_position_status";
BA_ "SystemSignalLongSymbol" SG_ 804 ACT3_Emergency_run_release_statu "ACT3_Emergency_run_release_status";
BA_ "SystemSignalLongSymbol" SG_ 804 ACT3_Position_specification_stat "ACT3_Position_specification_status";
BA_ "SystemSignalLongSymbol" SG_ 804 ACT3_Applied_holding_current_sta "ACT3_Applied_holding_current_status";
BA_ "SystemSignalLongSymbol" SG_ 804 ACT3_Stall_detection_release_sta "ACT3_Stall_detection_release_status";
BA_ "SystemSignalLongSymbol" SG_ 804 ACT2_Emergency_run_position_stat "ACT2_Emergency_run_position_status";
BA_ "SystemSignalLongSymbol" SG_ 804 ACT2_Emergency_run_release_statu "ACT2_Emergency_run_release_status";
BA_ "SystemSignalLongSymbol" SG_ 804 ACT2_Position_specification_stat "ACT2_Position_specification_status";
BA_ "SystemSignalLongSymbol" SG_ 804 ACT2_Applied_holding_current_sta "ACT2_Applied_holding_current_status";
BA_ "SystemSignalLongSymbol" SG_ 804 ACT2_Stall_detection_release_sta "ACT2_Stall_detection_release_status";
BA_ "SystemSignalLongSymbol" SG_ 804 ACT1_Emergency_run_position_stat "ACT1_Emergency_run_position_status";
BA_ "SystemSignalLongSymbol" SG_ 804 ACT1_Emergency_run_release_statu "ACT1_Emergency_run_release_status";
BA_ "SystemSignalLongSymbol" SG_ 804 ACT1_Position_specification_stat "ACT1_Position_specification_status";
BA_ "SystemSignalLongSymbol" SG_ 804 ACT1_Applied_holding_current_sta "ACT1_Applied_holding_current_status";
BA_ "SystemSignalLongSymbol" SG_ 804 ACT1_Stall_detection_release_sta "ACT1_Stall_detection_release_status";
BA_ "GenSigSendType" SG_ 1284 NM_ZONE_FR_Node_ID 7;
BA_ "GenSigSendType" SG_ 1284 NM_ZONE_FR_PNI 7;
BA_ "GenSigSendType" SG_ 1284 NM_ZONE_FR_Active_WU 7;
BA_ "GenSigSendType" SG_ 1284 NM_ZONE_FR_CSB 7;
BA_ "GenSigSendType" SG_ 1284 NM_ZONE_FR_Rpt_Msg_Req 7;
BA_ "GenSigSendType" SG_ 1284 NM_ZONE_FR_ERROR_State 7;
BA_ "GenSigSendType" SG_ 1344 NM_ZONE_DR_Node_ID 7;
BA_ "GenSigSendType" SG_ 1344 NM_ZONE_DR_PNI 7;
BA_ "GenSigSendType" SG_ 1344 NM_ZONE_DR_Active_WU 7;
BA_ "GenSigSendType" SG_ 1344 NM_ZONE_DR_CSB 7;
BA_ "GenSigSendType" SG_ 1344 NM_ZONE_DR_Rpt_Msg_Req 7;
BA_ "GenSigSendType" SG_ 1344 NM_ZONE_DR_ERROR_State 7;
BA_ "GenSigSendType" SG_ 1540 DiagRespFromZONE_FR 3;
BA_ "GenSigSendType" SG_ 1541 DiagRespFromDKC 3;
BA_ "GenSigSendType" SG_ 1573 DiagRespFromAirPTC 3;
BA_ "GenSigSendType" SG_ 1589 DiagRespFromWPTC 3;
BA_ "GenSigSendType" SG_ 1600 DiagRespFromZONE_DR 3;
BA_ "GenSigSendType" SG_ 1605 DiagRespFromCompress 3;
BA_ "GenSigStartValue" SG_ 630 DCPortNeg_Temp 255;
BA_ "GenSigInvalidValue" SG_ 630 DCPortNeg_Temp 255;
BA_ "GenSigStartValue" SG_ 630 DCPortPos_Temp 255;
BA_ "GenSigInvalidValue" SG_ 630 DCPortPos_Temp 255;
BA_ "GenSigSendType" SG_ 630 OBCACCSLimit 3;
BA_ "GenSigRoutingTimeoutValue" SG_ 630 OBCACCSLimit 255;
BA_ "GenSigInactiveValue" SG_ 630 OBCACCSLimit 255;
BA_ "GenSigRoutingTimeoutValue_String" SG_ 630 OBCACCSLimit "0xFF";
BA_ "GenSigStartValue" SG_ 630 OBCACCSLimit 255;
BA_ "GenSigInvalidValue" SG_ 630 OBCACCSLimit 255;
BA_ "GenSigStartValue" SG_ 630 OBCDCCurLm 255;
BA_ "GenSigSendType" SG_ 630 ReChargerStaFromEvcc 3;
BA_ "GenSigSendType" SG_ 630 OBCEna 3;
BA_ "GenSigRoutingTimeoutValue_String" SG_ 630 LVBattDet12V "0x0";
BA_ "GenSigSendType" SG_ 928 FDC_VCU_ReqHWReset_Cmd 3;
BA_ "GenSigSendType" SG_ 928 FD4_CE100_2_CS 3;
BA_ "GenSigSendType" SG_ 928 FD4_CE100_2_RC 3;
BA_ "GenSigSendType" SG_ 597 IVI_MLSEATvent_Cmd 3;
BA_ "GenSigRoutingTimeoutValue_String" SG_ 597 IVI_MLSEATvent_Cmd "0x0";
BA_ "GenSigSendType" SG_ 597 IVI_MRSEATvent_Cmd 3;
BA_ "GenSigRoutingTimeoutValue_String" SG_ 597 IVI_MRSEATvent_Cmd "0x0";
BA_ "GenSigSendType" SG_ 597 IVI_MLFootLift_Cmd 3;
BA_ "GenSigRoutingTimeoutValue_String" SG_ 597 IVI_MLFootLift_Cmd "0x0";
BA_ "GenSigSendType" SG_ 597 IVI_MLRecliner_Cmd 3;
BA_ "GenSigRoutingTimeoutValue_String" SG_ 597 IVI_MLRecliner_Cmd "0x0";
BA_ "GenSigSendType" SG_ 597 IVI_MLSeatLift_Cmd 3;
BA_ "GenSigRoutingTimeoutValue_String" SG_ 597 IVI_MLSeatLift_Cmd "0x0";
BA_ "GenSigSendType" SG_ 597 IVI_MLSlider_Cmd 3;
BA_ "GenSigRoutingTimeoutValue_String" SG_ 597 IVI_MLSlider_Cmd "0x0";
BA_ "GenSigSendType" SG_ 597 IVI_MRFootLift_Cmd 3;
BA_ "GenSigRoutingTimeoutValue_String" SG_ 597 IVI_MRFootLift_Cmd "0x0";
BA_ "GenSigSendType" SG_ 597 IVI_MRRecliner_Cmd 3;
BA_ "GenSigRoutingTimeoutValue_String" SG_ 597 IVI_MRRecliner_Cmd "0x0";
BA_ "GenSigSendType" SG_ 597 IVI_MRSeatLift_Cmd 3;
BA_ "GenSigRoutingTimeoutValue_String" SG_ 597 IVI_MRSeatLift_Cmd "0x0";
BA_ "GenSigSendType" SG_ 597 IVI_MRSlider_Cmd 3;
BA_ "GenSigRoutingTimeoutValue_String" SG_ 597 IVI_MRSlider_Cmd "0x0";
BA_ "GenSigSendType" SG_ 597 IVI_MLFMost_Cmd 3;
BA_ "GenSigRoutingTimeoutValue_String" SG_ 597 IVI_MLFMost_Cmd "0x0";
BA_ "GenSigSendType" SG_ 597 IVI_MLNapMode_Cmd 3;
BA_ "GenSigRoutingTimeoutValue_String" SG_ 597 IVI_MLNapMode_Cmd "0x0";
BA_ "GenSigSendType" SG_ 597 IVI_MLRestore_Cmd 3;
BA_ "GenSigRoutingTimeoutValue_String" SG_ 597 IVI_MLRestore_Cmd "0x0";
BA_ "GenSigSendType" SG_ 597 IVI_MLSldRestore_Cmd 3;
BA_ "GenSigRoutingTimeoutValue_String" SG_ 597 IVI_MLSldRestore_Cmd "0x0";
BA_ "GenSigSendType" SG_ 597 IVI_MLZeroGravity_Cmd 3;
BA_ "GenSigRoutingTimeoutValue_String" SG_ 597 IVI_MLZeroGravity_Cmd "0x0";
BA_ "GenSigSendType" SG_ 597 IVI_MRFMost_Cmd 3;
BA_ "GenSigRoutingTimeoutValue_String" SG_ 597 IVI_MRFMost_Cmd "0x0";
BA_ "GenSigSendType" SG_ 597 IVI_MRNapMode_Cmd 3;
BA_ "GenSigRoutingTimeoutValue_String" SG_ 597 IVI_MRNapMode_Cmd "0x0";
BA_ "GenSigSendType" SG_ 597 IVI_MRRestore_Cmd 3;
BA_ "GenSigRoutingTimeoutValue_String" SG_ 597 IVI_MRRestore_Cmd "0x0";
BA_ "GenSigSendType" SG_ 597 IVI_MRSldRestore_Cmd 3;
BA_ "GenSigRoutingTimeoutValue_String" SG_ 597 IVI_MRSldRestore_Cmd "0x0";
BA_ "GenSigSendType" SG_ 597 IVI_MRZeroGravity_Cmd 3;
BA_ "GenSigRoutingTimeoutValue_String" SG_ 597 IVI_MRZeroGravity_Cmd "0x0";
BA_ "GenSigSendType" SG_ 597 IVI_LSEATvent_Cmd 3;
BA_ "GenSigRoutingTimeoutValue_String" SG_ 597 IVI_LSEATvent_Cmd "0x0";
BA_ "GenSigSendType" SG_ 597 IVI_RSEATvent_Cmd 3;
BA_ "GenSigRoutingTimeoutValue_String" SG_ 597 IVI_RSEATvent_Cmd "0x0";
BA_ "GenSigSendType" SG_ 513 FDC_BCM_TurnLpLActive_Cmd 3;
BA_ "GenSigSendType" SG_ 513 FDC_BCM_TurnLpRActive_Cmd 3;
BA_ "GenSigSendType" SG_ 513 FDC_BCM_STurnLpLeft_Cmd 3;
BA_ "GenSigSendType" SG_ 513 FDC_BCM_STurnLpRight_Cmd 3;
BA_ "GenSigSendType" SG_ 513 FDC_BCM_LSMLP_Cmd 3;
BA_ "GenSigSendType" SG_ 513 FDC_BCM_RSMLP_Cmd 3;
BA_ "GenSigSendType" SG_ 513 FDC_BCM_BBuzzer_Cmd 3;
BA_ "GenSigSendType" SG_ 513 FDC_BCM_BBuzzerout_Cmd 3;
BA_ "GenSigSendType" SG_ 513 FDC_BCM_RevBuzzerout_Cmd 3;
BA_ "GenSigSendType" SG_ 513 FDC_BCM_innerBuzzer_Cmd 3;
BA_ "GenSigSendType" SG_ 513 FDC_BCM_EmExitLight_Cmd 3;
BA_ "GenSigSendType" SG_ 513 FDC_BCM_FrRoomlamp_Cmd 3;
BA_ "GenSigSendType" SG_ 513 FDC_BCM_RrRoomlamp_Cmd 3;
BA_ "GenSigSendType" SG_ 513 FDC_BCM_FrAtmoLamp_Cmd 3;
BA_ "GenSigSendType" SG_ 513 FDC_BCM_RrAtmoLamp_Cmd 3;
BA_ "GenSigSendType" SG_ 513 FDC_BCM_FrRmLampBright_Cmd 3;
BA_ "GenSigSendType" SG_ 513 FDC_BCM_RrRmLampBright_Cmd 3;
BA_ "GenSigSendType" SG_ 513 FDC_BCM_IBuzzerReq_Sta 3;
BA_ "GenSigSendType" SG_ 513 FDC_BCM_TgateHDSWR_Sta 3;
BA_ "GenSigSendType" SG_ 513 FDC_BCM_TgateHDSWL_Sta 3;
BA_ "GenSigSendType" SG_ 513 FDC_BCM_TgateSWL_Sta 3;
BA_ "GenSigSendType" SG_ 513 FDC_BCM_TgateSWR_Sta 3;
BA_ "GenSigSendType" SG_ 513 FDC_BCM_RTgateRel_Cmd 3;
BA_ "GenSigSendType" SG_ 513 FDC_BCM_LTgateRel_Cmd 3;
BA_ "GenSigSendType" SG_ 515 Z24_BCM_FLTurnLampC_Sta 3;
BA_ "GenSigSendType" SG_ 515 Z24_BCM_FRTurnLampC_Sta 3;
BA_ "GenSigSendType" SG_ 515 Z24_BCM_RLTurnLampC_Sta 3;
BA_ "GenSigSendType" SG_ 515 Z24_BCM_RRTurnLampC_Sta 3;
BA_ "GenSigSendType" SG_ 515 Z24_BCM_FWiperProtection_Sta 3;
BA_ "GenSigSendType" SG_ 515 Z24_BCM_FWiperAS_Sta 3;
BA_ "GenSigSendType" SG_ 515 Z24_BCM_EmExitOP_Sta 3;
BA_ "GenSigSendType" SG_ 515 Z24_BCM_innerBuzzer_Sta 3;
BA_ "GenSigSendType" SG_ 515 Z24_BCM_SeatBeltSW_Sta 3;
BA_ "GenSigRoutingTimeoutValue" SG_ 2566827568 Z24_CHA_AirPressurePC3_Sta 176;
BA_ "GenSigRoutingTimeoutValue_String" SG_ 2566827568 Z24_CHA_AirPressurePC3_Sta "0xB0";
BA_ "GenSigInvalidValue" SG_ 2566827568 Z24_CHA_AirPressurePC3_Sta 176;
BA_ "GenSigRoutingTimeoutValue" SG_ 2566827568 Z24_CHA_AirPressureRC1_Sta 176;
BA_ "GenSigRoutingTimeoutValue_String" SG_ 2566827568 Z24_CHA_AirPressureRC1_Sta "0xB0";
BA_ "GenSigInvalidValue" SG_ 2566827568 Z24_CHA_AirPressureRC1_Sta 176;
BA_ "GenSigRoutingTimeoutValue" SG_ 2566827568 Z24_CHA_AirPressureFC2_Sta 176;
BA_ "GenSigRoutingTimeoutValue_String" SG_ 2566827568 Z24_CHA_AirPressureFC2_Sta "0xB0";
BA_ "GenSigInvalidValue" SG_ 2566827568 Z24_CHA_AirPressureFC2_Sta 176;
BA_ "GenSigSendType" SG_ 1687 DiagPhysReqToZONE_FR_24 3;
BA_ "GenSigSendType" SG_ 1559 DiagRespFromZONE_FR_24 3;
VAL_ 796 BMSReqTapPosHSC6 7 "7 Tap" 6 "6 Tap" 5 "5 Tap" 4 "4 Tap" 3 "3 Tap" 2 "2 Tap" 1 "1 Tap" 0 "0 Tap" ;
VAL_ 796 BMSReqMdHSC6 3 "PWM Control" 2 "Tap Position Control" 1 "Power Control" 0 "No Request" ;
VAL_ 796 BMSEnbPTCHSC6 1 "On" 0 "Off" ;
VAL_ 796 FRTurnLampC 255 "Invalid" ;
VAL_ 796 FLTurnLampC 255 "Invalid" ;
VAL_ 796 ChargeInletLockSta 1 "Lock" 0 "Unlock" ;
VAL_ 796 FWiperAS 1 "Not at Stop Position" 0 "Stop Position" ;
VAL_ 796 FWiperProtection 1 "In protection" 0 "Not in Protectio" ;
VAL_ 796 BDC_1_MoveEnable 1 "ReqMotorMove" 0 "NoReq" ;
VAL_ 796 CCV4_MoveEnable 1 "ReqMotorMove" 0 "NoReq" ;
VAL_ 796 CCV4_ReqMovePos 1 "Open Port 1 to Port 4, Port 2 to port 3" 0 "Open Port 1 to Port 2, Port 3 to port 4" ;
VAL_ 796 CompProEN 1 "Enable" 0 "Disable" ;
VAL_ 796 EXV_Cmd_Set_Rq 65535 "Invalid" ;
VAL_ 796 EXV2_Cmd_Set_Rq 65535 "Invalid" ;
VAL_ 796 EWP3_RPM_Target_EWP_Rq 255 "Invalid" 254 "max speed rpm" 253 "max speed rpm" 252 "max speed rpm" 251 "max speed rpm" 250 "linearly changed from min speed to max speed" 249 "linearly changed from min speed to max speed" 248 "linearly changed from min speed to max speed" 247 "linearly changed from min speed to max speed" 246 "linearly changed from min speed to max speed" 245 "linearly changed from min speed to max speed" 244 "linearly changed from min speed to max speed" 243 "linearly changed from min speed to max speed" 242 "linearly changed from min speed to max speed" 241 "linearly changed from min speed to max speed" 240 "linearly changed from min speed to max speed" 239 "linearly changed from min speed to max speed" 238 "linearly changed from min speed to max speed" 237 "linearly changed from min speed to max speed" 236 "linearly changed from min speed to max speed" 235 "linearly changed from min speed to max speed" 234 "linearly changed from min speed to max speed" 233 "linearly changed from min speed to max speed" 232 "linearly changed from min speed to max speed" 231 "linearly changed from min speed to max speed" 230 "linearly changed from min speed to max speed" 229 "linearly changed from min speed to max speed" 228 "linearly changed from min speed to max speed" 227 "linearly changed from min speed to max speed" 226 "linearly changed from min speed to max speed" 225 "linearly changed from min speed to max speed" 224 "linearly changed from min speed to max speed" 223 "linearly changed from min speed to max speed" 222 "linearly changed from min speed to max speed" 221 "linearly changed from min speed to max speed" 220 "linearly changed from min speed to max speed" 219 "linearly changed from min speed to max speed" 218 "linearly changed from min speed to max speed" 217 "linearly changed from min speed to max speed" 216 "linearly changed from min speed to max speed" 215 "linearly changed from min speed to max speed" 214 "linearly changed from min speed to max speed" 213 "linearly changed from min speed to max speed" 212 "linearly changed from min speed to max speed" 211 "linearly changed from min speed to max speed" 210 "linearly changed from min speed to max speed" 209 "linearly changed from min speed to max speed" 208 "linearly changed from min speed to max speed" 207 "linearly changed from min speed to max speed" 206 "linearly changed from min speed to max speed" 205 "linearly changed from min speed to max speed" 204 "linearly changed from min speed to max speed" 203 "linearly changed from min speed to max speed" 202 "linearly changed from min speed to max speed" 201 "linearly changed from min speed to max speed" 200 "linearly changed from min speed to max speed" 199 "linearly changed from min speed to max speed" 198 "linearly changed from min speed to max speed" 197 "linearly changed from min speed to max speed" 196 "linearly changed from min speed to max speed" 195 "linearly changed from min speed to max speed" 194 "linearly changed from min speed to max speed" 193 "linearly changed from min speed to max speed" 192 "linearly changed from min speed to max speed" 191 "linearly changed from min speed to max speed" 190 "linearly changed from min speed to max speed" 189 "linearly changed from min speed to max speed" 188 "linearly changed from min speed to max speed" 187 "linearly changed from min speed to max speed" 186 "linearly changed from min speed to max speed" 185 "linearly changed from min speed to max speed" 184 "linearly changed from min speed to max speed" 183 "linearly changed from min speed to max speed" 182 "linearly changed from min speed to max speed" 181 "linearly changed from min speed to max speed" 180 "linearly changed from min speed to max speed" 179 "linearly changed from min speed to max speed" 178 "linearly changed from min speed to max speed" 177 "linearly changed from min speed to max speed" 176 "linearly changed from min speed to max speed" 175 "linearly changed from min speed to max speed" 174 "linearly changed from min speed to max speed" 173 "linearly changed from min speed to max speed" 172 "linearly changed from min speed to max speed" 171 "linearly changed from min speed to max speed" 170 "linearly changed from min speed to max speed" 169 "linearly changed from min speed to max speed" 168 "linearly changed from min speed to max speed" 167 "linearly changed from min speed to max speed" 166 "linearly changed from min speed to max speed" 165 "linearly changed from min speed to max speed" 164 "linearly changed from min speed to max speed" 163 "linearly changed from min speed to max speed" 162 "linearly changed from min speed to max speed" 161 "linearly changed from min speed to max speed" 160 "linearly changed from min speed to max speed" 159 "linearly changed from min speed to max speed" 158 "linearly changed from min speed to max speed" 157 "linearly changed from min speed to max speed" 156 "linearly changed from min speed to max speed" 155 "linearly changed from min speed to max speed" 154 "linearly changed from min speed to max speed" 153 "linearly changed from min speed to max speed" 152 "linearly changed from min speed to max speed" 151 "linearly changed from min speed to max speed" 150 "linearly changed from min speed to max speed" 149 "linearly changed from min speed to max speed" 148 "linearly changed from min speed to max speed" 147 "linearly changed from min speed to max speed" 146 "linearly changed from min speed to max speed" 145 "linearly changed from min speed to max speed" 144 "linearly changed from min speed to max speed" 143 "linearly changed from min speed to max speed" 142 "linearly changed from min speed to max speed" 141 "linearly changed from min speed to max speed" 140 "linearly changed from min speed to max speed" 139 "linearly changed from min speed to max speed" 138 "linearly changed from min speed to max speed" 137 "linearly changed from min speed to max speed" 136 "linearly changed from min speed to max speed" 135 "linearly changed from min speed to max speed" 134 "linearly changed from min speed to max speed" 133 "linearly changed from min speed to max speed" 132 "linearly changed from min speed to max speed" 131 "linearly changed from min speed to max speed" 130 "linearly changed from min speed to max speed" 129 "linearly changed from min speed to max speed" 128 "linearly changed from min speed to max speed" 127 "linearly changed from min speed to max speed" 126 "linearly changed from min speed to max speed" 125 "linearly changed from min speed to max speed" 124 "linearly changed from min speed to max speed" 123 "linearly changed from min speed to max speed" 122 "linearly changed from min speed to max speed" 121 "linearly changed from min speed to max speed" 120 "linearly changed from min speed to max speed" 119 "linearly changed from min speed to max speed" 118 "linearly changed from min speed to max speed" 117 "linearly changed from min speed to max speed" 116 "linearly changed from min speed to max speed" 115 "linearly changed from min speed to max speed" 114 "linearly changed from min speed to max speed" 113 "linearly changed from min speed to max speed" 112 "linearly changed from min speed to max speed" 111 "linearly changed from min speed to max speed" 110 "linearly changed from min speed to max speed" 109 "linearly changed from min speed to max speed" 108 "linearly changed from min speed to max speed" 107 "linearly changed from min speed to max speed" 106 "linearly changed from min speed to max speed" 105 "linearly changed from min speed to max speed" 104 "linearly changed from min speed to max speed" 103 "linearly changed from min speed to max speed" 102 "linearly changed from min speed to max speed" 101 "linearly changed from min speed to max speed" 100 "linearly changed from min speed to max speed" 99 "linearly changed from min speed to max speed" 98 "linearly changed from min speed to max speed" 97 "linearly changed from min speed to max speed" 96 "linearly changed from min speed to max speed" 95 "linearly changed from min speed to max speed" 94 "linearly changed from min speed to max speed" 93 "linearly changed from min speed to max speed" 92 "linearly changed from min speed to max speed" 91 "linearly changed from min speed to max speed" 90 "linearly changed from min speed to max speed" 89 "linearly changed from min speed to max speed" 88 "linearly changed from min speed to max speed" 87 "linearly changed from min speed to max speed" 86 "linearly changed from min speed to max speed" 85 "linearly changed from min speed to max speed" 84 "linearly changed from min speed to max speed" 83 "linearly changed from min speed to max speed" 82 "linearly changed from min speed to max speed" 81 "linearly changed from min speed to max speed" 80 "linearly changed from min speed to max speed" 79 "linearly changed from min speed to max speed" 78 "linearly changed from min speed to max speed" 77 "linearly changed from min speed to max speed" 76 "linearly changed from min speed to max speed" 75 "linearly changed from min speed to max speed" 74 "linearly changed from min speed to max speed" 73 "linearly changed from min speed to max speed" 72 "linearly changed from min speed to max speed" 71 "linearly changed from min speed to max speed" 70 "linearly changed from min speed to max speed" 69 "linearly changed from min speed to max speed" 68 "linearly changed from min speed to max speed" 67 "linearly changed from min speed to max speed" 66 "linearly changed from min speed to max speed" 65 "linearly changed from min speed to max speed" 64 "linearly changed from min speed to max speed" 63 "linearly changed from min speed to max speed" 62 "linearly changed from min speed to max speed" 61 "linearly changed from min speed to max speed" 60 "linearly changed from min speed to max speed" 59 "linearly changed from min speed to max speed" 58 "linearly changed from min speed to max speed" 57 "linearly changed from min speed to max speed" 56 "linearly changed from min speed to max speed" 55 "linearly changed from min speed to max speed" 54 "linearly changed from min speed to max speed" 53 "linearly changed from min speed to max speed" 52 "linearly changed from min speed to max speed" 51 "linearly changed from min speed to max speed" 50 "linearly changed from min speed to max speed" 49 "min speed rpm" 48 "min speed rpm" 47 "min speed rpm" 46 "min speed rpm" 45 "min speed rpm" 44 "min speed rpm" 43 "min speed rpm" 42 "min speed rpm" 41 "min speed rpm" 40 "min speed rpm" 39 "min speed rpm" 38 "min speed rpm" 37 "min speed rpm" 36 "min speed rpm" 35 "min speed rpm" 34 "min speed rpm" 33 "min speed rpm" 32 "min speed rpm" 31 "min speed rpm" 30 "min speed rpm" 29 "min speed rpm" 28 "min speed rpm" 27 "min speed rpm" 26 "min speed rpm" 25 "min speed rpm" 24 "min speed rpm" 23 "min speed rpm" 22 "min speed rpm" 21 "min speed rpm" 20 "min speed rpm" 19 "min speed rpm" 18 "min speed rpm" 17 "min speed rpm" 16 "min speed rpm" 15 "min speed rpm" 14 "min speed rpm" 13 "min speed rpm" 12 "min speed rpm" 11 "min speed rpm" 10 "min speed rpm" 9 "min speed rpm" 8 "min speed rpm" 7 "min speed rpm" 6 "min speed rpm" 5 "min speed rpm" 4 "min speed rpm" 3 "0 rpm" 2 "0 rpm" 1 "0 rpm" 0 "0 rpm" ;
VAL_ 796 EWP2_RPM_Target_EWP_Rq 255 "Invalid" 254 "max speed rpm" 253 "max speed rpm" 252 "max speed rpm" 251 "max speed rpm" 250 "linearly changed from min speed to max speed" 249 "linearly changed from min speed to max speed" 248 "linearly changed from min speed to max speed" 247 "linearly changed from min speed to max speed" 246 "linearly changed from min speed to max speed" 245 "linearly changed from min speed to max speed" 244 "linearly changed from min speed to max speed" 243 "linearly changed from min speed to max speed" 242 "linearly changed from min speed to max speed" 241 "linearly changed from min speed to max speed" 240 "linearly changed from min speed to max speed" 239 "linearly changed from min speed to max speed" 238 "linearly changed from min speed to max speed" 237 "linearly changed from min speed to max speed" 236 "linearly changed from min speed to max speed" 235 "linearly changed from min speed to max speed" 234 "linearly changed from min speed to max speed" 233 "linearly changed from min speed to max speed" 232 "linearly changed from min speed to max speed" 231 "linearly changed from min speed to max speed" 230 "linearly changed from min speed to max speed" 229 "linearly changed from min speed to max speed" 228 "linearly changed from min speed to max speed" 227 "linearly changed from min speed to max speed" 226 "linearly changed from min speed to max speed" 225 "linearly changed from min speed to max speed" 224 "linearly changed from min speed to max speed" 223 "linearly changed from min speed to max speed" 222 "linearly changed from min speed to max speed" 221 "linearly changed from min speed to max speed" 220 "linearly changed from min speed to max speed" 219 "linearly changed from min speed to max speed" 218 "linearly changed from min speed to max speed" 217 "linearly changed from min speed to max speed" 216 "linearly changed from min speed to max speed" 215 "linearly changed from min speed to max speed" 214 "linearly changed from min speed to max speed" 213 "linearly changed from min speed to max speed" 212 "linearly changed from min speed to max speed" 211 "linearly changed from min speed to max speed" 210 "linearly changed from min speed to max speed" 209 "linearly changed from min speed to max speed" 208 "linearly changed from min speed to max speed" 207 "linearly changed from min speed to max speed" 206 "linearly changed from min speed to max speed" 205 "linearly changed from min speed to max speed" 204 "linearly changed from min speed to max speed" 203 "linearly changed from min speed to max speed" 202 "linearly changed from min speed to max speed" 201 "linearly changed from min speed to max speed" 200 "linearly changed from min speed to max speed" 199 "linearly changed from min speed to max speed" 198 "linearly changed from min speed to max speed" 197 "linearly changed from min speed to max speed" 196 "linearly changed from min speed to max speed" 195 "linearly changed from min speed to max speed" 194 "linearly changed from min speed to max speed" 193 "linearly changed from min speed to max speed" 192 "linearly changed from min speed to max speed" 191 "linearly changed from min speed to max speed" 190 "linearly changed from min speed to max speed" 189 "linearly changed from min speed to max speed" 188 "linearly changed from min speed to max speed" 187 "linearly changed from min speed to max speed" 186 "linearly changed from min speed to max speed" 185 "linearly changed from min speed to max speed" 184 "linearly changed from min speed to max speed" 183 "linearly changed from min speed to max speed" 182 "linearly changed from min speed to max speed" 181 "linearly changed from min speed to max speed" 180 "linearly changed from min speed to max speed" 179 "linearly changed from min speed to max speed" 178 "linearly changed from min speed to max speed" 177 "linearly changed from min speed to max speed" 176 "linearly changed from min speed to max speed" 175 "linearly changed from min speed to max speed" 174 "linearly changed from min speed to max speed" 173 "linearly changed from min speed to max speed" 172 "linearly changed from min speed to max speed" 171 "linearly changed from min speed to max speed" 170 "linearly changed from min speed to max speed" 169 "linearly changed from min speed to max speed" 168 "linearly changed from min speed to max speed" 167 "linearly changed from min speed to max speed" 166 "linearly changed from min speed to max speed" 165 "linearly changed from min speed to max speed" 164 "linearly changed from min speed to max speed" 163 "linearly changed from min speed to max speed" 162 "linearly changed from min speed to max speed" 161 "linearly changed from min speed to max speed" 160 "linearly changed from min speed to max speed" 159 "linearly changed from min speed to max speed" 158 "linearly changed from min speed to max speed" 157 "linearly changed from min speed to max speed" 156 "linearly changed from min speed to max speed" 155 "linearly changed from min speed to max speed" 154 "linearly changed from min speed to max speed" 153 "linearly changed from min speed to max speed" 152 "linearly changed from min speed to max speed" 151 "linearly changed from min speed to max speed" 150 "linearly changed from min speed to max speed" 149 "linearly changed from min speed to max speed" 148 "linearly changed from min speed to max speed" 147 "linearly changed from min speed to max speed" 146 "linearly changed from min speed to max speed" 145 "linearly changed from min speed to max speed" 144 "linearly changed from min speed to max speed" 143 "linearly changed from min speed to max speed" 142 "linearly changed from min speed to max speed" 141 "linearly changed from min speed to max speed" 140 "linearly changed from min speed to max speed" 139 "linearly changed from min speed to max speed" 138 "linearly changed from min speed to max speed" 137 "linearly changed from min speed to max speed" 136 "linearly changed from min speed to max speed" 135 "linearly changed from min speed to max speed" 134 "linearly changed from min speed to max speed" 133 "linearly changed from min speed to max speed" 132 "linearly changed from min speed to max speed" 131 "linearly changed from min speed to max speed" 130 "linearly changed from min speed to max speed" 129 "linearly changed from min speed to max speed" 128 "linearly changed from min speed to max speed" 127 "linearly changed from min speed to max speed" 126 "linearly changed from min speed to max speed" 125 "linearly changed from min speed to max speed" 124 "linearly changed from min speed to max speed" 123 "linearly changed from min speed to max speed" 122 "linearly changed from min speed to max speed" 121 "linearly changed from min speed to max speed" 120 "linearly changed from min speed to max speed" 119 "linearly changed from min speed to max speed" 118 "linearly changed from min speed to max speed" 117 "linearly changed from min speed to max speed" 116 "linearly changed from min speed to max speed" 115 "linearly changed from min speed to max speed" 114 "linearly changed from min speed to max speed" 113 "linearly changed from min speed to max speed" 112 "linearly changed from min speed to max speed" 111 "linearly changed from min speed to max speed" 110 "linearly changed from min speed to max speed" 109 "linearly changed from min speed to max speed" 108 "linearly changed from min speed to max speed" 107 "linearly changed from min speed to max speed" 106 "linearly changed from min speed to max speed" 105 "linearly changed from min speed to max speed" 104 "linearly changed from min speed to max speed" 103 "linearly changed from min speed to max speed" 102 "linearly changed from min speed to max speed" 101 "linearly changed from min speed to max speed" 100 "linearly changed from min speed to max speed" 99 "linearly changed from min speed to max speed" 98 "linearly changed from min speed to max speed" 97 "linearly changed from min speed to max speed" 96 "linearly changed from min speed to max speed" 95 "linearly changed from min speed to max speed" 94 "linearly changed from min speed to max speed" 93 "linearly changed from min speed to max speed" 92 "linearly changed from min speed to max speed" 91 "linearly changed from min speed to max speed" 90 "linearly changed from min speed to max speed" 89 "linearly changed from min speed to max speed" 88 "linearly changed from min speed to max speed" 87 "linearly changed from min speed to max speed" 86 "linearly changed from min speed to max speed" 85 "linearly changed from min speed to max speed" 84 "linearly changed from min speed to max speed" 83 "linearly changed from min speed to max speed" 82 "linearly changed from min speed to max speed" 81 "linearly changed from min speed to max speed" 80 "linearly changed from min speed to max speed" 79 "linearly changed from min speed to max speed" 78 "linearly changed from min speed to max speed" 77 "linearly changed from min speed to max speed" 76 "linearly changed from min speed to max speed" 75 "linearly changed from min speed to max speed" 74 "linearly changed from min speed to max speed" 73 "linearly changed from min speed to max speed" 72 "linearly changed from min speed to max speed" 71 "linearly changed from min speed to max speed" 70 "linearly changed from min speed to max speed" 69 "linearly changed from min speed to max speed" 68 "linearly changed from min speed to max speed" 67 "linearly changed from min speed to max speed" 66 "linearly changed from min speed to max speed" 65 "linearly changed from min speed to max speed" 64 "linearly changed from min speed to max speed" 63 "linearly changed from min speed to max speed" 62 "linearly changed from min speed to max speed" 61 "linearly changed from min speed to max speed" 60 "linearly changed from min speed to max speed" 59 "linearly changed from min speed to max speed" 58 "linearly changed from min speed to max speed" 57 "linearly changed from min speed to max speed" 56 "linearly changed from min speed to max speed" 55 "linearly changed from min speed to max speed" 54 "linearly changed from min speed to max speed" 53 "linearly changed from min speed to max speed" 52 "linearly changed from min speed to max speed" 51 "linearly changed from min speed to max speed" 50 "linearly changed from min speed to max speed" 49 "min speed rpm" 48 "min speed rpm" 47 "min speed rpm" 46 "min speed rpm" 45 "min speed rpm" 44 "min speed rpm" 43 "min speed rpm" 42 "min speed rpm" 41 "min speed rpm" 40 "min speed rpm" 39 "min speed rpm" 38 "min speed rpm" 37 "min speed rpm" 36 "min speed rpm" 35 "min speed rpm" 34 "min speed rpm" 33 "min speed rpm" 32 "min speed rpm" 31 "min speed rpm" 30 "min speed rpm" 29 "min speed rpm" 28 "min speed rpm" 27 "min speed rpm" 26 "min speed rpm" 25 "min speed rpm" 24 "min speed rpm" 23 "min speed rpm" 22 "min speed rpm" 21 "min speed rpm" 20 "min speed rpm" 19 "min speed rpm" 18 "min speed rpm" 17 "min speed rpm" 16 "min speed rpm" 15 "min speed rpm" 14 "min speed rpm" 13 "min speed rpm" 12 "min speed rpm" 11 "min speed rpm" 10 "min speed rpm" 9 "min speed rpm" 8 "min speed rpm" 7 "min speed rpm" 6 "min speed rpm" 5 "min speed rpm" 4 "min speed rpm" 3 "0 rpm" 2 "0 rpm" 1 "0 rpm" 0 "0 rpm" ;
VAL_ 796 EWP1_RPM_Target_EWP_Rq 255 "Invalid" 254 "max speed rpm" 253 "max speed rpm" 252 "max speed rpm" 251 "max speed rpm" 250 "linearly changed from min speed to max speed" 249 "linearly changed from min speed to max speed" 248 "linearly changed from min speed to max speed" 247 "linearly changed from min speed to max speed" 246 "linearly changed from min speed to max speed" 245 "linearly changed from min speed to max speed" 244 "linearly changed from min speed to max speed" 243 "linearly changed from min speed to max speed" 242 "linearly changed from min speed to max speed" 241 "linearly changed from min speed to max speed" 240 "linearly changed from min speed to max speed" 239 "linearly changed from min speed to max speed" 238 "linearly changed from min speed to max speed" 237 "linearly changed from min speed to max speed" 236 "linearly changed from min speed to max speed" 235 "linearly changed from min speed to max speed" 234 "linearly changed from min speed to max speed" 233 "linearly changed from min speed to max speed" 232 "linearly changed from min speed to max speed" 231 "linearly changed from min speed to max speed" 230 "linearly changed from min speed to max speed" 229 "linearly changed from min speed to max speed" 228 "linearly changed from min speed to max speed" 227 "linearly changed from min speed to max speed" 226 "linearly changed from min speed to max speed" 225 "linearly changed from min speed to max speed" 224 "linearly changed from min speed to max speed" 223 "linearly changed from min speed to max speed" 222 "linearly changed from min speed to max speed" 221 "linearly changed from min speed to max speed" 220 "linearly changed from min speed to max speed" 219 "linearly changed from min speed to max speed" 218 "linearly changed from min speed to max speed" 217 "linearly changed from min speed to max speed" 216 "linearly changed from min speed to max speed" 215 "linearly changed from min speed to max speed" 214 "linearly changed from min speed to max speed" 213 "linearly changed from min speed to max speed" 212 "linearly changed from min speed to max speed" 211 "linearly changed from min speed to max speed" 210 "linearly changed from min speed to max speed" 209 "linearly changed from min speed to max speed" 208 "linearly changed from min speed to max speed" 207 "linearly changed from min speed to max speed" 206 "linearly changed from min speed to max speed" 205 "linearly changed from min speed to max speed" 204 "linearly changed from min speed to max speed" 203 "linearly changed from min speed to max speed" 202 "linearly changed from min speed to max speed" 201 "linearly changed from min speed to max speed" 200 "linearly changed from min speed to max speed" 199 "linearly changed from min speed to max speed" 198 "linearly changed from min speed to max speed" 197 "linearly changed from min speed to max speed" 196 "linearly changed from min speed to max speed" 195 "linearly changed from min speed to max speed" 194 "linearly changed from min speed to max speed" 193 "linearly changed from min speed to max speed" 192 "linearly changed from min speed to max speed" 191 "linearly changed from min speed to max speed" 190 "linearly changed from min speed to max speed" 189 "linearly changed from min speed to max speed" 188 "linearly changed from min speed to max speed" 187 "linearly changed from min speed to max speed" 186 "linearly changed from min speed to max speed" 185 "linearly changed from min speed to max speed" 184 "linearly changed from min speed to max speed" 183 "linearly changed from min speed to max speed" 182 "linearly changed from min speed to max speed" 181 "linearly changed from min speed to max speed" 180 "linearly changed from min speed to max speed" 179 "linearly changed from min speed to max speed" 178 "linearly changed from min speed to max speed" 177 "linearly changed from min speed to max speed" 176 "linearly changed from min speed to max speed" 175 "linearly changed from min speed to max speed" 174 "linearly changed from min speed to max speed" 173 "linearly changed from min speed to max speed" 172 "linearly changed from min speed to max speed" 171 "linearly changed from min speed to max speed" 170 "linearly changed from min speed to max speed" 169 "linearly changed from min speed to max speed" 168 "linearly changed from min speed to max speed" 167 "linearly changed from min speed to max speed" 166 "linearly changed from min speed to max speed" 165 "linearly changed from min speed to max speed" 164 "linearly changed from min speed to max speed" 163 "linearly changed from min speed to max speed" 162 "linearly changed from min speed to max speed" 161 "linearly changed from min speed to max speed" 160 "linearly changed from min speed to max speed" 159 "linearly changed from min speed to max speed" 158 "linearly changed from min speed to max speed" 157 "linearly changed from min speed to max speed" 156 "linearly changed from min speed to max speed" 155 "linearly changed from min speed to max speed" 154 "linearly changed from min speed to max speed" 153 "linearly changed from min speed to max speed" 152 "linearly changed from min speed to max speed" 151 "linearly changed from min speed to max speed" 150 "linearly changed from min speed to max speed" 149 "linearly changed from min speed to max speed" 148 "linearly changed from min speed to max speed" 147 "linearly changed from min speed to max speed" 146 "linearly changed from min speed to max speed" 145 "linearly changed from min speed to max speed" 144 "linearly changed from min speed to max speed" 143 "linearly changed from min speed to max speed" 142 "linearly changed from min speed to max speed" 141 "linearly changed from min speed to max speed" 140 "linearly changed from min speed to max speed" 139 "linearly changed from min speed to max speed" 138 "linearly changed from min speed to max speed" 137 "linearly changed from min speed to max speed" 136 "linearly changed from min speed to max speed" 135 "linearly changed from min speed to max speed" 134 "linearly changed from min speed to max speed" 133 "linearly changed from min speed to max speed" 132 "linearly changed from min speed to max speed" 131 "linearly changed from min speed to max speed" 130 "linearly changed from min speed to max speed" 129 "linearly changed from min speed to max speed" 128 "linearly changed from min speed to max speed" 127 "linearly changed from min speed to max speed" 126 "linearly changed from min speed to max speed" 125 "linearly changed from min speed to max speed" 124 "linearly changed from min speed to max speed" 123 "linearly changed from min speed to max speed" 122 "linearly changed from min speed to max speed" 121 "linearly changed from min speed to max speed" 120 "linearly changed from min speed to max speed" 119 "linearly changed from min speed to max speed" 118 "linearly changed from min speed to max speed" 117 "linearly changed from min speed to max speed" 116 "linearly changed from min speed to max speed" 115 "linearly changed from min speed to max speed" 114 "linearly changed from min speed to max speed" 113 "linearly changed from min speed to max speed" 112 "linearly changed from min speed to max speed" 111 "linearly changed from min speed to max speed" 110 "linearly changed from min speed to max speed" 109 "linearly changed from min speed to max speed" 108 "linearly changed from min speed to max speed" 107 "linearly changed from min speed to max speed" 106 "linearly changed from min speed to max speed" 105 "linearly changed from min speed to max speed" 104 "linearly changed from min speed to max speed" 103 "linearly changed from min speed to max speed" 102 "linearly changed from min speed to max speed" 101 "linearly changed from min speed to max speed" 100 "linearly changed from min speed to max speed" 99 "linearly changed from min speed to max speed" 98 "linearly changed from min speed to max speed" 97 "linearly changed from min speed to max speed" 96 "linearly changed from min speed to max speed" 95 "linearly changed from min speed to max speed" 94 "linearly changed from min speed to max speed" 93 "linearly changed from min speed to max speed" 92 "linearly changed from min speed to max speed" 91 "linearly changed from min speed to max speed" 90 "linearly changed from min speed to max speed" 89 "linearly changed from min speed to max speed" 88 "linearly changed from min speed to max speed" 87 "linearly changed from min speed to max speed" 86 "linearly changed from min speed to max speed" 85 "linearly changed from min speed to max speed" 84 "linearly changed from min speed to max speed" 83 "linearly changed from min speed to max speed" 82 "linearly changed from min speed to max speed" 81 "linearly changed from min speed to max speed" 80 "linearly changed from min speed to max speed" 79 "linearly changed from min speed to max speed" 78 "linearly changed from min speed to max speed" 77 "linearly changed from min speed to max speed" 76 "linearly changed from min speed to max speed" 75 "linearly changed from min speed to max speed" 74 "linearly changed from min speed to max speed" 73 "linearly changed from min speed to max speed" 72 "linearly changed from min speed to max speed" 71 "linearly changed from min speed to max speed" 70 "linearly changed from min speed to max speed" 69 "linearly changed from min speed to max speed" 68 "linearly changed from min speed to max speed" 67 "linearly changed from min speed to max speed" 66 "linearly changed from min speed to max speed" 65 "linearly changed from min speed to max speed" 64 "linearly changed from min speed to max speed" 63 "linearly changed from min speed to max speed" 62 "linearly changed from min speed to max speed" 61 "linearly changed from min speed to max speed" 60 "linearly changed from min speed to max speed" 59 "linearly changed from min speed to max speed" 58 "linearly changed from min speed to max speed" 57 "linearly changed from min speed to max speed" 56 "linearly changed from min speed to max speed" 55 "linearly changed from min speed to max speed" 54 "linearly changed from min speed to max speed" 53 "linearly changed from min speed to max speed" 52 "linearly changed from min speed to max speed" 51 "linearly changed from min speed to max speed" 50 "linearly changed from min speed to max speed" 49 "min speed rpm" 48 "min speed rpm" 47 "min speed rpm" 46 "min speed rpm" 45 "min speed rpm" 44 "min speed rpm" 43 "min speed rpm" 42 "min speed rpm" 41 "min speed rpm" 40 "min speed rpm" 39 "min speed rpm" 38 "min speed rpm" 37 "min speed rpm" 36 "min speed rpm" 35 "min speed rpm" 34 "min speed rpm" 33 "min speed rpm" 32 "min speed rpm" 31 "min speed rpm" 30 "min speed rpm" 29 "min speed rpm" 28 "min speed rpm" 27 "min speed rpm" 26 "min speed rpm" 25 "min speed rpm" 24 "min speed rpm" 23 "min speed rpm" 22 "min speed rpm" 21 "min speed rpm" 20 "min speed rpm" 19 "min speed rpm" 18 "min speed rpm" 17 "min speed rpm" 16 "min speed rpm" 15 "min speed rpm" 14 "min speed rpm" 13 "min speed rpm" 12 "min speed rpm" 11 "min speed rpm" 10 "min speed rpm" 9 "min speed rpm" 8 "min speed rpm" 7 "min speed rpm" 6 "min speed rpm" 5 "min speed rpm" 4 "min speed rpm" 3 "0 rpm" 2 "0 rpm" 1 "0 rpm" 0 "0 rpm" ;
VAL_ 796 EXV2_Cmd_Init_Rq 7 "Invalid" 6 "not defined" 5 "not defined" 4 "not defined" 3 "not defined" 2 "waiting for Sequence to finish" 1 "start Init-Sequence" 0 "No Request" ;
VAL_ 796 EXV_Cmd_Init_Rq 7 "Invalid" 6 "not defined" 5 "not defined" 4 "not defined" 3 "not defined" 2 "waiting for Sequence to finish" 1 "start Init-Sequence" 0 "No Request" ;
VAL_ 796 EWP1_Default_Operation_EWP_Rq 1 "Default Operation" 0 "Default Sleep" ;
VAL_ 796 EWP2_Default_Operation_EWP_Rq 1 "Default Operation" 0 "Default Sleep" ;
VAL_ 796 EWP3_Default_Operation_EWP_Rq 1 "Default Operation" 0 "Default Sleep" ;
VAL_ 796 EXV2_Cmd_Move_Enbl 1 "Move to Commanded Position" 0 "Ignore Commanded Position" ;
VAL_ 796 EXV_Cmd_Move_Enbl 1 "Move to Commanded Position" 0 "Ignore Commanded Position" ;
VAL_ 796 TrailerModeSta 3 "YELLOW" 2 "RED" 1 "GREEN" 0 "OFF" ;
VAL_ 796 TrailerCheck 1 "Complete" 0 "Detecting" ;
VAL_ 796 ZFR_BCM_ChargerDoorSW_Sta 1 "Open" 0 "Close" ;
VAL_ 796 FLTurnLPErr 1 "Error" 0 "Normal" ;
VAL_ 796 FLTurn_Light_Warning 1 "On" 0 "Off" ;
VAL_ 796 FRPosLPErr 1 "Error" 0 "Normal" ;
VAL_ 796 FRTurnLPErr 1 "Error" 0 "Normal" ;
VAL_ 796 FRTurn_Light_Warning 1 "On" 0 "Off" ;
VAL_ 796 LADBErr 1 "Error" 0 "Normal" ;
VAL_ 796 LADB_Hibeam_Indication 1 "On" 0 "Off" ;
VAL_ 796 LADB_Operation_Status 1 "On" 0 "Off" ;
VAL_ 796 LADB_Warning 1 "On" 0 "Off" ;
VAL_ 796 LAHB_Warning 1 "On" 0 "Off" ;
VAL_ 796 LDRLErr 1 "Error" 0 "Normal" ;
VAL_ 796 LDRL_Warning 1 "On" 0 "Off" ;
VAL_ 796 LH_BeamErr 1 "Error" 0 "Normal" ;
VAL_ 796 LLB_Warning 1 "On" 0 "Off" ;
VAL_ 796 LL_BeamErr 1 "Error" 0 "Normal" ;
VAL_ 796 Lposition_Lamp_Warning 1 "On" 0 "Off" ;
VAL_ 796 RADBErr 1 "Error" 0 "Normal" ;
VAL_ 796 RADB_Hibeam_Indication 1 "On" 0 "Off" ;
VAL_ 796 RADB_Operation_Status 1 "On" 0 "Off" ;
VAL_ 796 RADB_Warning 1 "On" 0 "Off" ;
VAL_ 796 RAHB_Warning 1 "On" 0 "Off" ;
VAL_ 796 RDRLErr 1 "Error" 0 "Normal" ;
VAL_ 796 RDRL_Warning 1 "On" 0 "Off" ;
VAL_ 796 RH_BeamErr 1 "Error" 0 "Normal" ;
VAL_ 796 RLB_Warning 1 "On" 0 "Off" ;
VAL_ 796 RL_BeamErr 1 "Error" 0 "Normal" ;
VAL_ 796 Rposition_Lamp_Warning 1 "On" 0 "Off" ;
VAL_ 796 FLPosLPErr 1 "Error" 0 "Normal" ;
VAL_ 796 ZFR_THCM_CLEVentActZ_Sta 127 "Invalid" 126 "OFF" ;
VAL_ 796 ZFR_THCM_CREVentActY_Sta 127 "Invalid" 126 "OFF" ;
VAL_ 796 ZFR_THCM_CREVentActZ_Sta 127 "Invalid" 126 "OFF" ;
VAL_ 796 ZFR_THCM_DrEVentActY_Sta 127 "Invalid" 126 "OFF" ;
VAL_ 796 ZFR_THCM_DrEVentActZ_Sta 127 "Invalid" 126 "OFF" ;
VAL_ 796 ZFR_THCM_PsEVentActY_Sta 127 "Invalid" 126 "OFF" ;
VAL_ 796 ZFR_THCM_PsEVentActZ_Sta 127 "Invalid" 126 "OFF" ;
VAL_ 796 ZFR_THCM_CLEVentActY_Sta 127 "Invalid" 126 "OFF" ;
VAL_ 796 ZFR_EChrg_Active_Sta 7 "Pinch Reverse" 6 "Stoped Halfway" 5 "Ready to Act" 4 "Power Closing" 3 "Power Opening" 2 "Fully Opened" 1 "Fully Closed" 0 "Signal Not Available" ;
VAL_ 796 ZFR_EChrg_Sys_Sta 3 "Signal Not Available" 2 "Abnormal" 1 "Normal" 0 "Uninitialized" ;
VAL_ 593 P_CommandToBCM 15 "Invalid" 11 "UWB Unlock" 10 "UWB Lock" 9 "NFC Command" 8 "Car Search Mute" 7 "Forced to lift anti-theft" 6 "HandleTailgate Open/Close" 5 "Failed to Lock Tailgate" 4 "Car Search" 3 "Remote Tailgate Open/Close" 2 "Unlock" 1 "Lock" 0 "Default" ;
VAL_ 593 P_DKey_Welcome 3 "UnsedandReserved" 2 "Out the welcome zone" 1 "In the welcom zone" 0 "Unavaliable" ;
VAL_ 593 P_DKey_Area_LockUnlock 3 "UnusedandReserved" 2 "In to Unlock Zone" 1 "In to Lock Zone" 0 "Unavailable" ;
VAL_ 593 P_DKey_Area_PS 3 "UnsedandReserved" 2 "Out of PS Zone" 1 "In to PS Zone" 0 "Unavaliable" ;
VAL_ 593 P_UID_LowPower 1 "On" 0 "Off" ;
VAL_ 593 P_CommandToPTG 5 "invalid" 4 "PTG-legal Key in Indoor and Outdoor(ID identical)" 3 "PTG-legal Key in Indoor and Outdoor(ID different)" 2 "PTG-legal Key in Indoor" 1 "PTG-legal Key in Outdoor" 0 "Default" ;
VAL_ 593 P_Dkey_Show_IVI 7 "invalid" 6 "IVI PHONE Green" 5 "IVI PHONE Red" 4 "IVI UID Green" 3 "IVI UID Red" 2 "IVI NFC Card Green" 1 "IVI NFC Card Red" 0 "Default" ;
VAL_ 593 P_KeyMode 6 "Invalid" 5 "NFC" 4 "PHONE (BLE)" 3 "PHONE (UWB)" 2 "UID (BLE)" 1 "UID (UWB)" 0 "Default" ;
VAL_ 593 P_DKey_Area_PTG 3 "UnsedandReserved" 2 "Out of SPTG Zone" 1 "In to SPTG Zone" 0 "Unavaliable" ;
VAL_ 593 P_KeyMiss 1 "Key Miss" 0 "Default" ;
VAL_ 593 DKC_Re_VehData 1 "Request" 0 "No Request" ;
VAL_ 593 DKC_ParkingMode_Cmd 4 "remote vehicle reverse" 3 "remote vehicle forward" 2 "remote parking" 1 "Standby (Ready)" 0 "Disable" ;
VAL_ 593 DKC_PDkeyAreaRAPS_Sta 2 "Out of RAPS Zone" 1 "In to RAPS Zone" 0 "Unavailable" ;
VAL_ 593 DKC_KeyNum_Sta 15 "Invalid" 14 "Key 14" 13 "Key 13" 12 "Key 12" 11 "Key 11" 10 "Key 10" 9 "Key 9" 8 "Key 8" 7 "Key 7" 6 "Key 6" 5 "Key 5" 4 "Key 4" 3 "Key 3" 2 "Key 2" 1 "Key 1" 0 "No Request" ;
VAL_ 593 DKC_KeyType_Sta 3 "Invalid" 2 "NFC" 1 "UID" 0 "No Request" ;
VAL_ 596 EXV_Rsp_Fault_Stat 15 "not defined" 14 "not defined" 13 "not defined" 12 "not defined" 11 "not defined" 10 "not defined" 9 "not defined" 8 "not defined" 7 "not defined" 6 "not defined" 5 "not defined" 4 "not defined" 3 "Over temperature shutdown" 2 "Motor-Coil open load" 1 "Motor-Coil shorted" 0 "Actuator Not Faulted" ;
VAL_ 596 EXV_Rsp_CurInit_Stat 3 "Unused and Undefined" 2 "Initialized" 1 "Initialization in Process" 0 "Not Initialized" ;
VAL_ 596 EXV_Rsp_OvrTemp_Warn 3 "not defined" 2 "not defined" 1 "High Temperature Warning" 0 "Ok" ;
VAL_ 596 EXV_Rsp_Volt_Stat 3 "not defined" 2 "Under voltage" 1 "Overvoltage" 0 "Voltage Range ok" ;
VAL_ 596 EXV_RsErr_EXV 1 "Comm Error detected" 0 "No Comm Error" ;
VAL_ 596 EXV_Rsp_Run_Stat 1 "Actuator is moving" 0 "Actuator is not moving" ;
VAL_ 596 EWP1_RsErr_EWP 1 "ERROR" 0 "NO ERROR" ;
VAL_ 596 EWP1_SupVolt_Error 2 "SNA" 1 "ERROR" 0 "NO ERROR" ;
VAL_ 596 EWP1_RPM_Target_Stat 255 "Invalid" 254 "max speed rpm" 253 "max speed rpm" 252 "max speed rpm" 251 "max speed rpm" 250 "linearly changed from min speed to max speed" 249 "linearly changed from min speed to max speed" 248 "linearly changed from min speed to max speed" 247 "linearly changed from min speed to max speed" 246 "linearly changed from min speed to max speed" 245 "linearly changed from min speed to max speed" 244 "linearly changed from min speed to max speed" 243 "linearly changed from min speed to max speed" 242 "linearly changed from min speed to max speed" 241 "linearly changed from min speed to max speed" 240 "linearly changed from min speed to max speed" 239 "linearly changed from min speed to max speed" 238 "linearly changed from min speed to max speed" 237 "linearly changed from min speed to max speed" 236 "linearly changed from min speed to max speed" 235 "linearly changed from min speed to max speed" 234 "linearly changed from min speed to max speed" 233 "linearly changed from min speed to max speed" 232 "linearly changed from min speed to max speed" 231 "linearly changed from min speed to max speed" 230 "linearly changed from min speed to max speed" 229 "linearly changed from min speed to max speed" 228 "linearly changed from min speed to max speed" 227 "linearly changed from min speed to max speed" 226 "linearly changed from min speed to max speed" 225 "linearly changed from min speed to max speed" 224 "linearly changed from min speed to max speed" 223 "linearly changed from min speed to max speed" 222 "linearly changed from min speed to max speed" 221 "linearly changed from min speed to max speed" 220 "linearly changed from min speed to max speed" 219 "linearly changed from min speed to max speed" 218 "linearly changed from min speed to max speed" 217 "linearly changed from min speed to max speed" 216 "linearly changed from min speed to max speed" 215 "linearly changed from min speed to max speed" 214 "linearly changed from min speed to max speed" 213 "linearly changed from min speed to max speed" 212 "linearly changed from min speed to max speed" 211 "linearly changed from min speed to max speed" 210 "linearly changed from min speed to max speed" 209 "linearly changed from min speed to max speed" 208 "linearly changed from min speed to max speed" 207 "linearly changed from min speed to max speed" 206 "linearly changed from min speed to max speed" 205 "linearly changed from min speed to max speed" 204 "linearly changed from min speed to max speed" 203 "linearly changed from min speed to max speed" 202 "linearly changed from min speed to max speed" 201 "linearly changed from min speed to max speed" 200 "linearly changed from min speed to max speed" 199 "linearly changed from min speed to max speed" 198 "linearly changed from min speed to max speed" 197 "linearly changed from min speed to max speed" 196 "linearly changed from min speed to max speed" 195 "linearly changed from min speed to max speed" 194 "linearly changed from min speed to max speed" 193 "linearly changed from min speed to max speed" 192 "linearly changed from min speed to max speed" 191 "linearly changed from min speed to max speed" 190 "linearly changed from min speed to max speed" 189 "linearly changed from min speed to max speed" 188 "linearly changed from min speed to max speed" 187 "linearly changed from min speed to max speed" 186 "linearly changed from min speed to max speed" 185 "linearly changed from min speed to max speed" 184 "linearly changed from min speed to max speed" 183 "linearly changed from min speed to max speed" 182 "linearly changed from min speed to max speed" 181 "linearly changed from min speed to max speed" 180 "linearly changed from min speed to max speed" 179 "linearly changed from min speed to max speed" 178 "linearly changed from min speed to max speed" 177 "linearly changed from min speed to max speed" 176 "linearly changed from min speed to max speed" 175 "linearly changed from min speed to max speed" 174 "linearly changed from min speed to max speed" 173 "linearly changed from min speed to max speed" 172 "linearly changed from min speed to max speed" 171 "linearly changed from min speed to max speed" 170 "linearly changed from min speed to max speed" 169 "linearly changed from min speed to max speed" 168 "linearly changed from min speed to max speed" 167 "linearly changed from min speed to max speed" 166 "linearly changed from min speed to max speed" 165 "linearly changed from min speed to max speed" 164 "linearly changed from min speed to max speed" 163 "linearly changed from min speed to max speed" 162 "linearly changed from min speed to max speed" 161 "linearly changed from min speed to max speed" 160 "linearly changed from min speed to max speed" 159 "linearly changed from min speed to max speed" 158 "linearly changed from min speed to max speed" 157 "linearly changed from min speed to max speed" 156 "linearly changed from min speed to max speed" 155 "linearly changed from min speed to max speed" 154 "linearly changed from min speed to max speed" 153 "linearly changed from min speed to max speed" 152 "linearly changed from min speed to max speed" 151 "linearly changed from min speed to max speed" 150 "linearly changed from min speed to max speed" 149 "linearly changed from min speed to max speed" 148 "linearly changed from min speed to max speed" 147 "linearly changed from min speed to max speed" 146 "linearly changed from min speed to max speed" 145 "linearly changed from min speed to max speed" 144 "linearly changed from min speed to max speed" 143 "linearly changed from min speed to max speed" 142 "linearly changed from min speed to max speed" 141 "linearly changed from min speed to max speed" 140 "linearly changed from min speed to max speed" 139 "linearly changed from min speed to max speed" 138 "linearly changed from min speed to max speed" 137 "linearly changed from min speed to max speed" 136 "linearly changed from min speed to max speed" 135 "linearly changed from min speed to max speed" 134 "linearly changed from min speed to max speed" 133 "linearly changed from min speed to max speed" 132 "linearly changed from min speed to max speed" 131 "linearly changed from min speed to max speed" 130 "linearly changed from min speed to max speed" 129 "linearly changed from min speed to max speed" 128 "linearly changed from min speed to max speed" 127 "linearly changed from min speed to max speed" 126 "linearly changed from min speed to max speed" 125 "linearly changed from min speed to max speed" 124 "linearly changed from min speed to max speed" 123 "linearly changed from min speed to max speed" 122 "linearly changed from min speed to max speed" 121 "linearly changed from min speed to max speed" 120 "linearly changed from min speed to max speed" 119 "linearly changed from min speed to max speed" 118 "linearly changed from min speed to max speed" 117 "linearly changed from min speed to max speed" 116 "linearly changed from min speed to max speed" 115 "linearly changed from min speed to max speed" 114 "linearly changed from min speed to max speed" 113 "linearly changed from min speed to max speed" 112 "linearly changed from min speed to max speed" 111 "linearly changed from min speed to max speed" 110 "linearly changed from min speed to max speed" 109 "linearly changed from min speed to max speed" 108 "linearly changed from min speed to max speed" 107 "linearly changed from min speed to max speed" 106 "linearly changed from min speed to max speed" 105 "linearly changed from min speed to max speed" 104 "linearly changed from min speed to max speed" 103 "linearly changed from min speed to max speed" 102 "linearly changed from min speed to max speed" 101 "linearly changed from min speed to max speed" 100 "linearly changed from min speed to max speed" 99 "linearly changed from min speed to max speed" 98 "linearly changed from min speed to max speed" 97 "linearly changed from min speed to max speed" 96 "linearly changed from min speed to max speed" 95 "linearly changed from min speed to max speed" 94 "linearly changed from min speed to max speed" 93 "linearly changed from min speed to max speed" 92 "linearly changed from min speed to max speed" 91 "linearly changed from min speed to max speed" 90 "linearly changed from min speed to max speed" 89 "linearly changed from min speed to max speed" 88 "linearly changed from min speed to max speed" 87 "linearly changed from min speed to max speed" 86 "linearly changed from min speed to max speed" 85 "linearly changed from min speed to max speed" 84 "linearly changed from min speed to max speed" 83 "linearly changed from min speed to max speed" 82 "linearly changed from min speed to max speed" 81 "linearly changed from min speed to max speed" 80 "linearly changed from min speed to max speed" 79 "linearly changed from min speed to max speed" 78 "linearly changed from min speed to max speed" 77 "linearly changed from min speed to max speed" 76 "linearly changed from min speed to max speed" 75 "linearly changed from min speed to max speed" 74 "linearly changed from min speed to max speed" 73 "linearly changed from min speed to max speed" 72 "linearly changed from min speed to max speed" 71 "linearly changed from min speed to max speed" 70 "linearly changed from min speed to max speed" 69 "linearly changed from min speed to max speed" 68 "linearly changed from min speed to max speed" 67 "linearly changed from min speed to max speed" 66 "linearly changed from min speed to max speed" 65 "linearly changed from min speed to max speed" 64 "linearly changed from min speed to max speed" 63 "linearly changed from min speed to max speed" 62 "linearly changed from min speed to max speed" 61 "linearly changed from min speed to max speed" 60 "linearly changed from min speed to max speed" 59 "linearly changed from min speed to max speed" 58 "linearly changed from min speed to max speed" 57 "linearly changed from min speed to max speed" 56 "linearly changed from min speed to max speed" 55 "linearly changed from min speed to max speed" 54 "linearly changed from min speed to max speed" 53 "linearly changed from min speed to max speed" 52 "linearly changed from min speed to max speed" 51 "linearly changed from min speed to max speed" 50 "linearly changed from min speed to max speed" 49 "min speed rpm" 48 "min speed rpm" 47 "min speed rpm" 46 "min speed rpm" 45 "min speed rpm" 44 "min speed rpm" 43 "min speed rpm" 42 "min speed rpm" 41 "min speed rpm" 40 "min speed rpm" 39 "min speed rpm" 38 "min speed rpm" 37 "min speed rpm" 36 "min speed rpm" 35 "min speed rpm" 34 "min speed rpm" 33 "min speed rpm" 32 "min speed rpm" 31 "min speed rpm" 30 "min speed rpm" 29 "min speed rpm" 28 "min speed rpm" 27 "min speed rpm" 26 "min speed rpm" 25 "min speed rpm" 24 "min speed rpm" 23 "min speed rpm" 22 "min speed rpm" 21 "min speed rpm" 20 "min speed rpm" 19 "min speed rpm" 18 "min speed rpm" 17 "min speed rpm" 16 "min speed rpm" 15 "min speed rpm" 14 "min speed rpm" 13 "min speed rpm" 12 "min speed rpm" 11 "min speed rpm" 10 "min speed rpm" 9 "min speed rpm" 8 "min speed rpm" 7 "min speed rpm" 6 "min speed rpm" 5 "min speed rpm" 4 "min speed rpm" 3 "0 rpm" 2 "0 rpm" 1 "0 rpm" 0 "0 rpm" ;
VAL_ 596 EWP1_RPM_ActlVal_Stat 255 "Invalid" 254 "max speed rpm" 253 "max speed rpm" 252 "max speed rpm" 251 "max speed rpm" 250 "linearly changed from min speed to max speed" 249 "linearly changed from min speed to max speed" 248 "linearly changed from min speed to max speed" 247 "linearly changed from min speed to max speed" 246 "linearly changed from min speed to max speed" 245 "linearly changed from min speed to max speed" 244 "linearly changed from min speed to max speed" 243 "linearly changed from min speed to max speed" 242 "linearly changed from min speed to max speed" 241 "linearly changed from min speed to max speed" 240 "linearly changed from min speed to max speed" 239 "linearly changed from min speed to max speed" 238 "linearly changed from min speed to max speed" 237 "linearly changed from min speed to max speed" 236 "linearly changed from min speed to max speed" 235 "linearly changed from min speed to max speed" 234 "linearly changed from min speed to max speed" 233 "linearly changed from min speed to max speed" 232 "linearly changed from min speed to max speed" 231 "linearly changed from min speed to max speed" 230 "linearly changed from min speed to max speed" 229 "linearly changed from min speed to max speed" 228 "linearly changed from min speed to max speed" 227 "linearly changed from min speed to max speed" 226 "linearly changed from min speed to max speed" 225 "linearly changed from min speed to max speed" 224 "linearly changed from min speed to max speed" 223 "linearly changed from min speed to max speed" 222 "linearly changed from min speed to max speed" 221 "linearly changed from min speed to max speed" 220 "linearly changed from min speed to max speed" 219 "linearly changed from min speed to max speed" 218 "linearly changed from min speed to max speed" 217 "linearly changed from min speed to max speed" 216 "linearly changed from min speed to max speed" 215 "linearly changed from min speed to max speed" 214 "linearly changed from min speed to max speed" 213 "linearly changed from min speed to max speed" 212 "linearly changed from min speed to max speed" 211 "linearly changed from min speed to max speed" 210 "linearly changed from min speed to max speed" 209 "linearly changed from min speed to max speed" 208 "linearly changed from min speed to max speed" 207 "linearly changed from min speed to max speed" 206 "linearly changed from min speed to max speed" 205 "linearly changed from min speed to max speed" 204 "linearly changed from min speed to max speed" 203 "linearly changed from min speed to max speed" 202 "linearly changed from min speed to max speed" 201 "linearly changed from min speed to max speed" 200 "linearly changed from min speed to max speed" 199 "linearly changed from min speed to max speed" 198 "linearly changed from min speed to max speed" 197 "linearly changed from min speed to max speed" 196 "linearly changed from min speed to max speed" 195 "linearly changed from min speed to max speed" 194 "linearly changed from min speed to max speed" 193 "linearly changed from min speed to max speed" 192 "linearly changed from min speed to max speed" 191 "linearly changed from min speed to max speed" 190 "linearly changed from min speed to max speed" 189 "linearly changed from min speed to max speed" 188 "linearly changed from min speed to max speed" 187 "linearly changed from min speed to max speed" 186 "linearly changed from min speed to max speed" 185 "linearly changed from min speed to max speed" 184 "linearly changed from min speed to max speed" 183 "linearly changed from min speed to max speed" 182 "linearly changed from min speed to max speed" 181 "linearly changed from min speed to max speed" 180 "linearly changed from min speed to max speed" 179 "linearly changed from min speed to max speed" 178 "linearly changed from min speed to max speed" 177 "linearly changed from min speed to max speed" 176 "linearly changed from min speed to max speed" 175 "linearly changed from min speed to max speed" 174 "linearly changed from min speed to max speed" 173 "linearly changed from min speed to max speed" 172 "linearly changed from min speed to max speed" 171 "linearly changed from min speed to max speed" 170 "linearly changed from min speed to max speed" 169 "linearly changed from min speed to max speed" 168 "linearly changed from min speed to max speed" 167 "linearly changed from min speed to max speed" 166 "linearly changed from min speed to max speed" 165 "linearly changed from min speed to max speed" 164 "linearly changed from min speed to max speed" 163 "linearly changed from min speed to max speed" 162 "linearly changed from min speed to max speed" 161 "linearly changed from min speed to max speed" 160 "linearly changed from min speed to max speed" 159 "linearly changed from min speed to max speed" 158 "linearly changed from min speed to max speed" 157 "linearly changed from min speed to max speed" 156 "linearly changed from min speed to max speed" 155 "linearly changed from min speed to max speed" 154 "linearly changed from min speed to max speed" 153 "linearly changed from min speed to max speed" 152 "linearly changed from min speed to max speed" 151 "linearly changed from min speed to max speed" 150 "linearly changed from min speed to max speed" 149 "linearly changed from min speed to max speed" 148 "linearly changed from min speed to max speed" 147 "linearly changed from min speed to max speed" 146 "linearly changed from min speed to max speed" 145 "linearly changed from min speed to max speed" 144 "linearly changed from min speed to max speed" 143 "linearly changed from min speed to max speed" 142 "linearly changed from min speed to max speed" 141 "linearly changed from min speed to max speed" 140 "linearly changed from min speed to max speed" 139 "linearly changed from min speed to max speed" 138 "linearly changed from min speed to max speed" 137 "linearly changed from min speed to max speed" 136 "linearly changed from min speed to max speed" 135 "linearly changed from min speed to max speed" 134 "linearly changed from min speed to max speed" 133 "linearly changed from min speed to max speed" 132 "linearly changed from min speed to max speed" 131 "linearly changed from min speed to max speed" 130 "linearly changed from min speed to max speed" 129 "linearly changed from min speed to max speed" 128 "linearly changed from min speed to max speed" 127 "linearly changed from min speed to max speed" 126 "linearly changed from min speed to max speed" 125 "linearly changed from min speed to max speed" 124 "linearly changed from min speed to max speed" 123 "linearly changed from min speed to max speed" 122 "linearly changed from min speed to max speed" 121 "linearly changed from min speed to max speed" 120 "linearly changed from min speed to max speed" 119 "linearly changed from min speed to max speed" 118 "linearly changed from min speed to max speed" 117 "linearly changed from min speed to max speed" 116 "linearly changed from min speed to max speed" 115 "linearly changed from min speed to max speed" 114 "linearly changed from min speed to max speed" 113 "linearly changed from min speed to max speed" 112 "linearly changed from min speed to max speed" 111 "linearly changed from min speed to max speed" 110 "linearly changed from min speed to max speed" 109 "linearly changed from min speed to max speed" 108 "linearly changed from min speed to max speed" 107 "linearly changed from min speed to max speed" 106 "linearly changed from min speed to max speed" 105 "linearly changed from min speed to max speed" 104 "linearly changed from min speed to max speed" 103 "linearly changed from min speed to max speed" 102 "linearly changed from min speed to max speed" 101 "linearly changed from min speed to max speed" 100 "linearly changed from min speed to max speed" 99 "linearly changed from min speed to max speed" 98 "linearly changed from min speed to max speed" 97 "linearly changed from min speed to max speed" 96 "linearly changed from min speed to max speed" 95 "linearly changed from min speed to max speed" 94 "linearly changed from min speed to max speed" 93 "linearly changed from min speed to max speed" 92 "linearly changed from min speed to max speed" 91 "linearly changed from min speed to max speed" 90 "linearly changed from min speed to max speed" 89 "linearly changed from min speed to max speed" 88 "linearly changed from min speed to max speed" 87 "linearly changed from min speed to max speed" 86 "linearly changed from min speed to max speed" 85 "linearly changed from min speed to max speed" 84 "linearly changed from min speed to max speed" 83 "linearly changed from min speed to max speed" 82 "linearly changed from min speed to max speed" 81 "linearly changed from min speed to max speed" 80 "linearly changed from min speed to max speed" 79 "linearly changed from min speed to max speed" 78 "linearly changed from min speed to max speed" 77 "linearly changed from min speed to max speed" 76 "linearly changed from min speed to max speed" 75 "linearly changed from min speed to max speed" 74 "linearly changed from min speed to max speed" 73 "linearly changed from min speed to max speed" 72 "linearly changed from min speed to max speed" 71 "linearly changed from min speed to max speed" 70 "linearly changed from min speed to max speed" 69 "linearly changed from min speed to max speed" 68 "linearly changed from min speed to max speed" 67 "linearly changed from min speed to max speed" 66 "linearly changed from min speed to max speed" 65 "linearly changed from min speed to max speed" 64 "linearly changed from min speed to max speed" 63 "linearly changed from min speed to max speed" 62 "linearly changed from min speed to max speed" 61 "linearly changed from min speed to max speed" 60 "linearly changed from min speed to max speed" 59 "linearly changed from min speed to max speed" 58 "linearly changed from min speed to max speed" 57 "linearly changed from min speed to max speed" 56 "linearly changed from min speed to max speed" 55 "linearly changed from min speed to max speed" 54 "linearly changed from min speed to max speed" 53 "linearly changed from min speed to max speed" 52 "linearly changed from min speed to max speed" 51 "linearly changed from min speed to max speed" 50 "linearly changed from min speed to max speed" 49 "min speed rpm" 48 "min speed rpm" 47 "min speed rpm" 46 "min speed rpm" 45 "min speed rpm" 44 "min speed rpm" 43 "min speed rpm" 42 "min speed rpm" 41 "min speed rpm" 40 "min speed rpm" 39 "min speed rpm" 38 "min speed rpm" 37 "min speed rpm" 36 "min speed rpm" 35 "min speed rpm" 34 "min speed rpm" 33 "min speed rpm" 32 "min speed rpm" 31 "min speed rpm" 30 "min speed rpm" 29 "min speed rpm" 28 "min speed rpm" 27 "min speed rpm" 26 "min speed rpm" 25 "min speed rpm" 24 "min speed rpm" 23 "min speed rpm" 22 "min speed rpm" 21 "min speed rpm" 20 "min speed rpm" 19 "min speed rpm" 18 "min speed rpm" 17 "min speed rpm" 16 "min speed rpm" 15 "min speed rpm" 14 "min speed rpm" 13 "min speed rpm" 12 "min speed rpm" 11 "min speed rpm" 10 "min speed rpm" 9 "min speed rpm" 8 "min speed rpm" 7 "min speed rpm" 6 "min speed rpm" 5 "min speed rpm" 4 "min speed rpm" 3 "0 rpm" 2 "0 rpm" 1 "0 rpm" 0 "0 rpm" ;
VAL_ 596 EWP1_Curr_Stat 255 "invalid" ;
VAL_ 596 EWP1_Block_Error 3 "Invalid" 2 "SNA" 1 "ERROR" 0 "NO ERROR" ;
VAL_ 596 EWP1_DryRun_Error 3 "Invalid" 2 "SNA" 1 "ERROR" 0 "NO ERROR" ;
VAL_ 596 EWP1_OverCurr_Error 3 "Invalid" 2 "SNA" 1 "ERROR" 0 "NO ERROR" ;
VAL_ 596 EWP1_OverTemp_Error 2 "OverTempDegrade" 1 "ERROR" 0 "NO ERROR" ;
VAL_ 596 EWP1_Temp_Stat 255 "Invalid" ;
VAL_ 596 EWP1_Volt_Stat 255 "Invalid" ;
VAL_ 596 EWP2_Volt_Stat 255 "Invalid" ;
VAL_ 596 EWP2_Temp_Stat 255 "Invalid" ;
VAL_ 596 EWP2_RPM_Target_Stat 255 "Invalid" 254 "max speed rpm" 253 "max speed rpm" 252 "max speed rpm" 251 "max speed rpm" 250 "linearly changed from min speed to max speed" 249 "linearly changed from min speed to max speed" 248 "linearly changed from min speed to max speed" 247 "linearly changed from min speed to max speed" 246 "linearly changed from min speed to max speed" 245 "linearly changed from min speed to max speed" 244 "linearly changed from min speed to max speed" 243 "linearly changed from min speed to max speed" 242 "linearly changed from min speed to max speed" 241 "linearly changed from min speed to max speed" 240 "linearly changed from min speed to max speed" 239 "linearly changed from min speed to max speed" 238 "linearly changed from min speed to max speed" 237 "linearly changed from min speed to max speed" 236 "linearly changed from min speed to max speed" 235 "linearly changed from min speed to max speed" 234 "linearly changed from min speed to max speed" 233 "linearly changed from min speed to max speed" 232 "linearly changed from min speed to max speed" 231 "linearly changed from min speed to max speed" 230 "linearly changed from min speed to max speed" 229 "linearly changed from min speed to max speed" 228 "linearly changed from min speed to max speed" 227 "linearly changed from min speed to max speed" 226 "linearly changed from min speed to max speed" 225 "linearly changed from min speed to max speed" 224 "linearly changed from min speed to max speed" 223 "linearly changed from min speed to max speed" 222 "linearly changed from min speed to max speed" 221 "linearly changed from min speed to max speed" 220 "linearly changed from min speed to max speed" 219 "linearly changed from min speed to max speed" 218 "linearly changed from min speed to max speed" 217 "linearly changed from min speed to max speed" 216 "linearly changed from min speed to max speed" 215 "linearly changed from min speed to max speed" 214 "linearly changed from min speed to max speed" 213 "linearly changed from min speed to max speed" 212 "linearly changed from min speed to max speed" 211 "linearly changed from min speed to max speed" 210 "linearly changed from min speed to max speed" 209 "linearly changed from min speed to max speed" 208 "linearly changed from min speed to max speed" 207 "linearly changed from min speed to max speed" 206 "linearly changed from min speed to max speed" 205 "linearly changed from min speed to max speed" 204 "linearly changed from min speed to max speed" 203 "linearly changed from min speed to max speed" 202 "linearly changed from min speed to max speed" 201 "linearly changed from min speed to max speed" 200 "linearly changed from min speed to max speed" 199 "linearly changed from min speed to max speed" 198 "linearly changed from min speed to max speed" 197 "linearly changed from min speed to max speed" 196 "linearly changed from min speed to max speed" 195 "linearly changed from min speed to max speed" 194 "linearly changed from min speed to max speed" 193 "linearly changed from min speed to max speed" 192 "linearly changed from min speed to max speed" 191 "linearly changed from min speed to max speed" 190 "linearly changed from min speed to max speed" 189 "linearly changed from min speed to max speed" 188 "linearly changed from min speed to max speed" 187 "linearly changed from min speed to max speed" 186 "linearly changed from min speed to max speed" 185 "linearly changed from min speed to max speed" 184 "linearly changed from min speed to max speed" 183 "linearly changed from min speed to max speed" 182 "linearly changed from min speed to max speed" 181 "linearly changed from min speed to max speed" 180 "linearly changed from min speed to max speed" 179 "linearly changed from min speed to max speed" 178 "linearly changed from min speed to max speed" 177 "linearly changed from min speed to max speed" 176 "linearly changed from min speed to max speed" 175 "linearly changed from min speed to max speed" 174 "linearly changed from min speed to max speed" 173 "linearly changed from min speed to max speed" 172 "linearly changed from min speed to max speed" 171 "linearly changed from min speed to max speed" 170 "linearly changed from min speed to max speed" 169 "linearly changed from min speed to max speed" 168 "linearly changed from min speed to max speed" 167 "linearly changed from min speed to max speed" 166 "linearly changed from min speed to max speed" 165 "linearly changed from min speed to max speed" 164 "linearly changed from min speed to max speed" 163 "linearly changed from min speed to max speed" 162 "linearly changed from min speed to max speed" 161 "linearly changed from min speed to max speed" 160 "linearly changed from min speed to max speed" 159 "linearly changed from min speed to max speed" 158 "linearly changed from min speed to max speed" 157 "linearly changed from min speed to max speed" 156 "linearly changed from min speed to max speed" 155 "linearly changed from min speed to max speed" 154 "linearly changed from min speed to max speed" 153 "linearly changed from min speed to max speed" 152 "linearly changed from min speed to max speed" 151 "linearly changed from min speed to max speed" 150 "linearly changed from min speed to max speed" 149 "linearly changed from min speed to max speed" 148 "linearly changed from min speed to max speed" 147 "linearly changed from min speed to max speed" 146 "linearly changed from min speed to max speed" 145 "linearly changed from min speed to max speed" 144 "linearly changed from min speed to max speed" 143 "linearly changed from min speed to max speed" 142 "linearly changed from min speed to max speed" 141 "linearly changed from min speed to max speed" 140 "linearly changed from min speed to max speed" 139 "linearly changed from min speed to max speed" 138 "linearly changed from min speed to max speed" 137 "linearly changed from min speed to max speed" 136 "linearly changed from min speed to max speed" 135 "linearly changed from min speed to max speed" 134 "linearly changed from min speed to max speed" 133 "linearly changed from min speed to max speed" 132 "linearly changed from min speed to max speed" 131 "linearly changed from min speed to max speed" 130 "linearly changed from min speed to max speed" 129 "linearly changed from min speed to max speed" 128 "linearly changed from min speed to max speed" 127 "linearly changed from min speed to max speed" 126 "linearly changed from min speed to max speed" 125 "linearly changed from min speed to max speed" 124 "linearly changed from min speed to max speed" 123 "linearly changed from min speed to max speed" 122 "linearly changed from min speed to max speed" 121 "linearly changed from min speed to max speed" 120 "linearly changed from min speed to max speed" 119 "linearly changed from min speed to max speed" 118 "linearly changed from min speed to max speed" 117 "linearly changed from min speed to max speed" 116 "linearly changed from min speed to max speed" 115 "linearly changed from min speed to max speed" 114 "linearly changed from min speed to max speed" 113 "linearly changed from min speed to max speed" 112 "linearly changed from min speed to max speed" 111 "linearly changed from min speed to max speed" 110 "linearly changed from min speed to max speed" 109 "linearly changed from min speed to max speed" 108 "linearly changed from min speed to max speed" 107 "linearly changed from min speed to max speed" 106 "linearly changed from min speed to max speed" 105 "linearly changed from min speed to max speed" 104 "linearly changed from min speed to max speed" 103 "linearly changed from min speed to max speed" 102 "linearly changed from min speed to max speed" 101 "linearly changed from min speed to max speed" 100 "linearly changed from min speed to max speed" 99 "linearly changed from min speed to max speed" 98 "linearly changed from min speed to max speed" 97 "linearly changed from min speed to max speed" 96 "linearly changed from min speed to max speed" 95 "linearly changed from min speed to max speed" 94 "linearly changed from min speed to max speed" 93 "linearly changed from min speed to max speed" 92 "linearly changed from min speed to max speed" 91 "linearly changed from min speed to max speed" 90 "linearly changed from min speed to max speed" 89 "linearly changed from min speed to max speed" 88 "linearly changed from min speed to max speed" 87 "linearly changed from min speed to max speed" 86 "linearly changed from min speed to max speed" 85 "linearly changed from min speed to max speed" 84 "linearly changed from min speed to max speed" 83 "linearly changed from min speed to max speed" 82 "linearly changed from min speed to max speed" 81 "linearly changed from min speed to max speed" 80 "linearly changed from min speed to max speed" 79 "linearly changed from min speed to max speed" 78 "linearly changed from min speed to max speed" 77 "linearly changed from min speed to max speed" 76 "linearly changed from min speed to max speed" 75 "linearly changed from min speed to max speed" 74 "linearly changed from min speed to max speed" 73 "linearly changed from min speed to max speed" 72 "linearly changed from min speed to max speed" 71 "linearly changed from min speed to max speed" 70 "linearly changed from min speed to max speed" 69 "linearly changed from min speed to max speed" 68 "linearly changed from min speed to max speed" 67 "linearly changed from min speed to max speed" 66 "linearly changed from min speed to max speed" 65 "linearly changed from min speed to max speed" 64 "linearly changed from min speed to max speed" 63 "linearly changed from min speed to max speed" 62 "linearly changed from min speed to max speed" 61 "linearly changed from min speed to max speed" 60 "linearly changed from min speed to max speed" 59 "linearly changed from min speed to max speed" 58 "linearly changed from min speed to max speed" 57 "linearly changed from min speed to max speed" 56 "linearly changed from min speed to max speed" 55 "linearly changed from min speed to max speed" 54 "linearly changed from min speed to max speed" 53 "linearly changed from min speed to max speed" 52 "linearly changed from min speed to max speed" 51 "linearly changed from min speed to max speed" 50 "linearly changed from min speed to max speed" 49 "min speed rpm" 48 "min speed rpm" 47 "min speed rpm" 46 "min speed rpm" 45 "min speed rpm" 44 "min speed rpm" 43 "min speed rpm" 42 "min speed rpm" 41 "min speed rpm" 40 "min speed rpm" 39 "min speed rpm" 38 "min speed rpm" 37 "min speed rpm" 36 "min speed rpm" 35 "min speed rpm" 34 "min speed rpm" 33 "min speed rpm" 32 "min speed rpm" 31 "min speed rpm" 30 "min speed rpm" 29 "min speed rpm" 28 "min speed rpm" 27 "min speed rpm" 26 "min speed rpm" 25 "min speed rpm" 24 "min speed rpm" 23 "min speed rpm" 22 "min speed rpm" 21 "min speed rpm" 20 "min speed rpm" 19 "min speed rpm" 18 "min speed rpm" 17 "min speed rpm" 16 "min speed rpm" 15 "min speed rpm" 14 "min speed rpm" 13 "min speed rpm" 12 "min speed rpm" 11 "min speed rpm" 10 "min speed rpm" 9 "min speed rpm" 8 "min speed rpm" 7 "min speed rpm" 6 "min speed rpm" 5 "min speed rpm" 4 "min speed rpm" 3 "0 rpm" 2 "0 rpm" 1 "0 rpm" 0 "0 rpm" ;
VAL_ 596 EWP2_RPM_ActlVal_Stat 255 "Invalid" 254 "max speed rpm" 253 "max speed rpm" 252 "max speed rpm" 251 "max speed rpm" 250 "linearly changed from min speed to max speed" 249 "linearly changed from min speed to max speed" 248 "linearly changed from min speed to max speed" 247 "linearly changed from min speed to max speed" 246 "linearly changed from min speed to max speed" 245 "linearly changed from min speed to max speed" 244 "linearly changed from min speed to max speed" 243 "linearly changed from min speed to max speed" 242 "linearly changed from min speed to max speed" 241 "linearly changed from min speed to max speed" 240 "linearly changed from min speed to max speed" 239 "linearly changed from min speed to max speed" 238 "linearly changed from min speed to max speed" 237 "linearly changed from min speed to max speed" 236 "linearly changed from min speed to max speed" 235 "linearly changed from min speed to max speed" 234 "linearly changed from min speed to max speed" 233 "linearly changed from min speed to max speed" 232 "linearly changed from min speed to max speed" 231 "linearly changed from min speed to max speed" 230 "linearly changed from min speed to max speed" 229 "linearly changed from min speed to max speed" 228 "linearly changed from min speed to max speed" 227 "linearly changed from min speed to max speed" 226 "linearly changed from min speed to max speed" 225 "linearly changed from min speed to max speed" 224 "linearly changed from min speed to max speed" 223 "linearly changed from min speed to max speed" 222 "linearly changed from min speed to max speed" 221 "linearly changed from min speed to max speed" 220 "linearly changed from min speed to max speed" 219 "linearly changed from min speed to max speed" 218 "linearly changed from min speed to max speed" 217 "linearly changed from min speed to max speed" 216 "linearly changed from min speed to max speed" 215 "linearly changed from min speed to max speed" 214 "linearly changed from min speed to max speed" 213 "linearly changed from min speed to max speed" 212 "linearly changed from min speed to max speed" 211 "linearly changed from min speed to max speed" 210 "linearly changed from min speed to max speed" 209 "linearly changed from min speed to max speed" 208 "linearly changed from min speed to max speed" 207 "linearly changed from min speed to max speed" 206 "linearly changed from min speed to max speed" 205 "linearly changed from min speed to max speed" 204 "linearly changed from min speed to max speed" 203 "linearly changed from min speed to max speed" 202 "linearly changed from min speed to max speed" 201 "linearly changed from min speed to max speed" 200 "linearly changed from min speed to max speed" 199 "linearly changed from min speed to max speed" 198 "linearly changed from min speed to max speed" 197 "linearly changed from min speed to max speed" 196 "linearly changed from min speed to max speed" 195 "linearly changed from min speed to max speed" 194 "linearly changed from min speed to max speed" 193 "linearly changed from min speed to max speed" 192 "linearly changed from min speed to max speed" 191 "linearly changed from min speed to max speed" 190 "linearly changed from min speed to max speed" 189 "linearly changed from min speed to max speed" 188 "linearly changed from min speed to max speed" 187 "linearly changed from min speed to max speed" 186 "linearly changed from min speed to max speed" 185 "linearly changed from min speed to max speed" 184 "linearly changed from min speed to max speed" 183 "linearly changed from min speed to max speed" 182 "linearly changed from min speed to max speed" 181 "linearly changed from min speed to max speed" 180 "linearly changed from min speed to max speed" 179 "linearly changed from min speed to max speed" 178 "linearly changed from min speed to max speed" 177 "linearly changed from min speed to max speed" 176 "linearly changed from min speed to max speed" 175 "linearly changed from min speed to max speed" 174 "linearly changed from min speed to max speed" 173 "linearly changed from min speed to max speed" 172 "linearly changed from min speed to max speed" 171 "linearly changed from min speed to max speed" 170 "linearly changed from min speed to max speed" 169 "linearly changed from min speed to max speed" 168 "linearly changed from min speed to max speed" 167 "linearly changed from min speed to max speed" 166 "linearly changed from min speed to max speed" 165 "linearly changed from min speed to max speed" 164 "linearly changed from min speed to max speed" 163 "linearly changed from min speed to max speed" 162 "linearly changed from min speed to max speed" 161 "linearly changed from min speed to max speed" 160 "linearly changed from min speed to max speed" 159 "linearly changed from min speed to max speed" 158 "linearly changed from min speed to max speed" 157 "linearly changed from min speed to max speed" 156 "linearly changed from min speed to max speed" 155 "linearly changed from min speed to max speed" 154 "linearly changed from min speed to max speed" 153 "linearly changed from min speed to max speed" 152 "linearly changed from min speed to max speed" 151 "linearly changed from min speed to max speed" 150 "linearly changed from min speed to max speed" 149 "linearly changed from min speed to max speed" 148 "linearly changed from min speed to max speed" 147 "linearly changed from min speed to max speed" 146 "linearly changed from min speed to max speed" 145 "linearly changed from min speed to max speed" 144 "linearly changed from min speed to max speed" 143 "linearly changed from min speed to max speed" 142 "linearly changed from min speed to max speed" 141 "linearly changed from min speed to max speed" 140 "linearly changed from min speed to max speed" 139 "linearly changed from min speed to max speed" 138 "linearly changed from min speed to max speed" 137 "linearly changed from min speed to max speed" 136 "linearly changed from min speed to max speed" 135 "linearly changed from min speed to max speed" 134 "linearly changed from min speed to max speed" 133 "linearly changed from min speed to max speed" 132 "linearly changed from min speed to max speed" 131 "linearly changed from min speed to max speed" 130 "linearly changed from min speed to max speed" 129 "linearly changed from min speed to max speed" 128 "linearly changed from min speed to max speed" 127 "linearly changed from min speed to max speed" 126 "linearly changed from min speed to max speed" 125 "linearly changed from min speed to max speed" 124 "linearly changed from min speed to max speed" 123 "linearly changed from min speed to max speed" 122 "linearly changed from min speed to max speed" 121 "linearly changed from min speed to max speed" 120 "linearly changed from min speed to max speed" 119 "linearly changed from min speed to max speed" 118 "linearly changed from min speed to max speed" 117 "linearly changed from min speed to max speed" 116 "linearly changed from min speed to max speed" 115 "linearly changed from min speed to max speed" 114 "linearly changed from min speed to max speed" 113 "linearly changed from min speed to max speed" 112 "linearly changed from min speed to max speed" 111 "linearly changed from min speed to max speed" 110 "linearly changed from min speed to max speed" 109 "linearly changed from min speed to max speed" 108 "linearly changed from min speed to max speed" 107 "linearly changed from min speed to max speed" 106 "linearly changed from min speed to max speed" 105 "linearly changed from min speed to max speed" 104 "linearly changed from min speed to max speed" 103 "linearly changed from min speed to max speed" 102 "linearly changed from min speed to max speed" 101 "linearly changed from min speed to max speed" 100 "linearly changed from min speed to max speed" 99 "linearly changed from min speed to max speed" 98 "linearly changed from min speed to max speed" 97 "linearly changed from min speed to max speed" 96 "linearly changed from min speed to max speed" 95 "linearly changed from min speed to max speed" 94 "linearly changed from min speed to max speed" 93 "linearly changed from min speed to max speed" 92 "linearly changed from min speed to max speed" 91 "linearly changed from min speed to max speed" 90 "linearly changed from min speed to max speed" 89 "linearly changed from min speed to max speed" 88 "linearly changed from min speed to max speed" 87 "linearly changed from min speed to max speed" 86 "linearly changed from min speed to max speed" 85 "linearly changed from min speed to max speed" 84 "linearly changed from min speed to max speed" 83 "linearly changed from min speed to max speed" 82 "linearly changed from min speed to max speed" 81 "linearly changed from min speed to max speed" 80 "linearly changed from min speed to max speed" 79 "linearly changed from min speed to max speed" 78 "linearly changed from min speed to max speed" 77 "linearly changed from min speed to max speed" 76 "linearly changed from min speed to max speed" 75 "linearly changed from min speed to max speed" 74 "linearly changed from min speed to max speed" 73 "linearly changed from min speed to max speed" 72 "linearly changed from min speed to max speed" 71 "linearly changed from min speed to max speed" 70 "linearly changed from min speed to max speed" 69 "linearly changed from min speed to max speed" 68 "linearly changed from min speed to max speed" 67 "linearly changed from min speed to max speed" 66 "linearly changed from min speed to max speed" 65 "linearly changed from min speed to max speed" 64 "linearly changed from min speed to max speed" 63 "linearly changed from min speed to max speed" 62 "linearly changed from min speed to max speed" 61 "linearly changed from min speed to max speed" 60 "linearly changed from min speed to max speed" 59 "linearly changed from min speed to max speed" 58 "linearly changed from min speed to max speed" 57 "linearly changed from min speed to max speed" 56 "linearly changed from min speed to max speed" 55 "linearly changed from min speed to max speed" 54 "linearly changed from min speed to max speed" 53 "linearly changed from min speed to max speed" 52 "linearly changed from min speed to max speed" 51 "linearly changed from min speed to max speed" 50 "linearly changed from min speed to max speed" 49 "min speed rpm" 48 "min speed rpm" 47 "min speed rpm" 46 "min speed rpm" 45 "min speed rpm" 44 "min speed rpm" 43 "min speed rpm" 42 "min speed rpm" 41 "min speed rpm" 40 "min speed rpm" 39 "min speed rpm" 38 "min speed rpm" 37 "min speed rpm" 36 "min speed rpm" 35 "min speed rpm" 34 "min speed rpm" 33 "min speed rpm" 32 "min speed rpm" 31 "min speed rpm" 30 "min speed rpm" 29 "min speed rpm" 28 "min speed rpm" 27 "min speed rpm" 26 "min speed rpm" 25 "min speed rpm" 24 "min speed rpm" 23 "min speed rpm" 22 "min speed rpm" 21 "min speed rpm" 20 "min speed rpm" 19 "min speed rpm" 18 "min speed rpm" 17 "min speed rpm" 16 "min speed rpm" 15 "min speed rpm" 14 "min speed rpm" 13 "min speed rpm" 12 "min speed rpm" 11 "min speed rpm" 10 "min speed rpm" 9 "min speed rpm" 8 "min speed rpm" 7 "min speed rpm" 6 "min speed rpm" 5 "min speed rpm" 4 "min speed rpm" 3 "0 rpm" 2 "0 rpm" 1 "0 rpm" 0 "0 rpm" ;
VAL_ 596 EWP2_Curr_Stat 255 "Invalid" ;
VAL_ 596 EWP2_Block_Error 3 "Invalid" 2 "SNA" 1 "ERROR" 0 "NO ERROR" ;
VAL_ 596 EWP2_DryRun_Error 3 "Invalid" 2 "SNA" 1 "ERROR" 0 "NO ERROR" ;
VAL_ 596 EWP2_OverCurr_Error 3 "Invalid" 2 "SNA" 1 "ERROR" 0 "NO ERROR" ;
VAL_ 596 EWP2_SupVolt_Error 2 "SNA" 1 "ERROR" 0 "NO ERROR" ;
VAL_ 596 EWP2_RsErr_EWP 1 "ERROR" 0 "NO ERROR" ;
VAL_ 596 EWP3_Block_Error 3 "Invalid" 2 "SNA" 1 "ERROR" 0 "NO ERROR" ;
VAL_ 596 EWP3_DryRun_Error 3 "Invalid" 2 "SNA" 1 "ERROR" 0 "NO ERROR" ;
VAL_ 596 EWP3_RPM_Target_Stat 255 "Invalid" 254 "max speed rpm" 253 "max speed rpm" 252 "max speed rpm" 251 "max speed rpm" 250 "linearly changed from min speed to max speed" 249 "linearly changed from min speed to max speed" 248 "linearly changed from min speed to max speed" 247 "linearly changed from min speed to max speed" 246 "linearly changed from min speed to max speed" 245 "linearly changed from min speed to max speed" 244 "linearly changed from min speed to max speed" 243 "linearly changed from min speed to max speed" 242 "linearly changed from min speed to max speed" 241 "linearly changed from min speed to max speed" 240 "linearly changed from min speed to max speed" 239 "linearly changed from min speed to max speed" 238 "linearly changed from min speed to max speed" 237 "linearly changed from min speed to max speed" 236 "linearly changed from min speed to max speed" 235 "linearly changed from min speed to max speed" 234 "linearly changed from min speed to max speed" 233 "linearly changed from min speed to max speed" 232 "linearly changed from min speed to max speed" 231 "linearly changed from min speed to max speed" 230 "linearly changed from min speed to max speed" 229 "linearly changed from min speed to max speed" 228 "linearly changed from min speed to max speed" 227 "linearly changed from min speed to max speed" 226 "linearly changed from min speed to max speed" 225 "linearly changed from min speed to max speed" 224 "linearly changed from min speed to max speed" 223 "linearly changed from min speed to max speed" 222 "linearly changed from min speed to max speed" 221 "linearly changed from min speed to max speed" 220 "linearly changed from min speed to max speed" 219 "linearly changed from min speed to max speed" 218 "linearly changed from min speed to max speed" 217 "linearly changed from min speed to max speed" 216 "linearly changed from min speed to max speed" 215 "linearly changed from min speed to max speed" 214 "linearly changed from min speed to max speed" 213 "linearly changed from min speed to max speed" 212 "linearly changed from min speed to max speed" 211 "linearly changed from min speed to max speed" 210 "linearly changed from min speed to max speed" 209 "linearly changed from min speed to max speed" 208 "linearly changed from min speed to max speed" 207 "linearly changed from min speed to max speed" 206 "linearly changed from min speed to max speed" 205 "linearly changed from min speed to max speed" 204 "linearly changed from min speed to max speed" 203 "linearly changed from min speed to max speed" 202 "linearly changed from min speed to max speed" 201 "linearly changed from min speed to max speed" 200 "linearly changed from min speed to max speed" 199 "linearly changed from min speed to max speed" 198 "linearly changed from min speed to max speed" 197 "linearly changed from min speed to max speed" 196 "linearly changed from min speed to max speed" 195 "linearly changed from min speed to max speed" 194 "linearly changed from min speed to max speed" 193 "linearly changed from min speed to max speed" 192 "linearly changed from min speed to max speed" 191 "linearly changed from min speed to max speed" 190 "linearly changed from min speed to max speed" 189 "linearly changed from min speed to max speed" 188 "linearly changed from min speed to max speed" 187 "linearly changed from min speed to max speed" 186 "linearly changed from min speed to max speed" 185 "linearly changed from min speed to max speed" 184 "linearly changed from min speed to max speed" 183 "linearly changed from min speed to max speed" 182 "linearly changed from min speed to max speed" 181 "linearly changed from min speed to max speed" 180 "linearly changed from min speed to max speed" 179 "linearly changed from min speed to max speed" 178 "linearly changed from min speed to max speed" 177 "linearly changed from min speed to max speed" 176 "linearly changed from min speed to max speed" 175 "linearly changed from min speed to max speed" 174 "linearly changed from min speed to max speed" 173 "linearly changed from min speed to max speed" 172 "linearly changed from min speed to max speed" 171 "linearly changed from min speed to max speed" 170 "linearly changed from min speed to max speed" 169 "linearly changed from min speed to max speed" 168 "linearly changed from min speed to max speed" 167 "linearly changed from min speed to max speed" 166 "linearly changed from min speed to max speed" 165 "linearly changed from min speed to max speed" 164 "linearly changed from min speed to max speed" 163 "linearly changed from min speed to max speed" 162 "linearly changed from min speed to max speed" 161 "linearly changed from min speed to max speed" 160 "linearly changed from min speed to max speed" 159 "linearly changed from min speed to max speed" 158 "linearly changed from min speed to max speed" 157 "linearly changed from min speed to max speed" 156 "linearly changed from min speed to max speed" 155 "linearly changed from min speed to max speed" 154 "linearly changed from min speed to max speed" 153 "linearly changed from min speed to max speed" 152 "linearly changed from min speed to max speed" 151 "linearly changed from min speed to max speed" 150 "linearly changed from min speed to max speed" 149 "linearly changed from min speed to max speed" 148 "linearly changed from min speed to max speed" 147 "linearly changed from min speed to max speed" 146 "linearly changed from min speed to max speed" 145 "linearly changed from min speed to max speed" 144 "linearly changed from min speed to max speed" 143 "linearly changed from min speed to max speed" 142 "linearly changed from min speed to max speed" 141 "linearly changed from min speed to max speed" 140 "linearly changed from min speed to max speed" 139 "linearly changed from min speed to max speed" 138 "linearly changed from min speed to max speed" 137 "linearly changed from min speed to max speed" 136 "linearly changed from min speed to max speed" 135 "linearly changed from min speed to max speed" 134 "linearly changed from min speed to max speed" 133 "linearly changed from min speed to max speed" 132 "linearly changed from min speed to max speed" 131 "linearly changed from min speed to max speed" 130 "linearly changed from min speed to max speed" 129 "linearly changed from min speed to max speed" 128 "linearly changed from min speed to max speed" 127 "linearly changed from min speed to max speed" 126 "linearly changed from min speed to max speed" 125 "linearly changed from min speed to max speed" 124 "linearly changed from min speed to max speed" 123 "linearly changed from min speed to max speed" 122 "linearly changed from min speed to max speed" 121 "linearly changed from min speed to max speed" 120 "linearly changed from min speed to max speed" 119 "linearly changed from min speed to max speed" 118 "linearly changed from min speed to max speed" 117 "linearly changed from min speed to max speed" 116 "linearly changed from min speed to max speed" 115 "linearly changed from min speed to max speed" 114 "linearly changed from min speed to max speed" 113 "linearly changed from min speed to max speed" 112 "linearly changed from min speed to max speed" 111 "linearly changed from min speed to max speed" 110 "linearly changed from min speed to max speed" 109 "linearly changed from min speed to max speed" 108 "linearly changed from min speed to max speed" 107 "linearly changed from min speed to max speed" 106 "linearly changed from min speed to max speed" 105 "linearly changed from min speed to max speed" 104 "linearly changed from min speed to max speed" 103 "linearly changed from min speed to max speed" 102 "linearly changed from min speed to max speed" 101 "linearly changed from min speed to max speed" 100 "linearly changed from min speed to max speed" 99 "linearly changed from min speed to max speed" 98 "linearly changed from min speed to max speed" 97 "linearly changed from min speed to max speed" 96 "linearly changed from min speed to max speed" 95 "linearly changed from min speed to max speed" 94 "linearly changed from min speed to max speed" 93 "linearly changed from min speed to max speed" 92 "linearly changed from min speed to max speed" 91 "linearly changed from min speed to max speed" 90 "linearly changed from min speed to max speed" 89 "linearly changed from min speed to max speed" 88 "linearly changed from min speed to max speed" 87 "linearly changed from min speed to max speed" 86 "linearly changed from min speed to max speed" 85 "linearly changed from min speed to max speed" 84 "linearly changed from min speed to max speed" 83 "linearly changed from min speed to max speed" 82 "linearly changed from min speed to max speed" 81 "linearly changed from min speed to max speed" 80 "linearly changed from min speed to max speed" 79 "linearly changed from min speed to max speed" 78 "linearly changed from min speed to max speed" 77 "linearly changed from min speed to max speed" 76 "linearly changed from min speed to max speed" 75 "linearly changed from min speed to max speed" 74 "linearly changed from min speed to max speed" 73 "linearly changed from min speed to max speed" 72 "linearly changed from min speed to max speed" 71 "linearly changed from min speed to max speed" 70 "linearly changed from min speed to max speed" 69 "linearly changed from min speed to max speed" 68 "linearly changed from min speed to max speed" 67 "linearly changed from min speed to max speed" 66 "linearly changed from min speed to max speed" 65 "linearly changed from min speed to max speed" 64 "linearly changed from min speed to max speed" 63 "linearly changed from min speed to max speed" 62 "linearly changed from min speed to max speed" 61 "linearly changed from min speed to max speed" 60 "linearly changed from min speed to max speed" 59 "linearly changed from min speed to max speed" 58 "linearly changed from min speed to max speed" 57 "linearly changed from min speed to max speed" 56 "linearly changed from min speed to max speed" 55 "linearly changed from min speed to max speed" 54 "linearly changed from min speed to max speed" 53 "linearly changed from min speed to max speed" 52 "linearly changed from min speed to max speed" 51 "linearly changed from min speed to max speed" 50 "linearly changed from min speed to max speed" 49 "min speed rpm" 48 "min speed rpm" 47 "min speed rpm" 46 "min speed rpm" 45 "min speed rpm" 44 "min speed rpm" 43 "min speed rpm" 42 "min speed rpm" 41 "min speed rpm" 40 "min speed rpm" 39 "min speed rpm" 38 "min speed rpm" 37 "min speed rpm" 36 "min speed rpm" 35 "min speed rpm" 34 "min speed rpm" 33 "min speed rpm" 32 "min speed rpm" 31 "min speed rpm" 30 "min speed rpm" 29 "min speed rpm" 28 "min speed rpm" 27 "min speed rpm" 26 "min speed rpm" 25 "min speed rpm" 24 "min speed rpm" 23 "min speed rpm" 22 "min speed rpm" 21 "min speed rpm" 20 "min speed rpm" 19 "min speed rpm" 18 "min speed rpm" 17 "min speed rpm" 16 "min speed rpm" 15 "min speed rpm" 14 "min speed rpm" 13 "min speed rpm" 12 "min speed rpm" 11 "min speed rpm" 10 "min speed rpm" 9 "min speed rpm" 8 "min speed rpm" 7 "min speed rpm" 6 "min speed rpm" 5 "min speed rpm" 4 "min speed rpm" 3 "0 rpm" 2 "0 rpm" 1 "0 rpm" 0 "0 rpm" ;
VAL_ 596 EWP3_RPM_ActlVal_Stat 255 "Invalid" 254 "max speed rpm" 253 "max speed rpm" 252 "max speed rpm" 251 "max speed rpm" 250 "linearly changed from min speed to max speed" 249 "linearly changed from min speed to max speed" 248 "linearly changed from min speed to max speed" 247 "linearly changed from min speed to max speed" 246 "linearly changed from min speed to max speed" 245 "linearly changed from min speed to max speed" 244 "linearly changed from min speed to max speed" 243 "linearly changed from min speed to max speed" 242 "linearly changed from min speed to max speed" 241 "linearly changed from min speed to max speed" 240 "linearly changed from min speed to max speed" 239 "linearly changed from min speed to max speed" 238 "linearly changed from min speed to max speed" 237 "linearly changed from min speed to max speed" 236 "linearly changed from min speed to max speed" 235 "linearly changed from min speed to max speed" 234 "linearly changed from min speed to max speed" 233 "linearly changed from min speed to max speed" 232 "linearly changed from min speed to max speed" 231 "linearly changed from min speed to max speed" 230 "linearly changed from min speed to max speed" 229 "linearly changed from min speed to max speed" 228 "linearly changed from min speed to max speed" 227 "linearly changed from min speed to max speed" 226 "linearly changed from min speed to max speed" 225 "linearly changed from min speed to max speed" 224 "linearly changed from min speed to max speed" 223 "linearly changed from min speed to max speed" 222 "linearly changed from min speed to max speed" 221 "linearly changed from min speed to max speed" 220 "linearly changed from min speed to max speed" 219 "linearly changed from min speed to max speed" 218 "linearly changed from min speed to max speed" 217 "linearly changed from min speed to max speed" 216 "linearly changed from min speed to max speed" 215 "linearly changed from min speed to max speed" 214 "linearly changed from min speed to max speed" 213 "linearly changed from min speed to max speed" 212 "linearly changed from min speed to max speed" 211 "linearly changed from min speed to max speed" 210 "linearly changed from min speed to max speed" 209 "linearly changed from min speed to max speed" 208 "linearly changed from min speed to max speed" 207 "linearly changed from min speed to max speed" 206 "linearly changed from min speed to max speed" 205 "linearly changed from min speed to max speed" 204 "linearly changed from min speed to max speed" 203 "linearly changed from min speed to max speed" 202 "linearly changed from min speed to max speed" 201 "linearly changed from min speed to max speed" 200 "linearly changed from min speed to max speed" 199 "linearly changed from min speed to max speed" 198 "linearly changed from min speed to max speed" 197 "linearly changed from min speed to max speed" 196 "linearly changed from min speed to max speed" 195 "linearly changed from min speed to max speed" 194 "linearly changed from min speed to max speed" 193 "linearly changed from min speed to max speed" 192 "linearly changed from min speed to max speed" 191 "linearly changed from min speed to max speed" 190 "linearly changed from min speed to max speed" 189 "linearly changed from min speed to max speed" 188 "linearly changed from min speed to max speed" 187 "linearly changed from min speed to max speed" 186 "linearly changed from min speed to max speed" 185 "linearly changed from min speed to max speed" 184 "linearly changed from min speed to max speed" 183 "linearly changed from min speed to max speed" 182 "linearly changed from min speed to max speed" 181 "linearly changed from min speed to max speed" 180 "linearly changed from min speed to max speed" 179 "linearly changed from min speed to max speed" 178 "linearly changed from min speed to max speed" 177 "linearly changed from min speed to max speed" 176 "linearly changed from min speed to max speed" 175 "linearly changed from min speed to max speed" 174 "linearly changed from min speed to max speed" 173 "linearly changed from min speed to max speed" 172 "linearly changed from min speed to max speed" 171 "linearly changed from min speed to max speed" 170 "linearly changed from min speed to max speed" 169 "linearly changed from min speed to max speed" 168 "linearly changed from min speed to max speed" 167 "linearly changed from min speed to max speed" 166 "linearly changed from min speed to max speed" 165 "linearly changed from min speed to max speed" 164 "linearly changed from min speed to max speed" 163 "linearly changed from min speed to max speed" 162 "linearly changed from min speed to max speed" 161 "linearly changed from min speed to max speed" 160 "linearly changed from min speed to max speed" 159 "linearly changed from min speed to max speed" 158 "linearly changed from min speed to max speed" 157 "linearly changed from min speed to max speed" 156 "linearly changed from min speed to max speed" 155 "linearly changed from min speed to max speed" 154 "linearly changed from min speed to max speed" 153 "linearly changed from min speed to max speed" 152 "linearly changed from min speed to max speed" 151 "linearly changed from min speed to max speed" 150 "linearly changed from min speed to max speed" 149 "linearly changed from min speed to max speed" 148 "linearly changed from min speed to max speed" 147 "linearly changed from min speed to max speed" 146 "linearly changed from min speed to max speed" 145 "linearly changed from min speed to max speed" 144 "linearly changed from min speed to max speed" 143 "linearly changed from min speed to max speed" 142 "linearly changed from min speed to max speed" 141 "linearly changed from min speed to max speed" 140 "linearly changed from min speed to max speed" 139 "linearly changed from min speed to max speed" 138 "linearly changed from min speed to max speed" 137 "linearly changed from min speed to max speed" 136 "linearly changed from min speed to max speed" 135 "linearly changed from min speed to max speed" 134 "linearly changed from min speed to max speed" 133 "linearly changed from min speed to max speed" 132 "linearly changed from min speed to max speed" 131 "linearly changed from min speed to max speed" 130 "linearly changed from min speed to max speed" 129 "linearly changed from min speed to max speed" 128 "linearly changed from min speed to max speed" 127 "linearly changed from min speed to max speed" 126 "linearly changed from min speed to max speed" 125 "linearly changed from min speed to max speed" 124 "linearly changed from min speed to max speed" 123 "linearly changed from min speed to max speed" 122 "linearly changed from min speed to max speed" 121 "linearly changed from min speed to max speed" 120 "linearly changed from min speed to max speed" 119 "linearly changed from min speed to max speed" 118 "linearly changed from min speed to max speed" 117 "linearly changed from min speed to max speed" 116 "linearly changed from min speed to max speed" 115 "linearly changed from min speed to max speed" 114 "linearly changed from min speed to max speed" 113 "linearly changed from min speed to max speed" 112 "linearly changed from min speed to max speed" 111 "linearly changed from min speed to max speed" 110 "linearly changed from min speed to max speed" 109 "linearly changed from min speed to max speed" 108 "linearly changed from min speed to max speed" 107 "linearly changed from min speed to max speed" 106 "linearly changed from min speed to max speed" 105 "linearly changed from min speed to max speed" 104 "linearly changed from min speed to max speed" 103 "linearly changed from min speed to max speed" 102 "linearly changed from min speed to max speed" 101 "linearly changed from min speed to max speed" 100 "linearly changed from min speed to max speed" 99 "linearly changed from min speed to max speed" 98 "linearly changed from min speed to max speed" 97 "linearly changed from min speed to max speed" 96 "linearly changed from min speed to max speed" 95 "linearly changed from min speed to max speed" 94 "linearly changed from min speed to max speed" 93 "linearly changed from min speed to max speed" 92 "linearly changed from min speed to max speed" 91 "linearly changed from min speed to max speed" 90 "linearly changed from min speed to max speed" 89 "linearly changed from min speed to max speed" 88 "linearly changed from min speed to max speed" 87 "linearly changed from min speed to max speed" 86 "linearly changed from min speed to max speed" 85 "linearly changed from min speed to max speed" 84 "linearly changed from min speed to max speed" 83 "linearly changed from min speed to max speed" 82 "linearly changed from min speed to max speed" 81 "linearly changed from min speed to max speed" 80 "linearly changed from min speed to max speed" 79 "linearly changed from min speed to max speed" 78 "linearly changed from min speed to max speed" 77 "linearly changed from min speed to max speed" 76 "linearly changed from min speed to max speed" 75 "linearly changed from min speed to max speed" 74 "linearly changed from min speed to max speed" 73 "linearly changed from min speed to max speed" 72 "linearly changed from min speed to max speed" 71 "linearly changed from min speed to max speed" 70 "linearly changed from min speed to max speed" 69 "linearly changed from min speed to max speed" 68 "linearly changed from min speed to max speed" 67 "linearly changed from min speed to max speed" 66 "linearly changed from min speed to max speed" 65 "linearly changed from min speed to max speed" 64 "linearly changed from min speed to max speed" 63 "linearly changed from min speed to max speed" 62 "linearly changed from min speed to max speed" 61 "linearly changed from min speed to max speed" 60 "linearly changed from min speed to max speed" 59 "linearly changed from min speed to max speed" 58 "linearly changed from min speed to max speed" 57 "linearly changed from min speed to max speed" 56 "linearly changed from min speed to max speed" 55 "linearly changed from min speed to max speed" 54 "linearly changed from min speed to max speed" 53 "linearly changed from min speed to max speed" 52 "linearly changed from min speed to max speed" 51 "linearly changed from min speed to max speed" 50 "linearly changed from min speed to max speed" 49 "min speed rpm" 48 "min speed rpm" 47 "min speed rpm" 46 "min speed rpm" 45 "min speed rpm" 44 "min speed rpm" 43 "min speed rpm" 42 "min speed rpm" 41 "min speed rpm" 40 "min speed rpm" 39 "min speed rpm" 38 "min speed rpm" 37 "min speed rpm" 36 "min speed rpm" 35 "min speed rpm" 34 "min speed rpm" 33 "min speed rpm" 32 "min speed rpm" 31 "min speed rpm" 30 "min speed rpm" 29 "min speed rpm" 28 "min speed rpm" 27 "min speed rpm" 26 "min speed rpm" 25 "min speed rpm" 24 "min speed rpm" 23 "min speed rpm" 22 "min speed rpm" 21 "min speed rpm" 20 "min speed rpm" 19 "min speed rpm" 18 "min speed rpm" 17 "min speed rpm" 16 "min speed rpm" 15 "min speed rpm" 14 "min speed rpm" 13 "min speed rpm" 12 "min speed rpm" 11 "min speed rpm" 10 "min speed rpm" 9 "min speed rpm" 8 "min speed rpm" 7 "min speed rpm" 6 "min speed rpm" 5 "min speed rpm" 4 "min speed rpm" 3 "0 rpm" 2 "0 rpm" 1 "0 rpm" 0 "0 rpm" ;
VAL_ 596 EWP3_Curr_Stat 255 "invalid" ;
VAL_ 596 EWP3_OverCurr_Error 3 "Invalid" 2 "SNA" 1 "ERROR" 0 "NO ERROR" ;
VAL_ 596 EWP3_SupVolt_Error 2 "SNA" 1 "ERROR" 0 "NO ERROR" ;
VAL_ 596 EWP3_RsErr_EWP 1 "ERROR" 0 "NO ERROR" ;
VAL_ 596 EWP3_Temp_Stat 255 "Invalid" ;
VAL_ 596 EWP3_Volt_Stat 255 "Invalid" ;
VAL_ 596 EXV2_Rsp_Fault_Stat 15 "not defined" 14 "not defined" 13 "not defined" 12 "not defined" 11 "not defined" 10 "not defined" 9 "not defined" 8 "not defined" 7 "not defined" 6 "not defined" 5 "not defined" 4 "not defined" 3 "Over temperature shutdown" 2 "Motor-Coil open load" 1 "Motor-Coil shorted" 0 "Actuator Not Faulted" ;
VAL_ 596 EXV2_Rsp_CurInit_Stat 3 "Unused and Undefined" 2 "Initialized" 1 "Initialization in Process" 0 "Not Initialized" ;
VAL_ 596 EXV2_Rsp_OvrTemp_Warn 3 "not defined" 2 "not defined" 1 "High Temperature Warning" 0 "Ok" ;
VAL_ 596 EXV2_Rsp_Volt_Stat 3 "not defined" 2 "Under voltage" 1 "Overvoltage" 0 "Voltage Range ok" ;
VAL_ 596 EXV2_RsErr_EXV 1 "Comm Error detected" 0 "No Comm Error" ;
VAL_ 596 EXV2_Rsp_Run_Stat 1 "Actuator is moving" 0 "Actuator is not moving" ;
VAL_ 596 CCV4_Fault_Signal 4 "Coil Short Detected" 3 "OverTemp Shutdown" 2 "Stall Detected" 1 "Coil_Open Detected" 0 "No Fault" ;
VAL_ 596 BDC_1_Rsp_Comm_Err 1 "LIN Communication Error" 0 "No Error" ;
VAL_ 596 CCV4_TempWarn 1 "Temperature Warning" 0 "No Error" ;
VAL_ 596 CCV4_Rsp_Comm_Err 1 "LIN Communication Error" 0 "No Error" ;
VAL_ 596 CCV4_MotorStatus 1 "Motor Running" 0 "Motor Stop" ;
VAL_ 596 CCV4_RespPos 3 "Valve is opening" 2 "Valve is closing" 1 "Open Port 1 to Port 4, Port 2 to port 3" 0 "Open Port 1 to Port 2, Port 3 to port 4" ;
VAL_ 596 CCV4_voltageErr 2 "lackvoltage" 1 "overvoltage" 0 "No Error" ;
VAL_ 596 BDC_1_Fault_Signal 4 "Coil Short Detected" 3 "OverTemp Shutdown" 2 "Stall Detected" 1 "Coil_Open Detected" 0 "No Fault" ;
VAL_ 596 BDC_1_voltageErr 2 "lackvoltage" 1 "overvoltage" 0 "No Error" ;
VAL_ 596 BDC_1_TempWarn 1 "Temperature Warning" 0 "No Error" ;
VAL_ 596 BDC_1_MotorStatus 1 "Motor Running" 0 "Motor Stop" ;
VAL_ 778 EAC_Temp 255 "Invalid" 1 "Fault" 0 "Normal" ;
VAL_ 778 PTCNTCStsHSC6 7 "all sensor bad" 6 "igbt sensor good , ptc in sensor bad  , ptc out sensor bad" 5 "igbt sensor bad , ptc in sensor good , ptc out sensor bad" 4 "igbt sensor good , ptc in sensor good , ptc out sensor bad" 3 "igbt sensor bad , ptc in sensor bad , ptc_out_sensor good" 2 "igbt sensor good , ptc in sensor bad , ptc_out_sensor good" 1 "igbt sensor bad , ptc in sensor good , ptc out sensor good" 0 "all sensor is good" ;
VAL_ 778 EAC_DrvVoltFalt 1 "Fault" 0 "Normal" ;
VAL_ 778 EAC_MotorLackFalt 1 "Fault" 0 "Normal" ;
VAL_ 778 EAC_OvLoadFalt 1 "Fault" 0 "Normal" ;
VAL_ 778 EAC_TempSnsrFalt 1 "Fault" 0 "Normal" ;
VAL_ 778 COMP_ComLost 1 "Fault" 0 "Normal" ;
VAL_ 778 COMP_IPM_HWFLt 1 "Fault" 0 "Normal" ;
VAL_ 778 COMP_IPM_TempOverFlt 1 "Fault" 0 "Normal" ;
VAL_ 778 COMP_CurOverProtect 1 "Fault" 0 "Normal" ;
VAL_ 778 COMP_VoltOverErr 1 "Fault" 0 "Normal" ;
VAL_ 778 COMP_VoltLessErr 1 "Fault" 0 "Normal" ;
VAL_ 778 COMP_CtrlCircFlt 1 "Fault" 0 "Normal" ;
VAL_ 778 COMP_Sta 3 "Limit state" 2 "Fault" 1 "Working" 0 "Standby" ;
VAL_ 778 COMP_Init 1 "Init Complete" 0 "Initializing" ;
VAL_ 778 COMP_SpdVaild 1 "invaild" 0 "valid" ;
VAL_ 778 COMP_CurVaild 1 "invaild" 0 "valid" ;
VAL_ 778 COMP_VoltVaild 1 "invaild" 0 "valid" ;
VAL_ 778 COMP_StatorSpd 16383 "Invalid" ;
VAL_ 778 PTCOverVolHSC6 1 "Actived" 0 "Inactived" ;
VAL_ 778 PTCOverCrntHSC6 1 "Actived" 0 "Inactived" ;
VAL_ 778 PTCOverHeatHSC6 1 "Actived" 0 "Inactived" ;
VAL_ 778 PTCIGBTStsHSC6 1 "Fault" 0 "Normal" ;
VAL_ 778 PTCHVLckStsHSC6 1 "Fault" 0 "OK" ;
VAL_ 778 PTCIGBTOverHeatHSC6 1 "over heat" 0 "igbt good" ;
VAL_ 778 PTCUnderVolHSC6 1 "Actived" 0 "Inactived" ;
VAL_ 778 PTCStsHSC6 3 "Prepare to Start" 2 "Emergency Stop" 1 "Working" 0 "Not Working" ;
VAL_ 778 PTCFltLvlHSC6 3 "LEVEL 3" 2 "LEVEL 2" 1 "LEVEL 1" 0 "LEVEL 0" ;
VAL_ 778 COMP_ActualPwr 8191 "Invalid" ;
VAL_ 1284 NM_ZONE_FR_PNI 1 "NM PDU contains Partial Network request information" 0 "NM PDU contains no Partial Network request information" ;
VAL_ 1284 NM_ZONE_FR_Active_WU 1 "Node has woken up the network (active Wakeup)" 0 "Node has not woken up the network (passive wakeup)" ;
VAL_ 1284 NM_ZONE_FR_CSB 1 "Start of synchronized shutdown is requested by main coordinator" 0 "Start of synchronized shutdown is not requested by main coordinator" ;
VAL_ 1284 NM_ZONE_FR_Rpt_Msg_Req 1 "Repeat Message State requested" 0 "Repeat Message State not requested" ;
VAL_ 1284 NM_ZONE_FR_ERROR_State 8 "BUS OFF_L2" 4 "BUS OFF_L1" 2 "ERROR PASSIVE" 1 "ERROR ACTIVE" 0 "Inactive" ;
VAL_ 1285 NM_DKC_PNI 1 "NM PDU contains Partial Network request information" 0 "NM PDU contains no Partial Network request information" ;
VAL_ 1285 NM_DKC_Active_WU 1 "Node has woken up the network (active Wakeup)" 0 "Node has not woken up the network (passive wakeup)" ;
VAL_ 1285 NM_DKC_CSB 1 "Start of synchronized shutdown is requested by main coordinator" 0 "Start of synchronized shutdown is not requested by main coordinator" ;
VAL_ 1285 NM_DKC_Rpt_Msg_Req 1 "Repeat Message State requested" 0 "Repeat Message State not requested" ;
VAL_ 1285 NM_DKC_ERROR_State 8 "BUS OFF_L2" 4 "BUS OFF_L1" 2 "ERROR PASSIVE" 1 "ERROR ACTIVE" 0 "Inactive" ;
VAL_ 1344 NM_ZONE_DR_PNI 1 "NM PDU contains Partial Network request information" 0 "NM PDU contains no Partial Network request information" ;
VAL_ 1344 NM_ZONE_DR_Active_WU 1 "Node has woken up the network (active Wakeup)" 0 "Node has not woken up the network (passive wakeup)" ;
VAL_ 1344 NM_ZONE_DR_CSB 1 "Start of synchronized shutdown is requested by main coordinator" 0 "Start of synchronized shutdown is not requested by main coordinator" ;
VAL_ 1344 NM_ZONE_DR_Rpt_Msg_Req 1 "Repeat Message State requested" 0 "Repeat Message State not requested" ;
VAL_ 1344 NM_ZONE_DR_ERROR_State 8 "BUS OFF_L2" 4 "BUS OFF_L1" 2 "ERROR PASSIVE" 1 "ERROR ACTIVE" 0 "Inactive" ;
VAL_ 630 OBCACCSLimit 255 "Invalid" ;
VAL_ 630 ReChargerStaFromEvcc 3 "Invalid" 2 "Untrusted" 1 "On" 0 "Off" ;
VAL_ 630 OBCEna 1 "Start charging" 0 "Stop charging" ;
VAL_ 928 FDC_VCU_ReqHWReset_Cmd 25 "EBM power off" 24 "ECompressor power off" 23 "WPTC power off" 22 "HMI power off" 21 "TBox power off" 20 "IVI power off" 19 "AirPTC power off" 18 "PSEAT power off" 17 "DSEAT power off" 16 "ABM power off" 15 "EPS power off" 14 "BMS power off" 13 "EOP_F power off" 12 "EOP_R power off" 11 "CCU power off" 10 "DKC power off" 9 "MRR power off" 8 "SRR_M power off" 7 "FCM power off" 6 "MCU_F power off" 5 "MCU_R power off" 4 "Shifter power off" 3 "Telltale power off" 2 "EBST power off" 1 "ESC power off" 0 "No request" ;
VAL_ 597 IVI_MLSEATvent_Cmd 4 "OFF" 3 "3(High)" 2 "2(Middle)" 1 "1(Low)" 0 "NoRequest" ;
VAL_ 597 IVI_MRSEATvent_Cmd 4 "OFF" 3 "3(High)" 2 "2(Middle)" 1 "1(Low)" 0 "NoRequest" ;
VAL_ 597 IVI_MLFootLift_Cmd 2 "Down" 1 "Up" 0 "StandBy" ;
VAL_ 597 IVI_MLRecliner_Cmd 2 "Backward" 1 "Forward" 0 "StandBy" ;
VAL_ 597 IVI_MLSeatLift_Cmd 2 "Down" 1 "Up" 0 "StandBy" ;
VAL_ 597 IVI_MLSlider_Cmd 2 "Backward" 1 "Forward" 0 "StandBy" ;
VAL_ 597 IVI_MRFootLift_Cmd 2 "Down" 1 "Up" 0 "StandBy" ;
VAL_ 597 IVI_MRRecliner_Cmd 2 "Backward" 1 "Forward" 0 "StandBy" ;
VAL_ 597 IVI_MRSeatLift_Cmd 2 "Down" 1 "Up" 0 "StandBy" ;
VAL_ 597 IVI_MRSlider_Cmd 2 "Backward" 1 "Forward" 0 "StandBy" ;
VAL_ 597 IVI_MLFMost_Cmd 1 "Press" 0 "Release" ;
VAL_ 597 IVI_MLNapMode_Cmd 1 "Press" 0 "Release" ;
VAL_ 597 IVI_MLRestore_Cmd 1 "Press" 0 "Release" ;
VAL_ 597 IVI_MLSldRestore_Cmd 1 "Press" 0 "Release" ;
VAL_ 597 IVI_MLZeroGravity_Cmd 1 "Press" 0 "Release" ;
VAL_ 597 IVI_MRFMost_Cmd 1 "Press" 0 "Release" ;
VAL_ 597 IVI_MRNapMode_Cmd 1 "Press" 0 "Release" ;
VAL_ 597 IVI_MRRestore_Cmd 1 "Press" 0 "Release" ;
VAL_ 597 IVI_MRSldRestore_Cmd 1 "Press" 0 "Release" ;
VAL_ 597 IVI_MRZeroGravity_Cmd 1 "Press" 0 "Release" ;
VAL_ 597 IVI_LSEATvent_Cmd 4 "OFF" 3 "3(High)" 2 "2(Middle)" 1 "1(Low)" 0 "NoRequest" ;
VAL_ 597 IVI_RSEATvent_Cmd 4 "OFF" 3 "3(High)" 2 "2(Middle)" 1 "1(Low)" 0 "NoRequest" ;
VAL_ 513 FDC_BCM_TurnLpLActive_Cmd 1 "On" 0 "Off" ;
VAL_ 513 FDC_BCM_TurnLpRActive_Cmd 1 "On" 0 "Off" ;
VAL_ 513 FDC_BCM_STurnLpLeft_Cmd 1 "On" 0 "Off" ;
VAL_ 513 FDC_BCM_STurnLpRight_Cmd 1 "On" 0 "Off" ;
VAL_ 513 FDC_BCM_LSMLP_Cmd 1 "On" 0 "Off" ;
VAL_ 513 FDC_BCM_RSMLP_Cmd 1 "On" 0 "Off" ;
VAL_ 513 FDC_BCM_BBuzzer_Cmd 1 "On" 0 "Off" ;
VAL_ 513 FDC_BCM_BBuzzerout_Cmd 1 "On" 0 "Off" ;
VAL_ 513 FDC_BCM_RevBuzzerout_Cmd 1 "On" 0 "Off" ;
VAL_ 513 FDC_BCM_innerBuzzer_Cmd 1 "On" 0 "Off" ;
VAL_ 513 FDC_BCM_EmExitLight_Cmd 1 "On" 0 "Off" ;
VAL_ 513 FDC_BCM_FrRoomlamp_Cmd 1 "On" 0 "Off" ;
VAL_ 513 FDC_BCM_RrRoomlamp_Cmd 1 "On" 0 "Off" ;
VAL_ 513 FDC_BCM_FrAtmoLamp_Cmd 1 "On" 0 "Off" ;
VAL_ 513 FDC_BCM_RrAtmoLamp_Cmd 1 "On" 0 "Off" ;
VAL_ 513 FDC_BCM_FrRmLampBright_Cmd 15 "Invalid" 14 "Dome mode 3" 13 "Dome mode 2" 12 "Dome mode 1" 11 "Level11" 10 "Level10" 9 "Level9" 8 "Level8" 7 "Level7" 6 "Level6" 5 "Level5" 4 "Level4" 3 "Level3" 2 "Level2" 1 "Level1" 0 "No Request" ;
VAL_ 513 FDC_BCM_RrRmLampBright_Cmd 15 "Invalid" 14 "Dome mode 3" 13 "Dome mode 2" 12 "Dome mode 1" 11 "Level11" 10 "Level10" 9 "Level9" 8 "Level8" 7 "Level7" 6 "Level6" 5 "Level5" 4 "Level4" 3 "Level3" 2 "Level2" 1 "Level1" 0 "No Request" ;
VAL_ 513 FDC_BCM_IBuzzerReq_Sta 5 "VCU Request" 4 "Seat Belt UnFasten" 3 "Fire Disaster" 2 "TA Buzzer" 1 "Emergency Exit Open" 0 "OFF" ;
VAL_ 513 FDC_BCM_TgateHDSWR_Sta 1 "Press" 0 "Release" ;
VAL_ 513 FDC_BCM_TgateHDSWL_Sta 1 "Press" 0 "Release" ;
VAL_ 513 FDC_BCM_TgateSWL_Sta 1 "Open" 0 "Close" ;
VAL_ 513 FDC_BCM_TgateSWR_Sta 1 "Open" 0 "Close" ;
VAL_ 513 FDC_BCM_RTgateRel_Cmd 1 "Release" 0 "OFF" ;
VAL_ 513 FDC_BCM_LTgateRel_Cmd 1 "Release" 0 "OFF" ;
VAL_ 515 Z24_BCM_FWiperProtection_Sta 1 "In protection" 0 "Not in Protectio" ;
VAL_ 515 Z24_BCM_FWiperAS_Sta 1 "Not at Stop Position" 0 "Stop Position" ;
VAL_ 515 Z24_BCM_EmExitOP_Sta 1 "ON" 0 "OFF" ;
VAL_ 515 Z24_BCM_innerBuzzer_Sta 1 "ON" 0 "OFF" ;
VAL_ 515 Z24_BCM_SeatBeltSW_Sta 1 "fasten" 0 "Unfasten" ;
VAL_ 2566827568 Z24_CHA_AirPressurePC3_Sta 176 "Invalid Value" ;
VAL_ 2566827568 Z24_CHA_AirPressureRC1_Sta 176 "Invalid Value" ;
VAL_ 2566827568 Z24_CHA_AirPressureFC2_Sta 176 "Invalid Value" ;
VAL_ 514 FDC_CHA_EACEnDemand_Cmd 170 "shut down" 85 "start" ;
